VERSION ""

NS_ :

BS_:

BU_: TCM HCM IPMA_ADAS PSCM ABS_ESC TCCM TCM_DSL PCM_HEV PCM ECM_HEVDSL ECM_HEV ECM_Diesel ECM SIMA_DLCS BCMD_IPDB VDM CMR_DSMC SOBDMC_HPCM_FD1 CHCM GWM _delete AWD_DLCM GENERIC TSTR
VAL_TABLE_ _S_Off_On 1 "On" 0 "Off" ;
VAL_TABLE_ _S_InactiveActive 1 "Active" 0 "Inactive" ;
VAL_TABLE_ DcacRdy_D_Stat 7 "NotUsed_2" 6 "NotUsed_1" 5 "Faulted" 4 "ProtectionTempearture" 3 "ProtectionOverload" 2 "ProtectionGfci" 1 "Active" 0 "Idle" ;
VAL_TABLE_ HvacCmprLim_D_Stat 7 "NotUsed_2" 6 "NotUsed_1" 5 "CompressorHeadPressure" 4 "AvailableTorque" 3 "PedalPosition" 2 "RPM" 1 "ECT" 0 "NoLimit" ;
VAL_TABLE_ EvseDcChrgIso_D_Stat 7 "Faulty" 6 "NoDataExists" 5 "NotUsed_3" 4 "NotUsed_2" 3 "NotUsed_1" 2 "Valid" 1 "Warning" 0 "Invalid" ;
VAL_TABLE_ PtRmtRprt_D_Stat 15 "NotUsed_4" 14 "NotUsed_3" 13 "NotUsed_2" 12 "NotUsed_1" 11 "SettingUpdated" 10 "FastChargeComplete" 9 "ChargeNotOccurring" 8 "OneTimeSocReached" 7 "BatteryTemperatureRemind" 6 "ReducedPerformance" 5 "LimitedPerformance" 4 "ChargeFault" 3 "ChargeComplete" 2 "VehiclePreconditioned" 1 "TripDistanceAchieved" 0 "NoReportRequest" ;
VAL_TABLE_ VehOnSrc_D_Stat 15 "NotUsed_11" 14 "NotUsed_10" 13 "NotUsed_9" 12 "NotUsed_8" 11 "NotUsed_7" 10 "NotUsed_6" 9 "NotUsed_5" 8 "NotUsed_4" 7 "SecureIdle" 6 "FleetVehicleInhibit" 5 "StolenVehicleInhibit" 4 "OverTheAir" 3 "RemoteParkAssist" 2 "RemoteStart" 1 "Manual" 0 "Off" ;
VAL_TABLE_ OfbChrgSetSync_D_Rq 3 "Fail" 2 "Success" 1 "InProgress" 0 "NoSyncInProgress" ;
VAL_TABLE_ NoMessage_Msg1_63 31 "Message31" 30 "Message30" 29 "Message29" 28 "Message28" 27 "Message27" 26 "Message26" 25 "Message25" 24 "Message24" 23 "Message23" 22 "Message22" 21 "Message21" 20 "Message20" 19 "Message19" 18 "Message18" 17 "Message17" 16 "Message16" 15 "Message15" 14 "Message14" 13 "Message13" 12 "Message12" 11 "Message11" 10 "Message10" 9 "Message9" 8 "Message8" 7 "Message7" 6 "Message6" 5 "Message5" 4 "Message4" 3 "Message3" 2 "Message2" 1 "Message1" 0 "NoMessage" 63 "Message63" 47 "Message47" ;
VAL_TABLE_ TrlrRvrseEnbl_D2_Stat 7 "NotUsed" 6 "TbaActiveExpertActive" 5 "TbaActiveExpertAvail" 4 "TbaOffTrgActive" 3 "TbaOffTrgSetup" 2 "TbaSetup" 1 "TbaActive" 0 "Inactive" ;
VAL_TABLE_ Off_On_FlashChime 7 "NotUsed_5" 6 "NotUsed_4" 5 "NotUsed_3" 4 "NotUsed_2" 3 "NotUsed_1" 2 "FlashChime" 1 "On" 0 "Off" ;
VAL_TABLE_ DieslPrtcWarn_D_Rq 15 "NotUsed_4" 14 "NotUsed_3" 13 "NotUsed_2" 12 "NotUsed_1" 11 "OCR_ExhFilterClean_Stopped" 10 "OCR_ExhFilterCleaned" 9 "RgnOff_AtLimit" 8 "RgnOff_OverLoaded" 7 "RgnOff_Loaded" 6 "Exhaust_Filter_Full" 5 "DPF_OverLimit" 4 "DPF_AtLimit" 3 "ExhFilter_Drive_Completed" 2 "Cleaning_Exhaust_Filter" 1 "DPF_OverLoaded" 0 "DPF_Normal_Operation" ;
VAL_TABLE_ StrtrMtrCtlMsgTxt_D2_Rq 3 "NoRequestPcmStartingMsgCtl" 2 "ShiftToNeutralToStart" 1 "ShiftToParkToStart" 0 "NoRequestBcmStartingMsgCtl" ;
VAL_TABLE_ PaakMyKey_D_Rq 3 "NotUsed" 2 "ConfirmNewPaakMyKey" 1 "RequestNewPaakMyKey" 0 "None" ;
VAL_TABLE_ PaakMyKeySearch_D_Stat 7 "PhoneErased" 6 "LockButtonTimeOut" 5 "PressLockButton" 4 "ConfirmHmi" 3 "MyKeyPaakFound" 2 "StandardPaakFound" 1 "NoValidPaakFound" 0 "Null" ;
VAL_TABLE_ GearPrkLck_D_Stat 7 "NotUsed_1" 6 "FetLifeLimitReached" 5 "FetOpenCircuit" 4 "FetOutputShortToPower" 3 "FetOutputShortToGround" 2 "FetNotControlled" 1 "OnPowerToLoad" 0 "OffNoPowerToLoad" ;
VAL_TABLE_ DcChrgRdy_D_Stat 15 "Faulty" 14 "NotUsed_4" 13 "NotUsed_3" 12 "NotUsed_2" 11 "CableCheck" 10 "EvseFault" 9 "EvseNotCompatible" 8 "EvsePaused" 7 "GbtPrecharge" 6 "ChargeComplete" 5 "Charging" 4 "Precharge" 3 "WeldCheck" 2 "ChargeReady" 1 "Initialization" 0 "NotReady" ;
VAL_TABLE_ TrlrIdType_D_Stat 3 "Gooseneck" 2 "FifthWheel" 1 "Conventional" 0 "Null" ;
VAL_TABLE_ TrlrAidSetup_D2_Rq 15 "NotUsed_9" 14 "NotUsed_8" 13 "NotUsed_7" 12 "NotUsed_6" 11 "NotUsed_5" 10 "NotUsed_4" 9 "NotUsed_3" 8 "NotUsed_2" 7 "NotUsed_1" 6 "CompleteSetup" 5 "ReturnToSetup" 4 "StickerNotCircled" 3 "ConfirmSetup" 2 "EndSetup" 1 "BeginSetup" 0 "Inactive" ;
VAL_TABLE_ TrlrAidEnbl_D2_Rq 7 "NotUsed_4" 6 "NotUsed_3" 5 "NotUsed_2" 4 "NotUsed_1" 3 "Deactivate" 2 "ActivateTrg" 1 "ActivateTba" 0 "Inactive" ;
VAL_TABLE_ SwitchNotActive_Active 1 "Switch_Active" 0 "Switch_Not_Active" ;
VAL_TABLE_ DgtlCommGtwyMde_D_Stat 11 "NotUsed_3" 10 "DgtlCommFailed" 9 "DgtlCommEstablished" 8 "Inactive" 7 "RestartRequest" 6 "AcPnc_Eim" 5 "AcPnc" 4 "AcEim" 3 "DcPnc_Eim" 2 "DcPnc" 1 "DcEim" 0 "NotDetected" 15 "NotUsed_7" 14 "NotUsed_6" 13 "NotUsed_5" 12 "NotUsed_4" ;
VAL_TABLE_ InvalidValidWarningFaulty 3 "Faulty" 2 "Warning" 1 "Valid" 0 "Invalid" ;
VAL_TABLE_ BattChrgMde_D_Actl 3 "NotUsed" 2 "ConstantCurrent" 1 "ConstantVoltage" 0 "NotCharging" ;
VAL_TABLE_ LcwaMsgTxt_D_Stat 3 "SodXFaulty" 2 "SodXBlocked" 1 "TrailerConnected" 0 "NoMessage" ;
VAL_TABLE_ Level_0_3 3 "Level_3" 2 "Level_2" 1 "Level_1" 0 "Level_0" ;
VAL_TABLE_ SteWhlSwtchMde_D_Stat 3 "NotUsed_2" 2 "NotUsed_1" 1 "Dialog" 0 "Domain" ;
VAL_TABLE_ TrlrRvrse_D_Stat 3 "Faulty" 2 "TrailerReverseGuidanceLite" 1 "On" 0 "Off" ;
VAL_TABLE_ TrlrAid_D2_Stat 15 "Faulty" 14 "NotUsed_4" 13 "NotUsed_3" 12 "NotUsed_2" 11 "NotUsed_1" 10 "DirtyCamera" 9 "IncorrectLighting" 8 "TrackingLost" 7 "TrackingUnknownConfidence" 6 "TrackingHighConfidence" 5 "TrackingMediumConfidence" 4 "TrackingLowConfidence" 3 "TurnRequested" 2 "DriveStraighRequested" 1 "Initializing" 0 "NotTracking" ;
VAL_TABLE_ AwdDrvMde_D2 15 "Faulty" 14 "NotUsed_7" 13 "NotUsed_6" 12 "NotUsed_5" 11 "NotUsed_4" 10 "NotUsed_3" 9 "NotUsed_2" 8 "NotUsed_1" 7 "NotAvailable" 6 "TowHaul" 5 "RockCrawl" 4 "Baja" 3 "MudAndSand" 2 "Weather" 1 "Sport" 0 "Normal" ;
VAL_TABLE_ TrlrAidSetup_D2_Stat 7 "NotUsed_2" 6 "NotUsed_1" 5 "SetupAcquisitionSuccess" 4 "TbaTadMonitor" 3 "SetupStartAcquisition" 2 "SetupPrepForAcquisition" 1 "TbaActive" 0 "Null" ;
VAL_TABLE_ CamraRearOn_D2_Stat2 7 "Faulty" 6 "NotUsed_3" 5 "NotUsed_2" 4 "NotUsed_1" 3 "Decommission" 2 "Activate" 1 "Deactivate" 0 "Null" ;
VAL_TABLE_ AirCondClu_D_Stat 7 "NotUsed" 6 "FetLifeLimitReached" 5 "FetOpenCircuit" 4 "FetOutputShortToPower" 3 "FetOutputShortToGround" 2 "FetNotControlled" 1 "OnPowerToLoad" 0 "OffNoPowerToLoad" ;
VAL_TABLE_ BattChrgTrgtSoC_D_Rq 7 "Percent_50" 6 "Percent_60" 5 "Percent_70" 4 "Percent_80" 3 "Percent_85" 2 "Percent_90" 1 "Percent_95" 0 "Percent_100" ;
VAL_TABLE_ OffNormalSoft 3 "NotUsed" 2 "Soft" 1 "Normal" 0 "Off" ;
VAL_TABLE_ OffOnDisabledInhibited 3 "Inhibited" 2 "Disabled" 1 "On" 0 "Off" ;
VAL_TABLE_ DgtlCommGtwyMde_D_Rq 15 "NotUsed_10" 14 "NotUsed_9" 13 "NotUsed_8" 12 "NotUsed_7" 11 "NotUsed_6" 10 "NotUsed_5" 9 "NotUsed_4" 8 "NotUsed_3" 7 "NotUsed_2" 6 "NotUsed_1" 5 "AcPnC" 4 "AcEIM" 3 "DcPnC" 2 "DcEIM" 1 "AttemptDgtlComm" 0 "NoDgtlComm" ;
VAL_TABLE_ BattDcCnnct_D_Cmd 7 "NotUsed_3" 6 "NotUsed_2" 5 "NotUsed_1" 4 "WeldCheck" 3 "OkToDischarge" 2 "Closed" 1 "Precharge" 0 "Open" ;
VAL_TABLE_ Null_NoFault_Fault 3 "NotUsed" 2 "Fault" 1 "NoFault" 0 "Null" ;
VAL_TABLE_ ModemReset_D_Stat 15 "NotUsed_10" 14 "NotUsed_9" 13 "NotUsed_8" 12 "NotUsed_7" 11 "NotUsed_6" 10 "NotUsed_5" 9 "NotUsed_4" 8 "NotUsed_3" 7 "NotUsed_2" 6 "NotUsed_1" 5 "WifiHotSpotResetComplete" 4 "CcsResetComplete" 3 "OnlineTrafficResetComplete" 2 "PaakResetComplete" 1 "ResetNotComplete" 0 "Null" ;
VAL_TABLE_ ModemReset_D_Rq 15 "NotUsed_11" 14 "NotUsed_10" 13 "NotUsed_9" 12 "NotUsed_8" 11 "NotUsed_7" 10 "NotUsed_6" 9 "NotUsed_5" 8 "NotUsed_4" 7 "NotUsed_3" 6 "BrandConnectReset2" 5 "BrandConnectReset1" 4 "CcsReset" 3 "OnlineTrafficReset" 2 "PaakReset" 1 "WifiHotspotReset" 0 "Null" ;
VAL_TABLE_ RstrnOnPsngr_D_RqMnu 15 "Faulty" 14 "NotUsed_11" 13 "NotUsed_10" 12 "ConfiguredOff" 11 "NotUsed_9" 10 "On" 9 "NotUsed_8" 8 "NotUsed_7" 7 "NotUsed_6" 6 "NotUsed_5" 5 "Off" 4 "NotUsed_4" 3 "NotUsed_3" 2 "NotUsed_2" 1 "NotUsed_1" 0 "NoAction" ;
VAL_TABLE_ NoReq_AutoUp_Stop 3 "NotUsed" 2 "Stop" 1 "AutoUp" 0 "NoRequest" ;
VAL_TABLE_ BalrSnsLeft_D_Falt 3 "Invalid" 2 "SystemFailure" 1 "Blocked" 0 "Clear" ;
VAL_TABLE_ Null_Low_Med_High 3 "High" 2 "Medium" 1 "Low" 0 "Null" ;
VAL_TABLE_ Null_NotPressed_Pressed 3 "NotUsed" 2 "Pressed" 1 "NotPressed" 0 "Null" ;
VAL_TABLE_ Low_Med_High 3 "NotUsed" 2 "High" 1 "Medium" 0 "Low" ;
VAL_TABLE_ Null_NotAvail_Avail 3 "NotUsed" 2 "Available" 1 "NotAvailable" 0 "Null" ;
VAL_TABLE_ ChrgToPcWkndSav_D_Stat 7 "Percent_50" 6 "Percent_60" 5 "Percent_70" 4 "Percent_80" 3 "Percent_85" 2 "Percent_90" 1 "Percent_95" 0 "Percent_100" ;
VAL_TABLE_ ChrgGoTMnte_D_Stat 15 "NotUsed_4" 14 "NotUsed_3" 13 "NotUsed_2" 12 "NotUsed_1" 11 "Minute_55" 10 "Minute_50" 9 "Minute_45" 8 "Minute_40" 7 "Minute_35" 6 "Minute_30" 5 "Minute_25" 4 "Minute_20" 3 "Minute_15" 2 "Minute_10" 1 "Minute_5" 0 "Minute_0" ;
VAL_TABLE_ NoData_Faulty_1E_1F 31 "Faulty" 30 "NoDataExists" ;
VAL_TABLE_ PwFlwBatt_D_Dsply 15 "NotUsed_8" 14 "NotUsed_7" 13 "NotUsed_6" 12 "NotUsed_5" 11 "NotUsed_4" 10 "NotUsed_3" 9 "NotUsed_2" 8 "NotUsed_1" 7 "FlwFromWallToBatt" 6 "FlwFromAllWhlsToBatt" 5 "FlwFromBattToAllWhls" 4 "FlwFromFrontWhlsToBatt" 3 "FlwFromBattToFrontWhls" 2 "FlwFromRearWhlsToBatt" 1 "FlwFromBattToRearWhls" 0 "NoFlow" ;
VAL_TABLE_ PwFlwFuelDrv_D_Dsply 7 "NotUsed_4" 6 "NotUsed_3" 5 "NotUsed_2" 4 "NotUsed_1" 3 "FlwFromFuelToAllWhls" 2 "FlwFromFuelToFrontWhls" 1 "FlwFromFuelToRearWhls" 0 "NoFlow" ;
VAL_TABLE_ TrlrAidMsgTxt_D2_Rq 63 "Message63" 62 "Message62" 61 "Message61" 60 "Message60" 55 "Message55" 50 "Message50" 45 "Message45" 40 "Message40" 35 "Message35" 31 "Message31" 30 "Message30" 29 "Message29" 28 "Message28" 27 "Message27" 26 "Message26" 25 "Message25" 24 "Message24" 23 "Message23" 22 "Message22" 21 "Message21" 20 "Message20" 19 "Message19" 18 "Message18" 17 "Message17" 16 "Message16" 15 "Message15" 14 "Message14" 13 "Message13" 12 "Message12" 11 "Message11" 10 "Message10" 9 "Message9" 8 "Message8" 7 "Message7" 6 "Message6" 5 "Message5" 4 "Message4" 3 "Message3" 2 "Message2" 1 "Message1" 0 "NoMessage" ;
VAL_TABLE_ TrlrAidEnbl_D2_Stat 7 "NotUsed_1" 6 "TbaActiveExpertActive" 5 "TbaActiveExpertAvail" 4 "TbaOffTrgActive" 3 "TbaOffTrgSetup" 2 "TbaSetup" 1 "TbaActive" 0 "Inactive" ;
VAL_TABLE_ NoRequest_Mode1_2_3 3 "Mode_3" 2 "Mode_2" 1 "Mode_1" 0 "NoRequest" ;
VAL_TABLE_ RvltnMatchAllw_D_Stat 3 "RevolutionMatchDisabled" 2 "RevolutionMatchEnabled" 1 "ChangeWithDriveMode" 0 "NoSelection" ;
VAL_TABLE_ BattTracCnnct_D_Cmd 7 "NotUsed_3" 6 "NotUsed_2" 5 "NotUsed_1" 4 "WeldCheck" 3 "OkToDischarge" 2 "Closed" 1 "Precharge" 0 "Open" ;
VAL_TABLE_ NotDiagnose_FailPass 3 "NotUsed" 2 "Pass" 1 "Fail" 0 "Not_Diagnose_Yet" ;
VAL_TABLE_ Null_Off_UnavailFaulty 3 "Faulty" 2 "Unavailable" 1 "Off" 0 "Null" ;
VAL_TABLE_ OffOnDisabledNotUsed 3 "NotUsed" 2 "Disabled" 1 "On" 0 "Off" ;
VAL_TABLE_ OffGraphicTextBoth 3 "Both" 2 "Text" 1 "Graphic" 0 "Off" ;
VAL_TABLE_ NoneInactiveActive_NotUsed 3 "NotUsed" 2 "Active" 1 "Inactive" 0 "None" ;
VAL_TABLE_ Off_On_NotUsed 3 "NotUsed_2" 2 "NotUsed_1" 1 "On" 0 "Off" ;
VAL_TABLE_ OffNoPowerToLoad 7 "NotUsed_1" 6 "FetLifeLimitReached" 5 "FetOpenCircuit" 4 "FetOutputShortToPower" 3 "FetOutputShortToGround" 2 "FetNotControlled" 1 "OnPowerToLoad" 0 "OffNoPowerToLoad" ;
VAL_TABLE_ BrkAppl_D_RqPt 3 "BrakesSlowRelease" 2 "BrakesFastRelease" 1 "BrakesEngage" 0 "NotActive" ;
VAL_TABLE_ Mtr2State_D_ActlMntr 7 "Faulty" 6 "NoDataExists" 5 "NotUsed_1" 4 "ReadinessState" 3 "DeactivationState" 2 "PowerGeneration" 1 "PowerConsumption" 0 "Null" ;
VAL_TABLE_ HybVehMde_D_ActlMntr 7 "Faulty" 6 "NoDataExists" 5 "NotUsed_2" 4 "NotUsed_1" 3 "Fuel" 2 "HybridElectric" 1 "AllElectric" 0 "Null" ;
VAL_TABLE_ ChrgStat_D_ActlMntr 7 "Faulty" 6 "NoDataExists" 5 "NotUsed" 4 "ChargingCompleted" 3 "NotCharging" 2 "ChargingInDrivingState" 1 "ChargingInParkingState" 0 "Null" ;
VAL_TABLE_ Inactive_Enable_Disable_NotUsed 0 "Inactive" 2 "Disable" 1 "Enable" ;
VAL_TABLE_ Null_NotPressed_Faulty 3 "Faulty" 2 "Pressed" 1 "NotPressed" 0 "Null" ;
VAL_TABLE_ Null_Off_LowMedHigh 7 "NotUsed_3" 6 "NotUsed_2" 5 "NotUsed_1" 4 "High" 3 "Medium" 2 "Low" 1 "Off" 0 "Null" ;
VAL_TABLE_ TrailCtl_D_Stat 7 "Faulty" 6 "DescentOnly" 5 "EnabledDeny" 4 "StandbyOverThreshold" 3 "StandbyOverride" 2 "Active" 1 "EnabledDescent" 0 "Off" ;
VAL_TABLE_ Faulty_3F 63 "Faulty" ;
VAL_TABLE_ ChrgOvrdExitScrn_D_Rq 3 "NotUsed_1" 2 "Request_override" 1 "Do_not_request_override" 0 "Inactive" ;
VAL_TABLE_ Quality_Data_Faulty 3 "OK" 2 "Not_Within_Specifications" 1 "Eval_In_Progress" 0 "Faulty" ;
VAL_TABLE_ TrlrHitchYaw_D_Stat 15 "Faulty" 14 "NotUsed_4" 13 "NotUsed_3" 12 "NotUsed_2" 11 "NotUsed_1" 10 "FaultyYrsuConnection" 9 "FaultyYrsu" 8 "HiConfdLrndAngle" 7 "LowConfdLrndAngle" 6 "HiConfdAngleMem" 5 "LowConfdAngleMem" 4 "InitNoTadAngle" 3 "InitInputs" 2 "TadTrlrDataOutOfRange" 1 "TadNotWithinSpecification" 0 "NoConnectionWithYrsu" ;
VAL_TABLE_ NoData_Faulty_FFFFFFFFFFFE_FF -1 "Faulty_FFFFFFFFFFFF" -2 "NoDataExists_FFFFFFFFFFFE" ;
VAL_TABLE_ AirAmbTePlgIn_D_Dsply 3 "NotUsed" 2 "Hot_Outside_Plg_In_Msg" 1 "Cold_Outside_Plg_In_Msg" 0 "No_Plg_In_Msg" ;
VAL_TABLE_ NoFault_Fault 1 "Fault" 0 "No_Fault" ;
VAL_TABLE_ OtaTrg_D_Stat 3 "NotUsed_1" 2 "Accepted" 1 "NotAccepted" 0 "Null" ;
VAL_TABLE_ EdmMsgTxt_D_Rq 15 "NotUsed_4" 14 "NotUsed_3" 13 "NotUsed_2" 12 "NotUsed_1" 11 "OverallGoodScore" 10 "WorkOnCompliance" 9 "GoodCompliance" 8 "WorkOnGearShifting" 7 "GoodGearShifting" 6 "WorkOnEfficientSpeed" 5 "GoodEfficientSpeed" 4 "WorkOnDeceleration" 3 "GoodDeceleration" 2 "WorkOnAcceleration" 1 "GoodAcceleration" 0 "NoMessage" ;
VAL_TABLE_ EdmLamp_D_Dsply 15 "NotUsed_7" 14 "NotUsed_6" 13 "NotUsed_5" 12 "NotUsed_4" 11 "NotUsed_3" 10 "NotUsed_2" 9 "NotUsed_1" 8 "CoastingEngineBrake" 7 "CoastingShiftToNeutral" 6 "FreewayJunction" 5 "Curve2" 4 "Curve1" 3 "SpeedLimit" 2 "Crossing" 1 "FreewayExit" 0 "NoRecommendation" ;
VAL_TABLE_ AwdCnnct_D_Stat 3 "Connecting" 2 "Disconnecting" 1 "Connected" 0 "Disconnected" ;
VAL_TABLE_ EngAirFiltMsgTxt_D_Rq 7 "NotUsed_2" 6 "NotUsed_1" 5 "EngineAirFilterMonitorFalt" 4 "ResetComplete" 3 "Clogged" 2 "ReplaceNow" 1 "ReplaceSoon" 0 "NoMessage" ;
VAL_TABLE_ ElPwPoint_D_Rq 3 "On" 2 "Off2" 1 "Off1" 0 "Null" ;
VAL_TABLE_ EngExhMdeQuiet_D2_Rq 7 "NotUsed_3" 6 "NotUsed_2" 5 "NotUsed_1" 4 "Track" 3 "Sport" 2 "Normal" 1 "Stealth" 0 "Null" ;
VAL_TABLE_ RearDiffThrml_D_Stat 3 "NotUsed_1" 2 "AboveThermalLimit" 1 "ThermalLimit" 0 "Normal" ;
VAL_TABLE_ NoInhibit_Inhibit 1 "Inhibit" 0 "NoInhibit" ;
VAL_TABLE_ PersRecallSrc_D_Actl 7 "NotUsed_3" 6 "NotUsed_2" 5 "NotUsed_1" 4 "MemorySwitch" 3 "RemoteStart" 2 "KeyFob" 1 "CenterStack" 0 "Null" ;
VAL_TABLE_ BattTracChiller_D_Stat 3 "NotUsed" 2 "ChillerNotAvailable" 1 "ChillerBrieflyAvailable" 0 "ChillerAvailable" ;
VAL_TABLE_ VehShutDownMsgTxt_D_Rq 3 "NotUsed" 2 "ProhibitedRestart" 1 "ShutdownWarning" 0 "NoMessage" ;
VAL_TABLE_ Audio_Visualizer 2 "On" 1 "Off" 0 "Inactive" ;
VAL_TABLE_ Audio_Demo_CMND 2 "On" 1 "Off" 0 "Inactive" ;
VAL_TABLE_ LongTermParking_Rq 2 "On" 1 "Off" 0 "Inactive" ;
VAL_TABLE_ StopoverType_D_Stat 7 "Faulty" 6 "NotUsed_1" 5 "Other" 4 "Work" 3 "Home" 2 "ChargeStation" 1 "FinalDestination" 0 "Null" ;
VAL_TABLE_ NoData_Faulty_3FFFE_3FFFF 262143 "Faulty" 262142 "NoDataExists" ;
VAL_TABLE_ AwdStat2_D_RqDsply 31 "NotUsed_29" 30 "NotUsed_28" 29 "NotUsed_27" 28 "NotUsed_26" 27 "NotUsed_25" 26 "NotUsed_24" 25 "NotUsed_23" 24 "NotUsed_22" 23 "NotUsed_21" 22 "NotUsed_20" 21 "NotUsed_19" 20 "NotUsed_18" 19 "NotUsed_17" 18 "NotUsed_16" 17 "NotUsed_15" 16 "NotUsed_14" 15 "NotUsed_13" 14 "NotUsed_12" 13 "NotUsed_11" 12 "NotUsed_10" 11 "NotUsed_9" 10 "NotUsed_8" 9 "NotUsed_7" 8 "NotUsed_6" 7 "NotUsed_5" 6 "NotUsed_4" 5 "NotUsed_3" 4 "NotUsed_2" 3 "HillHoldFail" 2 "TCaseOilChanged" 1 "ChangeTCaseOil" 0 "Normal" ;
VAL_TABLE_ BattAuxCnnct_D_Cmd 7 "NotUsed_3" 6 "NotUsed_2" 5 "NotUsed_1" 4 "WeldCheck" 3 "OkToDischarge" 2 "Closed" 1 "Precharge" 0 "Open" ;
VAL_TABLE_ NoRequest_Reset_Disable 3 "NotUsed" 2 "Disable" 1 "Reset" 0 "NoRequest" ;
VAL_TABLE_ DteVehOffstMsgTxt_D_Rq 15 "NotUsed_7" 14 "NotUsed_6" 13 "NotUsed_5" 12 "NotUsed_4" 11 "NotUsed_3" 10 "NotUsed_2" 9 "NotUsed_1" 8 "PowerToTheBox" 7 "Payload" 6 "TrailerTowing_Off" 5 "TrailerTowing_On" 4 "TrafficAlongRoute" 3 "ExternalTemperature" 2 "HillyTerrain" 1 "DestinationRoute" 0 "NoMessage" ;
VAL_TABLE_ TrlrAlarmSpprt_D_Stat 3 "SupportedByBrakesAndLights" 2 "SupportedByLights" 1 "SupportedByBrakes" 0 "NotSupported" ;
VAL_TABLE_ Null_InProcess_Complete 3 "NotUsed" 2 "Complete" 1 "InProcess" 0 "Null" ;
VAL_TABLE_ TrailOnePdlMde_D_Ind 7 "NotUsed_4" 6 "NotUsed_3" 5 "NotUsed_2" 4 "NotUsed_1" 3 "Standby" 2 "Active" 1 "Fault" 0 "Off" ;
VAL_TABLE_ OBCCSerial_D_Rq 3 "PresentAndProvisioned" 2 "PresentAndProvAlertAck" 1 "PresentAndUnprovisioned" 0 "NotPresent" ;
VAL_TABLE_ DsmcMsgTxt_D_Dsply 3 "Blockage" 2 "DriverNotSeen" 1 "Fault" 0 "NoMessage" ;
VAL_TABLE_ DgtlCommPnc_D_Stat 7 "Faulty" 6 "NotUsed_3" 5 "NotUsed_2" 4 "NotUsed_1" 3 "Enable" 2 "Disable" 1 "NoContractsInstalled" 0 "Null" ;
VAL_TABLE_ TlghtTest_D_Stat 3 "InProgress" 2 "Ended" 1 "Completed" 0 "Null" ;
VAL_TABLE_ TlghtTestPrecnd_D_Stat 7 "Error" 6 "NotStationary" 5 "InteractionPresent" 4 "PreconditionsPassed" 3 "BattSocLessThan75Percent" 2 "TailLightsOn" 1 "IgnitionNotOn" 0 "Null" ;
VAL_TABLE_ TlghtTestLght_D_Stat 7 "Error" 6 "AllOff" 5 "TestingReverseLights" 4 "TestingBrakeLights" 3 "TestingLeftTurnSignal" 2 "TestingRightTurnSignal" 1 "ParkingLightsIlluminated" 0 "Null" ;
VAL_TABLE_ TlightTest_D_Rq 3 "TestEndAcknowledge" 2 "StartTest" 1 "StopTest" 0 "Null" ;
VAL_TABLE_ NoFaultFaultTemporary 3 "NotUsed" 2 "TemporaryFault" 1 "Fault" 0 "NoFault" ;
VAL_TABLE_ ScDayOfWeekId_D_Stat 7 "Sunday" 6 "Saturday" 5 "Friday" 4 "Thursday" 3 "Wednesday" 2 "Tuesday" 1 "Monday" 0 "NotUsed" ;
VAL_TABLE_ Null_Disabled_Enabled 3 "NotUsed" 2 "Enabled" 1 "Disabled" 0 "Null" ;
VAL_TABLE_ LghtAmbDrvMde_B_Stat 1 "Automatic" 0 "Manual" ;
VAL_TABLE_ LghtAmbDrvMde_D_Rq 3 "NotUsed" 2 "Automatic" 1 "Manual" 0 "Null" ;
VAL_TABLE_ NullMphKph 3 "NotUsed" 2 "Kph" 1 "Mph" 0 "Null" ;
VAL_TABLE_ NotUsedMonday_Sunday 7 "Sunday" 6 "Saturday" 5 "Friday" 4 "Thursday" 3 "Wednesday" 2 "Tuesday" 1 "Monday" 0 "NotUsed" ;
VAL_TABLE_ GoTEditMnte_T_RqMnu 15 "Faulty" 14 "NoDataExists" 13 "NotUsed_2" 12 "NotUsed_1" 11 "Minute_55" 10 "Minute_50" 9 "Minute_45" 8 "Minute_40" 7 "Minute_35" 6 "Minute_30" 5 "Minute_25" 4 "Minute_20" 3 "Minute_15" 2 "Minute_10" 1 "Minute_5" 0 "Minute_0" ;
VAL_TABLE_ PwPckTqRdyChime_B_Rq 3 "NotUsed" 2 "Shutdown" 1 "Startup" 0 "Null" ;
VAL_TABLE_ BattTracLoThres_D_Stat 7 "NotUsed" 6 "Thres80km_50mi" 5 "Thres50km_31mi" 4 "Thres30km_18mi" 3 "Thres50mi_80km" 2 "Thres30mi_48km" 1 "Thres20mi_32km" 0 "Null" ;
VAL_TABLE_ BattTracLoMsgTxt_D_Rq 7 "NotUsed_2" 6 "NotUsed_1" 5 "ZeroDteBatteryDepleted" 4 "ClimateLowDteSecondAlert" 3 "ClimateLowDteFirstAlert" 2 "LowDteSecondAlert" 1 "LowDteFirstAlert" 0 "Null" ;
VAL_TABLE_ OffOnSuspendedFaulty 3 "Faulty" 2 "Suspended" 1 "On" 0 "Off" ;
VAL_TABLE_ BattTracLoSoc_D_Dsply 3 "NotUsed" 2 "ZeroDteDepletedBattery" 1 "LoDte" 0 "Null" ;
VAL_TABLE_ DgtlCommGtwy_D_Falt 127 "NotUsed_63" 65 "NotUsed_1" 64 "EvseGbtCommTimeout" 63 "EvseGbtCrgVoltMismatch" 62 "EvseGbtChrgCurrntMismatch" 61 "EvseGbtOtherFalt" 60 "EvseGbtEmergShutdown" 59 "EvseGbtEnergyTransFalt" 58 "EvseGbtIntOverTemp" 57 "EvseGbtConnectorFalt" 56 "EvseGbtOverTemp" 55 "EvseResCpsRootCaCertRev" 54 "EvseResSubCA2CertRev" 53 "EvseResSubCA1CertRev" 52 "EvseResCpsProvCertRev" 51 "EvseResRootCaCertRev" 50 "EvseResMoSubCa2CertRev" 49 "EvseResMoSubCa1CertRev" 48 "EvseResMoProvCertRev" 47 "EvseResOemSubCa2CertRev" 46 "EvseResOemSubCa1CertRev" 45 "EvseResOemProvCertRev" 44 "EvseResMoUnknown" 43 "EvseResContractNotAccept" 42 "EvseResNoSuppAppProt" 41 "EvseResCertNotAllowed" 40 "EvseResContractErr" 39 "EvseResNoChrgSvcSelect" 38 "EvseResMeterSignNotVld" 37 "EvseResPwrDelNotApplied" 36 "EvseResTrfSelectInvld" 35 "EvseResChrgProfileInvld" 34 "EvseResWrongChrgParam" 33 "EvseResWrongEnrgyTransMde" 32 "EvseResChlgInvld" 31 "EvseResContractCancel" 30 "EvseResCertChainErr" 29 "EvseResNoCertAvail" 28 "EvseResCertRvk" 27 "EvseResCertExp" 26 "EvseResPymtSelectInvld" 25 "EvseResSvcldInvld" 24 "EvseResUnknownSession" 23 "EvseResSignErr" 22 "EvseResSeqErr" 21 "EvseResFailed" 20 "EvsePreChrgTimeout" 19 "EvseCableCheckTimeout" 18 "EvseCommSetupTimeout" 17 "EvseMsgTimeout" 16 "EvseTlsUnknownCA" 15 "EvseTlsCertExpired" 14 "EvseTlsBadCert" 13 "EvseTlsHandshakeFail" 12 "EvseTlsDecryptFail" 11 "EvseTlsBadRecordMac" 10 "EvseTlsUnexpectedMsg" 9 "EvseTlsFail" 8 "EvseTcpCnnctFail" 7 "EvseUpdErr" 6 "EvseSlaacErr" 5 "EvseStopNotification" 4 "EvseMalfunction" 3 "EvseEmergShutdown" 2 "EvseStatUtilityIntrpt" 1 "EvseStatShutdown" 0 "NoFault" ;
VAL_TABLE_ KeyPadCodeDgt1_D_Stat 15 "NotUsed_4" 14 "NotUsed_3" 13 "NotUsed_2" 12 "NotUsed_1" 11 "Button7_8and9_0" 10 "Button0" 9 "Button9_0or9" 8 "Button8" 7 "Button7_8or7" 6 "Button6" 5 "Button5_6or5" 4 "Button4" 3 "Button3_4or3" 2 "Button2" 1 "Button1_2or1" 0 "EndofString" ;
VAL_TABLE_ OrtaMde_D_Ind 7 "Faulty" 6 "NotUsed_2" 5 "NotUsed_1" 4 "ActiveRight" 3 "ActiveLeft" 2 "StandbyRight" 1 "StandbyLeft" 0 "Off" ;
VAL_TABLE_ SelDrvMdeChassis2_D_Rq 31 "Faulty" 30 "NotUsed17" 29 "NotUsed16" 28 "NotUsed15" 27 "NotUsed14" 26 "NotUsed13" 25 "NotUsed12" 24 "NotUsed11" 23 "NotUsed10" 22 "NotUsed9" 21 "NotUsed8" 20 "NotUsed7" 19 "NotUsed6" 18 "NotUsed5" 17 "NotUsed4" 16 "OnePedalDrive" 15 "DragMode" 14 "RoughRoadMode" 13 "TrackMode" 12 "HighSpeedDesertMode" 11 "TowHaulMode" 10 "RockCrawlMode" 9 "SandMode" 8 "MudAndRutsMode" 7 "LowMuMode" 6 "ComfortAdaptiveMode" 5 "ComfortMode" 4 "SportAdaptiveMode" 3 "SportMode" 2 "EconomyMode" 1 "NormalAdaptiveMode" 0 "NormalMode" ;
VAL_TABLE_ TrnFaltOpenClu_B_Stat 1 "MayOpenClutch" 0 "Normal" ;
VAL_TABLE_ Closed_Open 1 "Open" 0 "Closed" ;
VAL_TABLE_ FactoryReset_St 3 "NotUsed_2" 2 "NotUsed_1" 1 "FactoryDefaultsRestored" 0 "Null" ;
VAL_TABLE_ CCOI_Policy 15 "NotUsed_4" 14 "NotUsed_3" 13 "NotUsed_2" 12 "NotUsed_1" 11 "DataStorageError" 10 "StateMachineInconsistent" 9 "UnrecoverableSyncError" 8 "On BoardSyncFailed" 7 "OnBoardImplemented" 6 "OnBoardSynchronized" 5 "OnBoardSynchronizing" 4 "OnBoardSyncNeeded" 3 "OffBoardUpdatePending" 2 "OnBoardUpdatePending" 1 "Waiting" 0 "Null" ;
VAL_TABLE_ TelematicsSrvc_D_St 7 "NotUsed" 6 "NotifyNotActivatedYet" 5 "NotActivatedYet" 4 "NotifyExpired" 3 "Expired" 2 "ExpiringSoon" 1 "Active" 0 "Null" ;
VAL_TABLE_ TCU_ESN_D_Rq 3 "NotUsed" 2 "TCU_ESN_Request" 1 "NoRequest" 0 "Inactive" ;
VAL_TABLE_ FactoryReset_Rq 1 "ResetFactoryDefaults" 0 "Inactive" ;
VAL_TABLE_ TCU_Init_Actvtn_St 3 "NotUsed" 2 "InitialActivateDeny" 1 "InitialActivateAccept" 0 "Invalid" ;
VAL_TABLE_ TCU_Final_Actvtn_St 3 "NotUsed" 2 "FinalActivateDeny" 1 "FinalActivateAccept" 0 "Invalid" ;
VAL_TABLE_ Null_Disable_Enable 3 "NotUsed" 2 "Enable" 1 "Disable" 0 "Null" ;
VAL_TABLE_ WaitToStartLamp_D_Falt 3 "NotUsed" 2 "Wait_to_start_lamp_failed" 1 "Diagnosis_not_ready" 0 "Wait_to_start_lamp_OK" ;
VAL_TABLE_ AirSuspLoading_D_Stat 7 "Faulty" 6 "MeasurementInProgress" 5 "Overload_2" 4 "Overload_1" 3 "FullyLoaded" 2 "MediumLoaded" 1 "LightLoaded" 0 "LoadNotDetermined" ;
VAL_TABLE_ BattTracCoolLvl_D_Rq 7 "Faulty" 6 "NotUsed" 5 "ChillerCoolingBattFirst" 4 "ChillerCoolingCabinFirst" 3 "ForcedCoolingRadiator" 2 "OpportunisticCoolingRad" 1 "CoolantFlowBypassLine" 0 "Off" ;
VAL_TABLE_ BattClntVlvOvrrd_D_Rq 3 "NotUsed" 2 "OverrideTbcvToChiller" 1 "OverrideTbcvToRadiator" 0 "NoOverrideToTbcvCLogic" ;
VAL_TABLE_ NonMagnetic_Magnetic 1 "Magnetic" 0 "NonMagnetic" ;
VAL_TABLE_ RideHghtMde_D_Stat 15 "Faulty" 14 "NotUsed_5" 13 "NotUsed_4" 12 "NotUsed_3" 11 "NotUsed_2" 10 "NotUsed_1" 9 "AdjUpAero" 8 "AdjUpOffRoad" 7 "AdjUpNormal" 6 "AdjDownKneel" 5 "AdjDownAero" 4 "AdjDownNormal" 3 "OffRoad" 2 "Kneel" 1 "Aero" 0 "Normal" ;
VAL_TABLE_ AutoTowAllw_D_StatMnu 3 "TowHaulCommandedOn" 2 "AutoTowHaulEnabled" 1 "AutoTowHaulDisabled" 0 "NoSelection" ;
VAL_TABLE_ SrpEventRight_D_Stat 3 "Faulty" 2 "Bump" 1 "Pothole" 0 "NoEvent" ;
VAL_TABLE_ RearDiff_D_Stat 15 "NotUsed_7" 14 "NotUsed_6" 13 "NotUsed_5" 12 "NotUsed_4" 11 "NotUsed_3" 10 "NotUsed_2" 9 "NotUsed_1" 8 "TorqueReqNotHonored" 7 "MissingSignal" 6 "ModuleFault" 5 "HydroTempSensorFault" 4 "ClutchPressSensorFault" 3 "AccumPressSensorFault" 2 "ControlValveFault" 1 "MotorFault" 0 "Normal" ;
VAL_TABLE_ NotAllowed_Allowed 1 "Allowed" 0 "NotAllowed" ;
VAL_TABLE_ EngTrlrCnnct_D_Stat 3 "NotUsed_1" 2 "UnverifiedTrailer" 1 "HeavyTrailer" 0 "NoTrailer" ;
VAL_TABLE_ Faulty_FFFF 65535 "Faulty" ;
VAL_TABLE_ NoData_Faulty_3FFE_3FFF 16383 "Faulty" 16382 "NoDataExists" ;
VAL_TABLE_ Faulty_3FFF 16383 "Faulty" ;
VAL_TABLE_ NotAsserted_Asserted 1 "Asserted" 0 "NotAsserted" ;
VAL_TABLE_ AirSprngRate_D_Stat 3 "Faulty" 2 "Firm" 1 "Medium" 0 "Soft" ;
VAL_TABLE_ AirSprngRate_D_Rq 3 "NoRequest" 2 "Firm" 1 "Medium" 0 "Soft" ;
VAL_TABLE_ GearLvr_D_ActlDrv 15 "Fault" 14 "Unknown_Position" 13 "NotUsed_2" 12 "NotUsed_1" 11 "Range6" 10 "Range5" 9 "Range4" 8 "Range3_M3_L3" 7 "Range2_M2_L2" 6 "Range1_M1_L1" 5 "Low" 4 "Sport_DriveSport_Mposition" 3 "Drive" 2 "Neutral" 1 "Reverse" 0 "Park" ;
VAL_TABLE_ ChrgrInPwMde_D_Actl 15 "NotUsed_9" 14 "NotUsed_8" 13 "NotUsed_7" 12 "NotUsed_6" 11 "NotUsed_5" 10 "NotUsed_4" 9 "DigitalCommEnd" 8 "EvseFault" 7 "EvseNotCompatible" 6 "IcCharging" 5 "DcCharging" 4 "AcDigital" 3 "AcBasic" 2 "DigitalCommDetected" 1 "EvsePaused" 0 "EvseNotDetected" ;
VAL_TABLE_ ChrgCordLck_D_Stat 7 "Faulty" 6 "LockFail" 5 "UnlockFail" 4 "LockInProgress" 3 "UnlockInProgress" 2 "Lock" 1 "Unlock" 0 "Retain" ;
VAL_TABLE_ LkaActvStats_D2_Req 7 "NotUsed" 6 "LkaIncrIntervRight" 5 "LkaSupprRight" 4 "LkaStandIntervRight" 3 "LkaSupprLeft" 2 "LkaStandIntervLeft" 1 "LkaIncrIntervLeft" 0 "LkaNoInterv" ;
VAL_TABLE_ OffOnNoDataFaulty 3 "Faulty" 2 "No_Data_Exists" 1 "On" 0 "Off" ;
VAL_TABLE_ NoMessage_Msg1_3 3 "Message3" 2 "Message2" 1 "Message1" 0 "NoMessage" ;
VAL_TABLE_ TrnRng_D_RqGsm 15 "Fault" 14 "UnknownPosition" 13 "Undefined_2" 12 "Undefined_1" 11 "_6" 10 "_5" 9 "_4" 8 "_3" 7 "_2" 6 "_1" 5 "Low" 4 "Sport_DriveSport" 3 "Drive" 2 "Neutral" 1 "Reverse" 0 "Park" ;
VAL_TABLE_ PrkBrkActv_D_RqGsmGear 3 "NotUsed" 2 "RequestParkBrakeEngage" 1 "NoRequest" 0 "Null" ;
VAL_TABLE_ TrnPrkSys_D_Actl 15 "Faulty" 14 "NotUsed_5" 13 "NotUsed_4" 12 "NotUsed_3" 11 "NotUsed_2" 10 "NotUsed_1" 9 "FrequencyError" 8 "OutOfRangeHigh" 7 "OutOfRangeLow" 6 "Override" 5 "OutOfPark" 4 "TransitionCloseToOutOfPark" 3 "AtNoSpring" 2 "TransitionCloseToPark" 1 "Park" 0 "NotKnown" ;
VAL_TABLE_ OKLowUnknownInvalid 3 "Invalid" 2 "Unknown" 1 "Low" 0 "OK" ;
VAL_TABLE_ Dsp_RotAddrBtnEv_St 15 "NotUsed_1" 14 "Pos_7Steps" 13 "Pos_6Steps" 12 "Pos_5Steps" 11 "Pos_4Steps" 10 "Pos_3Steps" 9 "Pos_2Steps" 8 "Pos_1Step" 7 "NotPressed" 6 "Neg_1Steps" 5 "Neg_2Steps" 4 "Neg_3Steps" 3 "Neg_4Steps" 2 "Neg_5Steps" 1 "Neg_6Steps" 0 "Neg_7Steps" ;
VAL_TABLE_ PrkAidDrvDir_D_Stat 7 "NotUsed_2" 6 "NotUsed_1" 5 "BackwardNegative" 4 "ForwardNegative" 3 "BackwardPositive" 2 "ForwardPositive" 1 "NoMotion" 0 "DirectionNotKnown" ;
VAL_TABLE_ EngExhMdeQuiet_D2_Stat 7 "Faulty" 6 "NotUsed_2" 5 "NotUsed_1" 4 "Track" 3 "Sport" 2 "Normal" 1 "Stealth" 0 "Null" ;
VAL_TABLE_ GasPrtc_D_RqDsply 7 "NotUsed_5" 6 "NotUsed_4" 5 "NotUsed_3" 4 "NotUsed_2" 3 "NotUsed_1" 2 "GpfOverLimit" 1 "GpfAtLimit" 0 "NormalOperation" ;
VAL_TABLE_ TjaWarn_D_Rq 7 "HardTakeOverEyesOff" 6 "SoftTakeOverEyesOff" 5 "HaLaneDeptWarningLeft" 4 "HaLaneDeptWarningRight" 3 "HardTakeOverLevel2" 2 "HardTakeOverLevel1" 1 "TrafficJamAssistCancel" 0 "NoWarning" ;
VAL_TABLE_ Faulty_7FF 2047 "Faulty" ;
VAL_TABLE_ Tja_D_Stat 7 "ExtendedActive" 6 "ActiveWarningRight" 5 "ActiveWarningLeft" 4 "ActiveInterventionRight" 3 "ActiveInterventionLeft" 2 "Active" 1 "Standby" 0 "Off" ;
VAL_TABLE_ TjaMsgTxt_D_Dsply 7 "Disclaimer" 6 "SmartOffering" 5 "HaSelected" 4 "HaUnavailable" 3 "TurnOnAdaptCruiseControl" 2 "TrafficJamAssistSelected" 1 "TrafficJamAssistUnavailabl" 0 "NoMessage" ;
VAL_TABLE_ PwSrcULowMde_D_Actl 3 "BuckSpecial" 2 "ReverseBoost" 1 "ForwardBuck" 0 "Standby" ;
VAL_TABLE_ EmgcyCallMute_D_Stat 7 "NotUsed4" 6 "NotUsed3" 5 "NotUsed2" 4 "NotUsed1" 3 "ManualEmergencyCallMute" 2 "AutomaticEmergencyCallMute" 1 "EmergencyCallUnmute" 0 "Null" ;
VAL_TABLE_ ApaTrgtDist_D_Stat 15 "Step15" 14 "Step14" 13 "Step13" 12 "Step12" 11 "Step11" 10 "Step10" 9 "Step9" 8 "Step8" 7 "Step7" 6 "Step6" 5 "Step5" 4 "Step4" 3 "Step3" 2 "Step2" 1 "Step1" 0 "Off" ;
VAL_TABLE_ Memory_2_SwPsngr_Stat 1 "Pressed" 0 "Null" ;
VAL_TABLE_ Pers3Key_D_Stat 3 "NotUsed_1" 2 "KeyUnAssociated" 1 "KeyAssociated" 0 "Null" ;
VAL_TABLE_ PwSrcULoMde_D_Rq 3 "BuckSpecial" 2 "ReverseBoost" 1 "ForwardBuck" 0 "Standby" ;
VAL_TABLE_ AccMsgTxt_D2_Rq 15 "Brakes_Warm" 14 "NCC_Enabled_Warning" 13 "IACC_TJA_Selected" 12 "ACC_TJA_Selected" 11 "IACC_Selected" 10 "Press_Brake_To_Hold" 9 "Only_Following_In_Low_Spd" 8 "TJA_Unavailable" 7 "Shift_Down" 6 "IACC_Unavailable" 5 "ACC_Selected" 4 "ACC_Overridden" 3 "Brake_Capacity_Warning" 2 "ACC_Cancelled" 1 "ACC_Unavailable" 0 "No_Text" ;
VAL_TABLE_ WakeAlarm0_B_Typ 1 "CanAndEcuDriveCircuit" 0 "CanOnly" ;
VAL_TABLE_ WakeAlarm0_D_Stat 3 "PublisherReset" 2 "Wake" 1 "AlarmRunning" 0 "AlarmOff" ;
VAL_TABLE_ EmPrflNo_D_Rq 7 "NotUsed_3" 6 "NotUsed_2" 5 "NotUsed_1" 4 "Pers4" 3 "Pers3" 2 "Pers2" 1 "Pers1" 0 "Null" ;
VAL_TABLE_ EmPrflKeyAssoc_D_Rq 7 "NotUsed_3" 6 "DisassociatePhone" 5 "EnterPhoneAssociation" 4 "OverwriteKey" 3 "DisassociateKey" 2 "ExitKeyAssociation" 1 "EnterKeyAssociation" 0 "Null" ;
VAL_TABLE_ Em_D_Stat 3 "NotSupported" 2 "ProfilesOff" 1 "ProfilesOn" 0 "Null" ;
VAL_TABLE_ EmPrflButtnAssoc_D_Rq 3 "NotUsed" 2 "ExitButtonAssociation" 1 "EnterButtonAssociation" 0 "Null" ;
VAL_TABLE_ EmPrflNo_D_Stat 7 "NotUsed_3" 6 "NotUsed_2" 5 "NotUsed_1" 4 "Pers4" 3 "Pers3" 2 "Pers2" 1 "Pers1" 0 "Null" ;
VAL_TABLE_ EmPrflKeyAssoc_D_Stat 7 "WrongDevice" 6 "KeyAssociateFailed" 5 "KeyAssociateSuccess" 4 "KeyAlreadyInUse" 3 "KeyDisassociated" 2 "KeyAssociationExited" 1 "KeyAssociationEntered" 0 "Null" ;
VAL_TABLE_ EsaEnbl_D2_Rq 3 "NotConfigured" 2 "Enabled" 1 "Pending" 0 "Disabled" ;
VAL_TABLE_ PersNo_D_Actl 7 "Unused_3" 6 "Unused_2" 5 "NotDetermined" 4 "Vehicle" 3 "PERS_4" 2 "PERS_3" 1 "PERS_2" 0 "PERS_1" ;
VAL_TABLE_ WiprFront_D_Stat2 15 "NO_DATA_EXISTS" 14 "STALLED" 13 "NotUsed" 12 "AUTO_ADJUST" 11 "COURTESYWIPE" 10 "AUTO_HIGH" 9 "AUTO_LOW" 8 "WASH" 7 "MIST_FLICK" 6 "MAN_HIGH" 5 "MAN_LOW" 4 "MAN_INT_ON" 3 "MAN_INT_OFF" 2 "OFF_MOVING" 1 "AUTO_OFF" 0 "OFF" ;
VAL_TABLE_ TurnLghtSwtch_D_Stat2 3 "NotUsed" 2 "Right" 1 "Left" 0 "Off" ;
VAL_TABLE_ CcButtnOnOffCnclPress3 1 "Pressed" 0 "Not pressed" ;
VAL_TABLE_ SelDrvMdePos01_B_Avail 1 "Available" 0 "NotAvailable" ;
VAL_TABLE_ SelDrvMdePos01_D_Stat 31 "Faulty" 30 "SelDrvMde31" 29 "SelDrvMde30" 28 "SelDrvMde29" 27 "SelDrvMde28" 26 "SelDrvMde27" 25 "SelDrvMde26" 24 "SelDrvMde25" 23 "SelDrvMde24" 22 "SelDrvMde23" 21 "SelDrvMde22" 20 "SelDrvMde21" 19 "SelDrvMde20" 18 "SelDrvMde19" 17 "SelDrvMde18" 16 "SelDrvMde17" 15 "SelDrvMde16" 14 "SelDrvMde15" 13 "SelDrvMde14" 12 "SelDrvMde13" 11 "SelDrvMde12" 10 "SelDrvMde11" 9 "SelDrvMde10" 8 "SelDrvMde09" 7 "SelDrvMde08" 6 "SelDrvMde07" 5 "SelDrvMde06" 4 "SelDrvMde05" 3 "SelDrvMde04" 2 "SelDrvMde03" 1 "SelDrvMde02" 0 "SelDrvMde01" ;
VAL_TABLE_ Closed_Open_Active_Denied 3 "Denied" 2 "Active" 1 "Open" 0 "Closed" ;
VAL_TABLE_ IaccLamp_D_Rq 3 "NotUsed_2" 2 "NotUsed_1" 1 "DisplayIaccIcon" 0 "DoNotDisplayIaccIcon" ;
VAL_TABLE_ Low_High_Confidence 1 "High_Confidence" 0 "Low_Confidence" ;
VAL_TABLE_ Fault_Occupied_Empty_Un 3 "Unknown" 2 "Empty" 1 "Occupied" 0 "Fault" ;
VAL_TABLE_ Off_On_Flash_Triggered 3 "Triggered" 2 "Flash" 1 "On" 0 "Off" ;
VAL_TABLE_ KeyOffMde_D_Actl 15 "NotUsed_11" 14 "NotUsed_10" 13 "NotUsed_9" 12 "NotUsed_8" 11 "NotUsed_7" 10 "NotUsed_6" 9 "NotUsed_5" 8 "NotUsed_4" 7 "NotUsed_3" 6 "NotUsed_2" 5 "NotUsed_1" 4 "CriticalBattery" 3 "Hibernate" 2 "Transport" 1 "Factory" 0 "Normal" ;
VAL_TABLE_ IaccVLim_D_Rq 252 "NotUsed_2" 250 "LimitSpeed_250" 240 "LimitSpeed_240" 230 "LimitSpeed_230" 220 "LimitSpeed_220" 210 "LimitSpeed_210" 200 "LimitSpeed_200" 190 "LimitSpeed_190" 150 "LimitSpeed_150" 140 "LimitSpeed_140" 130 "LimitSpeed_130" 120 "LimitSpeed_120" 110 "LimitSpeed_110" 100 "LimitSpeed_100" 90 "LimitSpeed_90" 80 "LimitSpeed_80" 70 "LimitSpeed_70" 60 "LimitSpeed_60" 50 "LimitSpeed_50" 40 "LimitSpeed_40" 30 "LimitSpeed_30" 20 "LimtSpeed_20" 251 "NotUsed_1" 255 "Faulty" 254 "NoDataExists" 253 "NotUsed_3" 180 "LimitSpeed_180" 179 "LimitSpeed_179" 178 "LimitSpeed_178" 177 "LimitSpeed_177" 176 "LimitSpeed_176" 175 "LimitSpeed_175" 174 "LimitSpeed_174" 173 "LimitSpeed_173" 172 "LimitSpeed_172" 171 "LimitSpeed_171" 170 "LimitSpeed_170" 169 "LimitSpeed_169" 168 "LimitSpeed_168" 167 "LimitSpeed_167" 166 "LimitSpeed_166" 165 "LimitSpeed_165" 164 "LimitSpeed_164" 163 "LimitSpeed_163" 162 "LimitSpeed_162" 161 "LimitSpeed_161" 160 "LimitSpeed_160" 15 "LimitSpeed_15" 14 "LimitSpeed_14" 13 "LimitSpeed_13" 12 "LimitSpeed_12" 11 "LimitSpeed_11" 10 "LimitSpeed_10" 9 "LimitSpeed_9" 8 "LimitSpeed_8" 7 "LimitSpeed_7" 6 "LimitSpeed_6" 5 "LimitSpeed_5" 4 "LimitSpeed_4" 3 "LimitSpeed_3" 2 "LimitSpeed_2" 1 "LimitSpeed_1" 0 "LimitSpeed_0" ;
VAL_TABLE_ IaccVLimUnit_D_Rq 3 "NoDataExists" 2 "Mph" 1 "Kph" 0 "Null" ;
VAL_TABLE_ SelDrvMdeAwd_D_Rq 31 "Faulty" 30 "NotUsed_17" 29 "NotUsed_16" 28 "NotUsed_15" 27 "NotUsed_14" 26 "NotUsed_13" 25 "NotUsed_12" 24 "NotUsed_11" 23 "NotUsed_10" 22 "NotUsed_9" 21 "NotUsed_8" 20 "NotUsed_7" 19 "NotUsed_6" 18 "NotUsed_5" 17 "EvLaterChargeMode" 16 "EvNowMode" 15 "TrackMode" 14 "RoughRoadMode" 13 "NotAvailable" 12 "HighSpeedDesertMode_Baja" 11 "SportAdaptiveMode" 10 "RockCrawlMode" 9 "MudRutsMode" 8 "SandMode" 7 "EconomyMode" 6 "GrassGravelSnow" 5 "TowHaulMode" 4 "SportMode" 3 "Normal_4L" 2 "Normal_4A" 1 "Normal_2H" 0 "NormalMode" ;
VAL_TABLE_ SelDrvMdeAwd_D_Stat 0 "NotAvailable" 1 "Available" 2 "TemporarilyNotAvailable" 3 "Faulty" ;
VAL_TABLE_ SelDrvMdeAwd2_D_Stat 31 "Faulty" 30 "NotUsed_17" 29 "NotUsed_16" 28 "NotUsed_15" 27 "NotUsed_14" 26 "NotUsed_13" 25 "NotUsed_12" 24 "NotUsed_11" 23 "NotUsed_10" 22 "NotUsed_9" 21 "NotUsed_8" 20 "NotUsed_7" 19 "NotUsed_6" 18 "NotUsed_5" 17 "EvLaterChargeMode" 16 "EvNowMode" 15 "TrackMode" 14 "RoughRoadMode" 13 "NotAvailable" 12 "HighSpeedDesertMode_Baja" 11 "SportAdaptiveMode" 10 "RockCrawlMode" 9 "MudRutsMode" 8 "SandMode" 7 "EconomyMode" 6 "GrassGravelSnow" 5 "TowHaulMode" 4 "SportMode" 3 "Normal_4L" 2 "Normal_4A" 1 "Normal_2H" 0 "NormalMode" ;
VAL_TABLE_ RearDiffLckMsg2_D_Rq 15 "NotUsed_3" 14 "NotUsed_2" 13 "NotUsed_1" 12 "ElsdReduced" 11 "LockingFeatureNotAvailable" 10 "EsldOff" 9 "ElsdRestored" 8 "ElsdOverheated" 7 "Locker_Disabled" 6 "Locker_Enabled" 5 "LockerSpeed5" 4 "LockerSpeed4" 3 "LockerSpeed3" 2 "LockerSpeed2" 1 "LockerSpeed1" 0 "NormalNoMessage " ;
VAL_TABLE_ Counts_ZeroToSeven 4 "FourCounts" 3 "ThreeCounts" 2 "TwoCounts" 1 "OneCount" 0 "ZeroCounts" 7 "SevenOrMoreCounts" 6 "SixCounts" 5 "FiveCounts" ;
VAL_TABLE_ HeadLghtHiPrmsn_D_Stat 3 "CancelAndSuppress" 2 "Cancel" 1 "Hold" 0 "AllowChange" ;
VAL_TABLE_ SelDrvMdeSwtch 3 "Faulty" 2 "SwitchState2" 1 "SwitchState1" 0 "NotPressed" ;
VAL_TABLE_ NotAvail_Temp_Faulty 3 "Faulty" 2 "TemporarilyNotAvailable" 1 "Available" 0 "NotAvailable" ;
VAL_TABLE_ ChrgCompltMsgTxt_D_Rq 3 "NotUsed_1" 2 "ChargeToFull" 1 "ChargeToFastChargeLimit" 0 "DefaultLabel" ;
VAL_TABLE_ AwdDrvMde 7 "Faulty" 6 "NotAvailable" 5 "RockCrawl" 4 "Baja" 3 "MudAndSand" 2 "Weather" 1 "Sport" 0 "Normal" ;
VAL_TABLE_ SelDrvMdePt_D_Rq 31 "Faulty" 30 "NotUsed15" 29 "NotUsed14" 28 "NotUsed13" 27 "NotUsed12" 26 "NotUsed11" 25 "NotUsed10" 24 "NotUsed9" 23 "NotUsed8" 22 "NotUsed7" 21 "NotUsed6" 20 "NotUsed5" 19 "OnePedalDrive" 18 "EvLaterChargerMode" 17 "EvNowMode" 16 "DragMode" 15 "HighSpeedDesertMode_Baja" 14 "SportAdaptiveMode" 13 "NotAvailable_13" 12 "NotAvailable_12" 11 "NotAvailable_11" 10 "NotAvailable_10" 9 "RockCrawlMode" 8 "MudRutsMode" 7 "SandMode" 6 "EconomyMode" 5 "GrassGravelSnow" 4 "NotAvailable_04" 3 "TowHaulMode" 2 "NotAvailable_02" 1 "SportMode" 0 "NormalMode" ;
VAL_TABLE_ SelDrvMde_D_Stat 3 "NotUsed" 2 "DriveModeChangeRequest" 1 "DriveModeChangeSelection" 0 "NoDriveModeChangeRequest" ;
VAL_TABLE_ NoMessage_Msg1_15 15 "Message15" 14 "Message14" 13 "Message13" 12 "Message12" 11 "Message11" 10 "Message10" 9 "Message9" 8 "Message8" 7 "Message7" 6 "Message6" 5 "Message5" 4 "Message4" 3 "Message3" 2 "Message2" 1 "Message1" 0 "NoMessage" ;
VAL_TABLE_ SelDrvMdeChassis_D_Rq 31 "Faulty" 30 "NotUsed17" 29 "NotUsed16" 28 "NotUsed15" 27 "NotUsed14" 26 "NotUsed13" 25 "NotUsed12" 24 "NotUsed11" 23 "NotUsed10" 22 "NotUsed9" 21 "NotUsed8" 20 "NotUsed7" 19 "NotUsed6" 18 "NotUsed5" 17 "NotUsed4" 16 "NotUsed3" 15 "NotUsed2" 14 "NotUsed1" 13 "TrackMode" 12 "HighSpeedDesertMode" 11 "TowHaulMode" 10 "RockCrawlMode" 9 "SandMode" 8 "MudAndRutsMode" 7 "LowMuMode" 6 "ComfortAdaptiveMode" 5 "ComfortMode" 4 "SportAdaptiveMode" 3 "SportMode" 2 "EconomyMode" 1 "NormalAdaptiveMode" 0 "NormalMode" ;
VAL_TABLE_ NotAvailable_Available 1 "Available" 0 "NotAvailable" ;
VAL_TABLE_ PwStep_D_Stat 3 "PositionNotKnown" 2 "StepsNotStowed" 1 "StepsStowed" 0 "Off" ;
VAL_TABLE_ PwStep_D_DrvInhbt 3 "NotUsed" 2 "DriveInhibitMalfunction" 1 "DriveInhibited" 0 "DriveNotInhibited" ;
VAL_TABLE_ VehTrvlDir_D_Stat 7 "Faulty" 6 "NoDataExists" 5 "NotUsed2" 4 "NotUsed1" 3 "Reverse" 2 "LikelyReverse" 1 "Forward" 0 "LikelyForward" ;
VAL_TABLE_ TrnRng_D_RqFap 7 "NotUsed3" 6 "NotUsed2" 5 "NotUsed1" 4 "Backwards" 3 "Forwards" 2 "NoMotion" 1 "Immobilize" 0 "NoRequest" ;
VAL_TABLE_ SelDrvMdeSusp_D_Stat 3 "Faulty" 2 "TemporarilyNotAvailable" 1 "Available" 0 "NotAvailable" ;
VAL_TABLE_ OffOnNoReqFaulty 3 "Faulty" 2 "NoRequest" 1 "On" 0 "Off" ;
VAL_TABLE_ LatCtl_D_Rq 7 "NotUsed4" 6 "NotUsed3" 5 "NotUsed2" 4 "NotUsed1" 3 "InterventionRight" 2 "InterventionLeft" 1 "ContinuousPathFollowing" 0 "NoLateralControl" ;
VAL_TABLE_ LatCtlSte_D_Stat 7 "NotUsed3" 6 "NotUsed2" 5 "NotUsed1" 4 "Denied" 3 "RampOut" 2 "ContLatControlInProgress" 1 "Available" 0 "Unavailable" ;
VAL_TABLE_ SlowMedFastImmed 3 "Immediately" 2 "Fast" 1 "Medium" 0 "Slow" ;
VAL_TABLE_ ComfortablePreciseNotUsed 3 "NotUsed2" 2 "NotUsed1" 1 "Precise" 0 "Comfortable" ;
VAL_TABLE_ LatCtlLim_D_Stat 3 "LimitWithDriverActive" 2 "LimitReached" 1 "LimitClose" 0 "LimitNotReached" ;
VAL_TABLE_ FuelLvlWarn_D_ActlEng 7 "DteLevel5Lowest" 6 "DteLevel4" 5 "DteLevel3" 4 "DteLevel2NonMyKey" 3 "DteLevel1MyKey" 2 "VeryLow" 1 "Low" 0 "OK" ;
VAL_TABLE_ AwdMde_D_RqDrv 7 "Faulty" 6 "NotUsed2" 5 "NoRequest" 4 "Neutral" 3 "FourByFourLow" 2 "FourByFourHigh" 1 "FourByFourAuto" 0 "FourByTwo" ;
VAL_TABLE_ ApaBrk_D_Stat 3 "Denied" 2 "Active" 1 "Open" 0 "Closed" ;
VAL_TABLE_ AdptDrvMdePt_D_Rq 7 "Faulty" 6 "NotUsed3" 5 "NotUsed2" 4 "NotUsed1" 3 "Powertrain2Sport" 2 "Powertrain2Normal" 1 "Powertrain2Comfort" 0 "AdaptiveNotActive" ;
VAL_TABLE_ AdptDrvMdeChassis_D_Rq 7 "Faulty" 6 "NotUsed3" 5 "NotUsed2" 4 "NotUsed1" 3 "Chassis2Sport" 2 "Chassis2Normal" 1 "Chassis2Comfort" 0 "AdaptiveNotActive" ;
VAL_TABLE_ PwStepMsgTxt_D_Rq 1 "DriveInhibited" 0 "NoMessage" 3 "NotUsed" 2 "Malfunction" ;
VAL_TABLE_ OffLowMedHigh 3 "High" 2 "Medium" 1 "Low" 0 "Off" ;
VAL_TABLE_ NotDeterminedLowMedHigh 3 "High" 2 "Medium" 1 "Low" 0 "NotDetermined" ;
VAL_TABLE_ CmbbObjClass_D_Stat 15 "NotUsed_9" 14 "NotUsed_8" 13 "NotUsed_7" 12 "NotUsed_6" 11 "NotUsed_5" 10 "NotUsed_4" 9 "NotUsed_3" 8 "NotUsed_2" 7 "NotUsed_1" 6 "Unclassified_Vehicle" 5 "Bicycle" 4 "Pedestrian" 3 "Truck" 2 "Motorcycle" 1 "Vehicle" 0 "Undetermined" ;
VAL_TABLE_ HeadLghtHiCtrl_D_RqAhb 7 "NotUsed2" 6 "NotUsed1" 5 "Auto_HiBeam" 4 "Auto_LoBeam" 3 "Flash" 2 "Man_HiBeam" 1 "Man_LoBeam" 0 "Null" ;
VAL_TABLE_ AhbHiBeam_D_Rq 3 "NotUsed" 2 "HighBeamRecommended" 1 "LowBeamRecommended" 0 "DeactivatedUnavailable" ;
VAL_TABLE_ AhbStatGfhbFdbk_D_Actl 3 "GfhbHighBeamFullyOn" 2 "GfhbHighBeamPartlyOn" 1 "GfhbHighBeamOff" 0 "GfhbUnavailable" ;
VAL_TABLE_ AhbcRampingV_D_Rq 3 "Slow" 2 "Medium" 1 "Fast" 0 "Immediately" ;
VAL_TABLE_ ApaGearShif_D_RqDrv 7 "NotUSed2" 6 "NotUsed1" 5 "ShiftToP" 4 "ShiftToN" 3 "ShiftToD" 2 "ShiftToR" 1 "NoRequest" 0 "Null" ;
VAL_TABLE_ ApaLongCtl_D_RqDrv 7 "NotUsed3" 6 "NotUsed2" 5 "ReleaseBrake" 4 "DriveBackward" 3 "DriveForward" 2 "Stop" 1 "NoRequest" 0 "Null" ;
VAL_TABLE_ ApaActvSide2_D_Stat 3 "NoSide" 2 "Right" 1 "Left" 0 "Null" ;
VAL_TABLE_ ApaScan_D_Stat 3 "ParkSlotReady" 2 "ParkSlotFound" 1 "NoParkSlot" 0 "Null" ;
VAL_TABLE_ ApaSelSapp_D_Stat 3 "NotConfigured" 2 "NotSelectable" 1 "Selectable" 0 "Null" ;
VAL_TABLE_ ApaSys_D_Stat 7 "Faulty" 6 "Finished" 5 "NotAccessible" 4 "ApaCancelled" 3 "Overspeed" 2 "On" 1 "Off" 0 "Null" ;
VAL_TABLE_ ApaSteScanMde_D_Stat 3 "Steering" 2 "Scanning" 1 "NotScanning" 0 "Null" ;
VAL_TABLE_ ApaAcsy_D_RqDrv 7 "CloseDoor" 6 "SelectSideRight" 5 "SelectSideLeft" 4 "CheckForObject" 3 "PressApaButton" 2 "SelectSide" 1 "NoRequest" 0 "Null" ;
VAL_TABLE_ ApaSteWhl_D_RqDrv 3 "TakeControl" 2 "RemoveHands" 1 "NoRequest" 0 "Null" ;
VAL_TABLE_ WiprFrontSwtch_D_Stat 15 "NotUsed6" 14 "NotUsed5" 13 "NotUsed4" 12 "NotUsed3" 11 "NotUsed2" 10 "NotUsed1" 9 "PositionNotDetermined" 8 "High" 7 "Low" 6 "Position6" 5 "Position5" 4 "Position4" 3 "Position3" 2 "Position2" 1 "Position1" 0 "Off" ;
VAL_TABLE_ Off_On_Unknown_Invalid 3 "Invalid" 2 "Unknown" 1 "On" 0 "Off" ;
VAL_TABLE_ Unknown_7FFE_Invalid_7FFF 32767 "Invalid" 32766 "Unknown" ;
VAL_TABLE_ OffOnNotUsedFaulty 3 "Faulty" 2 "NotUsed" 1 "On" 0 "Off" ;
VAL_TABLE_ BrkBstrVac_D_Stat 3 "NotUsed" 2 "BoosterVacEstimator" 1 "BoosterVacSensor" 0 "NoBoosterVacuumMonitor" ;
VAL_TABLE_ AwdMde_D_RqArb 7 "Faulty" 6 "NotUsed2" 5 "NoRequest" 4 "Neutral" 3 "FourByFourLow" 2 "FourByFourHigh" 1 "FourByFourAuto" 0 "FourByTwo" ;
VAL_TABLE_ CtaAlrt2_D_Stat 7 "NotUsed3" 6 "NotUsed2" 5 "NotUsed1" 4 "AlertZone4" 3 "AlertZone3" 2 "AlertZone2" 1 "AlertZone1" 0 "Off" ;
VAL_TABLE_ BttRightLeft_D_Stat 7 "NotUsed" 6 "Disabled" 5 "Off" 4 "OffTemp" 3 "NotConnected" 2 "Pending" 1 "Connected" 0 "NotDetermined" ;
VAL_TABLE_ Null_NoRequest_Request 3 "NotUsed" 2 "Request" 1 "NoRequest" 0 "Null" ;
VAL_TABLE_ PoliceIdlMde_D_Stat 15 "NotUsed_7" 14 "NotUsed_6" 13 "NotUsed_5" 12 "NotUsed_4" 11 "NotUsed_3" 10 "NotUsed_2" 9 "PepsActive" 8 "Decommissioned" 7 "ActiveFault" 6 "ArmFault" 5 "PrearmedFault" 4 "OffFault" 3 "Active" 2 "Arm" 1 "Prearmed" 0 "Off" ;
VAL_TABLE_ TripComputerMetricImperial 0 "TripComputer_metric" 1 "TripComputer_imperial" ;
VAL_TABLE_ GrdAsstAllw_D_DsplyPt 3 "NotUsed" 2 "On" 1 "Off" 0 "NoModeSelected" ;
VAL_TABLE_ PrkBrkMsgTxt_D_Rq 15 "Message15" 14 "Message14" 13 "Message13" 12 "Message12" 11 "Message11" 10 "Message10" 9 "Message9" 8 "Message8" 7 "Message7" 6 "Message6" 5 "Message5" 4 "Message4" 3 "Message3" 2 "Message2" 1 "Message1" 0 "No_Message" ;
VAL_TABLE_ AutoHoldMsgTxt_D_Rq 15 "Message15" 14 "Message14" 13 "Message13" 12 "Message12" 11 "Message11" 10 "Message10" 9 "Message9" 8 "Message8" 7 "Message7" 6 "Message6" 5 "Message5" 4 "Message4" 3 "Message3" 2 "Message2" 1 "Message1" 0 "NoMessage" ;
VAL_TABLE_ AutoHoldMde_D_Ind 3 "Indication_3" 2 "Indication_2" 1 "Indication_1" 0 "Off" ;
VAL_TABLE_ AutoRgenTxt_B_RqDsply 1 "AutExhFilterCleanOFF" 0 "AutExhFilterCleanON" ;
VAL_TABLE_ TrnMsgTxt2_D_Rq 7 "NotUsed3" 6 "NotUsed2" 5 "NotUsed1" 4 "TransTooHot_LoudChime" 3 "PressBrake_LoudChime" 2 "PressBrake_SoftChime" 1 "PressBrake_NoChime" 0 "NoText_NoChime" ;
VAL_TABLE_ TrnGearMsgTxt_D_Rq 15 "Message_15" 14 "Message_14" 13 "Message_13" 12 "Message_12" 11 "Message_11" 10 "Message_10" 9 "Message_9" 8 "Message_8" 7 "Message_7" 6 "Message_6" 5 "Message_5" 4 "Message_4" 3 "Message_3" 2 "Message_2" 1 "Message_1" 0 "NoMessage" ;
VAL_TABLE_ ChargeProfIDPref_Rq 3 "NotUsed" 2 "Value" 1 "ChargeNow" 0 "Inactive" ;
VAL_TABLE_ EngExhMdeQuiet_D_Stat 3 "Faulty" 2 "QuietExhaust" 1 "LoudExhaust" 0 "Null" ;
VAL_TABLE_ ElTrip_L_Dsply 65535 "Fault" 65534 "No_Data_Exists" ;
VAL_TABLE_ ElLongTerm_L_Dsply 16777215 "Fault" 16777214 "No_Data_Exists" ;
VAL_TABLE_ GearSelLck_D_Rq 3 "PreventionBlocker" 2 "Unlock" 1 "Lock" 0 "Null" ;
VAL_TABLE_ BrkPadMsgTxt_D_Rq 3 "Faulty" 2 "PadsOk" 1 "ReplacePads" 0 "Null" ;
VAL_TABLE_ SuspDrvMde_D_Rq 7 "Faulty" 6 "NotUsed2" 5 "NotUsed1" 4 "Drag" 3 "Track" 2 "Snow_Wet" 1 "Sport" 0 "Normal" ;
VAL_TABLE_ NotPressed_PressedNotUsed 3 "NotUsed2" 2 "NotUsed1" 1 "Pressed" 0 "Not_Pressed" ;
VAL_TABLE_ WhlRearDual_D_Stat 3 "NotUsed" 2 "Dual" 1 "Single" 0 "NoDataExists" ;
VAL_TABLE_ TracKeyMde_D_Stat 3 "NotUsed" 2 "NotActive" 1 "Active" 0 "ModeNotDetermined" ;
VAL_TABLE_ HudMde_D_Stat 7 "NotUsed3" 6 "NotUsed2" 5 "NotUsed1" 4 "Manual" 3 "Drag" 2 "RoadCourse" 1 "Tach" 0 "Off" ;
VAL_TABLE_ TrnManShifGear_D_IndDrv 7 "Indicate_Reverse_Gear" 6 "Indicate_Gear6" 5 "Indicate_Gear5" 4 "Indicate_Gear4" 3 "Indicate_Gear3" 2 "Indicate_Gear2" 1 "Indicate_Gear1" 0 "No_Indication" ;
VAL_TABLE_ LsmcBrkDecel_D_Stat 7 "NotUsed_3" 6 "NotUsed_2" 5 "NotUsed_1" 4 "Denied" 3 "FaultDegraded" 2 "FaultExt" 1 "On" 0 "Off" ;
VAL_TABLE_ StePinOffst_D_Stat 3 "FineOffset" 2 "CoarseOffset" 1 "StoredOffset" 0 "OffsetNotCalculated" ;
VAL_TABLE_ NoMessage_Override_Faulty 3 "NotUsed" 2 "Faulty" 1 "Override" 0 "NoMessage" ;
VAL_TABLE_ TrnIpcDsplyRng2_D_Actl 15 "No_Range_Selected" 14 "Range_14" 13 "Range_13" 12 "Range_12" 11 "Range_11" 10 "Range_10" 9 "Range_9" 8 "Range_8" 7 "Range_7" 6 "Range_6" 5 "Range_5" 4 "Range_4" 3 "Range_3" 2 "Range_2" 1 "Range_1" 0 "NotUsed" ;
VAL_TABLE_ OffOn_RampUpDown 3 "Ramp_Down" 2 "Ramp_Up" 1 "On" 0 "Off" ;
VAL_TABLE_ DieslMsgTxt_D_Rq 3 "NotUsed2" 2 "NotUsed1" 1 "ReducedEnginePower" 0 "NoMessage" ;
VAL_TABLE_ NoMessage_Msg1_7 7 "Message7" 6 "Message6" 5 "Message5" 4 "Message4" 3 "Message3" 2 "Message2" 1 "Message1" 0 "NoMessage" ;
VAL_TABLE_ LnchCtl 3 "NotUsed2" 2 "NotUsed1" 1 "LC_On" 0 "LC_Off" ;
VAL_TABLE_ BrkLineLck_D_Rq 3 "Off" 2 "Engage" 1 "Initiate" 0 "NoRequest" ;
VAL_TABLE_ BrkLineLck_D_Stat 7 "NotUsed_3" 6 "NotUsed_2" 5 "NotUsed_1" 4 "NotAvailable" 3 "Off" 2 "Engaged" 1 "Initiated" 0 "Available" ;
VAL_TABLE_ LnchCtlSys_D_Stat 7 "NotUsed3" 6 "NotUsed2" 5 "NotUsed1" 4 "On_LC_Unavailable_TC_On" 3 "On_LC_Unavailable" 2 "On_LC_Available" 1 "On_LC_Active" 0 "LC_OFF" ;
VAL_TABLE_ ActvFrontSteLck_D_Stat 3 "Test_passed" 2 "Test_failed" 1 "Test_cannot_run" 0 "Test_incomplete" ;
VAL_TABLE_ Rght_Lefthand_Traffic 1 "Left_Hand_Traffic" 0 "Right_Hand_Traffic" ;
VAL_TABLE_ NotPressed_Pressed_Faulty 3 "Faulty" 2 "NotUsed" 1 "Pressed" 0 "Not_Pressed" ;
VAL_TABLE_ TrlrTrgtAcquire_D_Rq 7 "NotUsed_2" 6 "NotUsed_1" 5 "ActivateRVCforTBA" 4 "CancelAcquisition" 3 "RetryAcquisition" 2 "AcquisitionSuccessful" 1 "StartAcquisition" 0 "Inactive" ;
VAL_TABLE_ TrlrTrgtAcquire_D_Stat 7 "Faulty" 6 "NotUsed_2" 5 "NotUsed_1" 4 "RVCforTBA_Activated" 3 "Processing" 2 "TargetNotAcquired" 1 "TargetAcquired" 0 "Null" ;
VAL_TABLE_ TrlBrkInitOut 3 "Heavy" 2 "Medium" 1 "Light" 0 "Null" ;
VAL_TABLE_ IsaOffst_D_Stat 15 "Faulty" 14 "Null" 13 "Thirteen" 12 "Twelve" 11 "Eleven" 10 "Ten" 9 "Nine" 8 "Eight" 7 "Seven" 6 "Six" 5 "Five" 4 "Four" 3 "Three" 2 "Two" 1 "One" 0 "Zero" ;
VAL_TABLE_ IsaVLimUnit_D_Rq 3 "NoDataExists" 2 "Mph" 1 "Kph" 0 "Null" ;
VAL_TABLE_ ApaChime_D_Rq 7 "NotUsed2" 6 "NotUsed1" 5 "Warning_Chime" 4 "Finish_Chime" 3 "Stop_Now_Chime" 2 "Spot_Ready_Chime" 1 "Spot_Found_Chime" 0 "No_Chime" ;
VAL_TABLE_ SlMde_D_RqDsply 3 "NotUsed" 2 "ManualSpeed_LimiterSymbol" 1 "AutoSpeed_LimiterSymbol" 0 "NoSpeed_LimiterSymbol" ;
VAL_TABLE_ SlMde_D_Rq 3 "IsaNotConfigured" 2 "Manual_Mode" 1 "Auto_Mode" 0 "Null" ;
VAL_TABLE_ OffOn_NotUsed_NoData 3 "No_Data_Present" 2 "NotUsed" 1 "On" 0 "Off" ;
VAL_TABLE_ Faulty_FF 255 "Faulty" ;
VAL_TABLE_ BrkDrvMde_D_Rq 7 "Faulty" 6 "RockCrawl" 5 "Baja" 4 "DragOrMudAndSand" 3 "Track" 2 "Snow_Wet" 1 "Sport" 0 "Normal" ;
VAL_TABLE_ TrnIpcDsplyRng_D_Stat 3 "NotUsed" 2 "Flash" 1 "On" 0 "Blank_No_Display" ;
VAL_TABLE_ NoYesNoDataFaulty 3 "Faulty" 2 "NoDataExists" 1 "Yes" 0 "No" ;
VAL_TABLE_ SidePrkSnsR4_D_Stat 15 "NotUsed" 14 "NotFullyScannedYet" 13 "NoObjectInSector" 12 "Zone12" 11 "Zone11" 10 "Zone10" 9 "Zone9" 8 "Zone8" 7 "Zone7" 6 "Zone6" 5 "Zone5" 4 "Zone4" 3 "Zone3" 2 "Zone2" 1 "Zone1" 0 "Off" ;
VAL_TABLE_ TsrVlPrmntMsgTxt_D_Rq 3 "NotUsed" 2 "ShowPermanentlyWithSupp" 1 "ShowPermanentlyWithoutSupp" 0 "DoNotShowSignPermanent" ;
VAL_TABLE_ TsrVl1RstrcMsgTxt2_D_Rq 7 "NotUsed" 6 "Time" 5 "Trailer" 4 "Snow" 3 "RainWet" 2 "NoRecognizableRestrictn" 1 "NoSpeedLimitRestrictn" 0 "Null" ;
VAL_TABLE_ PtDrvMde_D_Rq 15 "Faulty" 14 "NotUsed11" 13 "NotUsed10" 12 "NotUsed9" 11 "NotUsed8" 10 "NotUsed7" 9 "NotUsed6" 8 "NotUsed5" 7 "Drag" 6 "Rock" 5 "Baja" 4 "Sand" 3 "TowHaulGradeAssist" 2 "SnowWet" 1 "Sport" 0 "Normal" ;
VAL_TABLE_ SteEffort_D_Stat 7 "NotUsed_3" 6 "NotUsed_2" 5 "NotUsed_1" 4 "SpecialMode_2" 3 "SpecialMode_1" 2 "Comfort" 1 "Sport" 0 "Normal" ;
VAL_TABLE_ TsrOvtkMsgTxt2_D_Rq 15 "NotUsed5" 14 "NotUsed4" 13 "NotUsed3" 12 "NotUsed2" 11 "NotUsed1" 10 "LimForTrucksCancelled" 9 "LimForTrucksWoQlfdRstrc" 8 "LimForTrucksWithoutRstrc" 7 "LimAllCancelled" 6 "LimAllWithRstrcTime" 5 "LimAllWithRstrcTrailer" 4 "LimAllWithRstrcSnow" 3 "LimAllWithRstrcRain" 2 "LimAllWithoutQlfdRstrc" 1 "LimAllWithoutRestriction" 0 "OvertakingAllowed" ;
VAL_TABLE_ TrlrAnOffstDir 3 "NotUSed" 2 "Right" 1 "Left_or_Center" 0 "Null" ;
VAL_TABLE_ Null_Off_On 3 "NotUsed" 2 "On" 1 "Off" 0 "Null" ;
VAL_TABLE_ TrlrBrkMde_D_Rq 1 "ElectricOverHydraulic" 0 "Electric" ;
VAL_TABLE_ TrlrAidSetup_D_Stat 7 "Faulty" 6 "NotUsed_3" 5 "NotUsed_2" 4 "NotUsed_1" 3 "EnterParameters" 2 "EndSetup" 1 "BeginSetup" 0 "Null" ;
VAL_TABLE_ TrlrAidMsgTxt_D_Rq 31 "Message31" 30 "Message30" 29 "Message29" 28 "Message28" 27 "Message27" 26 "Message26" 25 "Message25" 24 "Message24" 23 "Message23" 22 "Message22" 21 "Message21" 20 "Message20" 19 "Message19" 18 "Message18" 17 "Message17" 16 "Message16" 15 "Message15" 14 "Message14" 13 "Message13" 12 "Message12" 11 "Message11" 10 "Message10" 9 "Message9" 8 "Message8" 7 "Message7" 6 "Message6" 5 "Message5" 4 "Message4" 3 "Message3" 2 "Message2" 1 "Message1" 0 "NoMessage" ;
VAL_TABLE_ Invalid_7F 127 "Invalid" ;
VAL_TABLE_ Faulty_1FFF 8191 "Faulty" ;
VAL_TABLE_ VehStab_D_Stat 15 "Faulty" 14 "No_Data_Exists" 13 "NotUsed6" 12 "NotUsed5" 11 "NotUsed4" 10 "NotUsed3" 9 "NotUsed2" 8 "NotUsed1" 7 "High_SSRA_no_OS" 6 "Straight" 5 "Post_Oversteer" 4 "Post_Transition" 3 "Countersteer" 2 "Understeer" 1 "Oversteer" 0 "Linear" ;
VAL_TABLE_ NoData_Faulty_1FF_1FE 511 "Faulty" 510 "NoDataExists" ;
VAL_TABLE_ FohEng_D_Rq 3 "AutoEnable_ParkEnable" 2 "AutoDisable_ParkEnable" 1 "AutoEnable_ParkDisable" 0 "Disable_Stop" ;
VAL_TABLE_ Null_Hi_NotUsed_Low 3 "Low" 2 "Not_Used" 1 "High" 0 "Null" ;
VAL_TABLE_ Current_Color 15 "NotUsed7" 14 "NotUsed6" 13 "NotUsed5" 12 "NotUsed4" 11 "NotUsed3" 10 "NotUsed2" 9 "NotUsed1" 8 "Null" 7 "Color7" 6 "Color6" 5 "Color5" 4 "Color4" 3 "Color3" 2 "Color2" 1 "Color1" 0 "Off" ;
VAL_TABLE_ Blended_Color 15 "NotUsed10" 14 "NotUsed9" 13 "NotUsed8" 12 "NotUsed7" 11 "NotUsed6" 10 "NotUsed5" 9 "NotUsed4" 8 "NotUsed3" 7 "NotUsed2" 6 "NotUsed1" 5 "_5" 4 "_4" 3 "_3" 2 "_2" 1 "_1" 0 "Null" ;
VAL_TABLE_ OffOn_Null_NotUsed 3 "NotUsed" 2 "Null" 1 "On" 0 "Off" ;
VAL_TABLE_ DieslPrtc2_D_RqDsply 15 "NotUsed4" 14 "NotUsed3" 13 "NotUsed2" 12 "NotUsed1" 11 "OCR_ExhFilterClean_Stopped" 10 "OCR_ExhFilterCleaned" 9 "RgnOff_AtLimit" 8 "RgnOff_Overloaded" 7 "RgnOff_Loaded" 6 "Exhaust_Filter_Full" 5 "DPF_Overlimit" 4 "DPF_AtLimit" 3 "ExhFilter_Drive_Completed" 2 "Cleaning_Exhaust_Filter" 1 "DPF_Overloaded" 0 "DPF_Normal_Operation" ;
VAL_TABLE_ Null_Pers1_4_Vehicle 7 "Unused_2" 6 "Unused_1" 5 "Vehicle" 4 "PERS_4" 3 "PERS_3" 2 "PERS_2" 1 "PERS_1" 0 "Null" ;
VAL_TABLE_ PrkLckCtlEnbl_D_RqIpc 3 "Rq_Towing" 2 "Rq_Enable" 1 "Rq_Disable" 0 "Null" ;
VAL_TABLE_ PrkLckCtlUnlck_D_Stat 3 "Trans_And_Steer_Unlckd" 2 "Steering_Unlckd" 1 "Transmission_Unlckd" 0 "Null" ;
VAL_TABLE_ VehKeyActv_D_Stat 15 "NotUsed7" 14 "NotUsed6" 13 "NotUsed5" 12 "NotUsed4" 11 "NotUsed3" 10 "NotUsed2" 9 "NotUsed1" 8 "Key8Active" 7 "Key7Active" 6 "Key6Active" 5 "Key5Active" 4 "Key4Active" 3 "Key3Active" 2 "Key2Active" 1 "Key1Active" 0 "NoKeyActive" ;
VAL_TABLE_ VehLckInd_D_Rq 3 "NotUsed" 2 "On_Day" 1 "On_Night" 0 "Off" ;
VAL_TABLE_ PrkBrkDynmc_D_Allw 3 "NotUsed" 2 "EPB_ECD_NotPossible" 1 "EPB_ECD_Possible" 0 "Used_at_Start_Up" ;
VAL_TABLE_ TowBarMsgTxt_D_Rq 7 "NotUsed3" 6 "NotUsed2" 5 "NotUsed1" 4 "TowBar_Ext_No_Trlr" 3 "Error_Dealer_Fix" 2 "Start_Engine_Swivel" 1 "Check_Tow_Bar" 0 "Null" ;
VAL_TABLE_ PrkBrk_D_Stat 7 "Gen_Faults_or_Maint_Mode" 6 "ECD_by_Brake_ECU_Active" 5 "EPB_Limphome_Active" 4 "Rear_Caliper_Open" 3 "RWU_by_EPB_Active" 2 "Rear_Caliper_Transition" 1 "Rear_Caliper_Closed" 0 "Not_Supported" ;
VAL_TABLE_ NoData_Faulty_3E_3F 63 "Faulty" 62 "NoDataExists" ;
VAL_TABLE_ Unknown_Invalid_3E_3F 63 "Invalid" 62 "Unknown" ;
VAL_TABLE_ Faulty_1FF 511 "Faulty" ;
VAL_TABLE_ NoData_Faulty_1FFF_1FFE 8191 "Faulty" 8190 "NoDataExists" ;
VAL_TABLE_ Null_Off_On_Faulty 3 "Faulty" 2 "On" 1 "Off" 0 "Null" ;
VAL_TABLE_ EngOilSrvcMsgTxt_D_Rq 7 "NotUsed3" 6 "NotUsed2" 5 "NotUsed1" 4 "ResetComplete" 3 "ResetInProgress" 2 "ChangeOilNow" 1 "ChangeOilSoon" 0 "NoText" ;
VAL_TABLE_ AirSusp_D_RqDrv 3 "NotUsed" 2 "On" 1 "Off" 0 "NoModeSelected" ;
VAL_TABLE_ AwdSys_D_Stat 3 "Faulty" 2 "NotUsed" 1 "_4x4_L_H_Active" 0 "_4x4_L_H_Inactive" ;
VAL_TABLE_ EmotiveType_D_Dsply 3 "EmotiveDisplay_3" 2 "EmotiveDisplay_2" 1 "EmotiveDisplay_1" 0 "Null" ;
VAL_TABLE_ AutoRgen_D_Rq 3 "NotUsed" 2 "AutExhFilterCleanOFF" 1 "AutExhFilterCleanON" 0 "No_Mode_Selected" ;
VAL_TABLE_ TrnSrvcRqd_B_Rq 1 "On" 0 "Off" ;
VAL_TABLE_ PlgOvrrdStrt_D_Cmd 3 "NotUsed" 2 "Override_Plug_Status" 1 "Dont_Override_Plug_Status" 0 "Null_State" ;
VAL_TABLE_ immoSecureIdleMode 3 "NotUsed2" 2 "NotUsed1" 1 "Active" 0 "Inactive" ;
VAL_TABLE_ SteWhlOffstRq_D_Stat 3 "Faulty" 2 "NoDataExists" 1 "Allow_External_Angle_Req" 0 "Deny_External_Angle_Req" ;
VAL_TABLE_ SteMdule_D_Stat 7 "NotUsed" 6 "EPAS_Failure3" 5 "EPAS_Failure2" 4 "System_Failure" 3 "EPAS_Shutdown" 2 "Normal_Op_Full_Assist" 1 "Normal_Op_Limited_Assist" 0 "EPAS_Initialization" ;
VAL_TABLE_ Faulty_FFF 4095 "Faulty" ;
VAL_TABLE_ Faulty_3FF 1023 "Faulty" ;
VAL_TABLE_ Invalid_F 15 "Invalid" ;
VAL_TABLE_ Invalid_1F 31 "Invalid" ;
VAL_TABLE_ NoData_Faulty_FFFFFE_FFFFFF 16777215 "Faulty" 16777214 "NoDataExists" ;
VAL_TABLE_ NoData_Faulty_FE_FF 255 "Faulty" 254 "NoDataExists" ;
VAL_TABLE_ PtRmtRprt_D_Rq 15 "NotUsed_4" 14 "NotUsed_3" 13 "NotUsed_2" 12 "PlugInToMaintain12vBattery" 11 "SettingUpdated" 10 "FastChargeComplete" 9 "ChargeNotOccurring" 8 "OneTimeSocReached" 7 "BatteryTemperatureReminder" 6 "ReducedPerformance" 5 "LimitedPerformance" 4 "ChargeFault" 3 "ChargeComplete" 2 "VehiclePreconditioned" 1 "TripDistanceAchieved" 0 "NoReportRequest" ;
VAL_TABLE_ Invalid_NotReq_Req 0 "Invalid" 1 "Not_Requested" 2 "Requested" 3 "NotUsed" ;
VAL_TABLE_ Invalid_NoConflict_Conflict 7 "NotUsed5" 6 "NotUsed4" 5 "NotUsed3" 4 "NotUsed2" 3 "NotUsed1" 2 "Clonflict_Exists" 1 "No_Conflict" 0 "Invalid" ;
VAL_TABLE_ Inactive_NotReq_Req 0 "Inactive" 1 "Not_Requested" 2 "Requested" 3 "NotUsed" ;
VAL_TABLE_ PreCondStat_D_Dsply 7 "Reserved3" 6 "Reserved2" 5 "Reserved1" 4 "Faulted" 3 "Complete" 2 "In_Progress" 1 "Scheduled" 0 "Not_Scheduled" ;
VAL_TABLE_ BattElecPerf_D_Actl 7 "NotUsed" 6 "Hot_Batt_Severe_Lim_Perf" 5 "Hot_Batt_Reduced_Perf" 4 "Hot_Batt_Close_to_lim_Per" 3 "Cold_Batt_Severe_Lim_Perf" 2 "Cold_Batt_Reduced_Perf" 1 "Cold_Batt_Close_to_lim_Pe" 0 "Ok_no_message_displayed" ;
VAL_TABLE_ ChkPlgtoStrt_D_Dsply 3 "NotUsed" 2 "Is_VehicleUnplugged_Prompt" 1 "Check_Plug_to_Start" 0 "No_Message_Display" ;
VAL_TABLE_ PwrFlowTxt_D_Dsply 15 "NotUsed7" 14 "NotUsed6" 13 "NotUsed5" 12 "NotUsed4" 11 "Disply_Rgen_Chrg_Txt" 10 "Disp_Fast_Charge_Txt" 9 "Disp_Fast_Charge_Cmplt_Txt" 8 "Disp_Charge_Cmplt_Txt" 7 "Disp_Remote_Start_Txt" 6 "Disp_Eng_Drv_Txt" 5 "Disp_Elec_Drv_Txt" 4 "Disp_Idle_with_Chrg_Txt" 3 "Disp_Idle_Txt" 2 "Disp_Charg_HV_Batt_Txt" 1 "Disp_Hyb_Drive_Txt" 0 "No_Text" ;
VAL_TABLE_ EngOnMsg_D_Dsply 14 "_0xE_to_1F_NotUsed" 12 "Battery_Temperature" 11 "Hill_Decent_Control" 10 "Fuel_Maintenance" 9 "Oil_Maintenance" 8 "Normal_Operation" 7 "Low_Gear" 6 "Batt_Charging" 5 "Engine_Cold" 4 "Neutral_Gear" 3 "Heater_Setting" 2 "High_Speed" 1 "Acceleration" 0 "No_Display" 13 "Drive_Mode_Selection" ;
VAL_TABLE_ PtDataKeyId_D_Stat 15 "NotUsed5" 14 "NotUsed4" 13 "NotUsed3" 12 "NotUsed2" 11 "NotUsed1" 10 "Tot_Veh_NUT" 9 "Cust_4_NUT" 8 "Cust_3_NUT" 7 "Cust_2_NUT" 6 "Cust_1_NUT" 5 "Tot_Veh_Stat" 4 "Cust_4_Stat" 3 "Cust_3_Stat" 2 "Cust_2_Stat" 1 "Cust_1_Stat" 0 "Null" ;
VAL_TABLE_ ChrgStat_D_Dsply 7 "NotUsed" 6 "Complete" 5 "Scheduled" 4 "In_Progress" 3 "Fault_Outside_Car" 2 "Fault_Inside_Car" 1 "Fault_Unknown_Location" 0 "Not_Ready" ;
VAL_TABLE_ TrnLvrV_D_Rq 3 "Full_Speed" 2 "Aggressive" 1 "Normal" 0 "Quiet" ;
VAL_TABLE_ EngStrtStop_B_SrcOil 1 "Eng_start_stop_for_oilmnt" 0 "Not_Requested" ;
VAL_TABLE_ FuelMaintMde_D_Rq 3 "Feature_Not_Present" 2 "Fuel_Maint_Req_Now" 1 "Fuel_Maint_Req_Soon" 0 "NoRequest" ;
VAL_TABLE_ FuelMaintMde_D_Dsply 3 "Feature_Not_Present" 2 "In_Fuel_Maint_Mode" 1 "Close_to_Fuel_Maint" 0 "OK" ;
VAL_TABLE_ DynoMde_B_Cmd 1 "DynomometerMode" 0 "NormalOperation" ;
VAL_TABLE_ HvacPrecondRecirc_D_Rq 3 "Last_User_Setting" 2 "Auto" 1 "Recirc" 0 "Outside" ;
VAL_TABLE_ HvacPrecondAC_D_Rq 3 "Last_User_Setting" 2 "Auto" 1 "On" 0 "Off" ;
VAL_TABLE_ HybMdeStat_D_Dsply 7 "NotUsed2" 6 "EV_Charge" 5 "EV_Override" 4 "Forced_EV_Mode" 3 "Forced_Charge_Sustain_Mode" 2 "Auto_Charge_Sustain_Mode" 1 "Auto_Charge_Deplete_Mode" 0 "Null_State" ;
VAL_TABLE_ PwFlowPlgBatt_D_Dsply 3 "NotUsed" 2 "Flow_from_Plug_to_Batt" 1 "Flow_from_Batt_to_Plug" 0 "No_Flow" ;
VAL_TABLE_ PwFlowEngMtr_D_Dsply 3 "NotUsed" 2 "Flow_from_Eng_to_Mtr" 1 "Flow_from_Mtr_to_Eng" 0 "No_Flow" ;
VAL_TABLE_ PwFlowEngFuel_D_Dsply 3 "NotUsed" 2 "Flow_from_Eng_to_Fuel" 1 "Flow_from_Fuel_to_Eng" 0 "No_Flow" ;
VAL_TABLE_ PwFlowMtrDrv_D_Dsply 3 "NotUsed" 2 "Flow_from_Mtr_to_Axle" 1 "Flow_from_Axle_to_Mtr" 0 "No_FLow" ;
VAL_TABLE_ PwFlowEngDrv_D_Dsply 3 "NotUsed" 2 "Flow_from_Eng_to_Axle" 1 "Flow_from_Axle_to_Eng" 0 "No_Flow" ;
VAL_TABLE_ PwFlowBattMtr_D_Dsply 3 "NotUsed" 2 "Flow_from_Batt_to_Mtr" 1 "Flow_from_Mtr_to_Batt" 0 "No_Flow" ;
VAL_TABLE_ Null_Override_Invalid 3 "NotUsed" 2 "Invalid" 1 "Override" 0 "Null" ;
VAL_TABLE_ HybMdeLimMsgTxt_D_Rq 3 "Limited_Req_Full_Defrost" 2 "Limited_Climate_Defrost" 1 "Limited_System_Performance" 0 "Null" ;
VAL_TABLE_ CenterStackRing_D_Actl 3 "LimitedOn" 2 "On" 1 "Off" 0 "Null" ;
VAL_TABLE_ ConsTipUnitPt_D_Dsply 3 "NotUsed" 2 "FuelEconomy" 1 "Distance" 0 "Percentage" ;
VAL_TABLE_ ConsTipMsg1_D_Dsply 15 "NotUsed10" 14 "NotUsed9" 13 "NotUsed8" 12 "NotUsed7" 11 "NotUsed6" 10 "NotUsed5" 9 "NotUsed4" 8 "NotUsed3" 7 "NotUsed2" 6 "NotUsed1" 5 "ReduceIdleTime" 4 "ClimateUsage" 3 "VehicleSpeed" 2 "Deceleration" 1 "Acceleration" 0 "NoDisplay" ;
VAL_TABLE_ NoData_Faulty_FFFE_FFFF 65535 "Faulty" 65534 "NoDataExists" ;
VAL_TABLE_ NoData_Faulty_FFE_FFF 4095 "Faulty" 4094 "NoDataExists" ;
VAL_TABLE_ NoData_Faulty_7FFE_7FFF 32767 "Faulty" 32766 "NoDataExists" ;
VAL_TABLE_ NoData_Faulty_3FE_3FF 1023 "Faulty" 1022 "NoDataExists" ;
VAL_TABLE_ ReFuelSysStat_D_Dsply 7 "NotUsed3" 6 "NotUsed2" 5 "NotUsed1" 4 "Refuel_Err" 3 "Close_Fuel_Door" 2 "Refuel_Ready" 1 "Wait_To_Fuel" 0 "Null" ;
VAL_TABLE_ OffOn_NotUsed 3 "NotUsed2" 2 "NotUsed1" 1 "On" 0 "Off" ;
VAL_TABLE_ DrQltyDrv_D_StatGsm 7 "Faulty" 6 "NoDataExists" 5 "NotUsed2" 4 "NotUsed1" 3 "ClosedDegraded" 2 "OpenDegraded" 1 "ClosedOkay" 0 "OpenOkay" ;
VAL_TABLE_ ChrgrInPwType_D_Actl 6 "NotUsed3" 5 "NotUsed2" 4 "NotUsed1" 3 "DC_Fast_Charging" 2 "AC_Level2_240v" 1 "AC_Level1_120v" 0 "EVSE_Not_Detected" ;
VAL_TABLE_ BattTracHazrd_D_Stat 3 "NotUsed" 2 "HazardConfirmed" 1 "ExternalMonitoringRequired" 0 "NoHazardDetected" ;
VAL_TABLE_ SelDrvMde_1_31 31 "Faulty" 30 "SelDrvMde31" 29 "SelDrvMde30" 28 "SelDrvMde29" 27 "SelDrvMde28" 26 "SelDrvMde27" 25 "SelDrvMde26" 24 "SelDrvMde25" 23 "SelDrvMde24" 22 "SelDrvMde23" 21 "SelDrvMde22" 20 "SelDrvMde21" 19 "SelDrvMde20" 18 "SelDrvMde19" 17 "SelDrvMde18" 16 "SelDrvMde17" 15 "SelDrvMde16" 14 "SelDrvMde15" 13 "SelDrvMde14" 12 "SelDrvMde13" 11 "SelDrvMde12" 10 "SelDrvMde11" 9 "SelDrvMde10" 8 "SelDrvMde09" 7 "SelDrvMde08" 6 "SelDrvMde07" 5 "SelDrvMde06" 4 "SelDrvMde05" 3 "SelDrvMde04" 2 "SelDrvMde03" 1 "SelDrvMde02" 0 "SelDrvMde01" ;
VAL_TABLE_ PwRnngBoardT_D_Rq 3 "NotUsed" 2 "Timer2" 1 "Timer1" 0 "Inactive" ;
VAL_TABLE_ WndwRearHeat_D_Stat 7 "NotUsed" 6 "FetLiftLimitReached" 5 "FetOpenCircuit" 4 "FetOutputShortToPower" 3 "FetOutputShortToGround" 2 "FetNotControlled" 1 "OnPowerToLoad" 0 "OffNoPowerToLoad" ;
VAL_TABLE_ Faulty_7F 63 "Faulty" ;
VAL_TABLE_ DcacHw_D_Confg 15 "NotUsed_11" 14 "NotUsed_10" 13 "NotUsed_9" 12 "NotUsed_8" 11 "NotUsed_7" 10 "NotUsed_6" 9 "NotUsed_5" 8 "NotUsed_4" 7 "NotUsed_3" 6 "NotUsed_2" 5 "NotUsed_1" 4 "Power_2300W" 3 "Power_7200W" 2 "Power_2400W" 1 "Power_2000W" 0 "NoDcacHardware" ;
VAL_TABLE_ DcacFaltMsgTxt_D_Rq 15 "NotUsed" 14 "OvercurrentLP" 13 "EngineRun" 12 "Service" 11 "NotAvailable" 10 "PlugWarn" 9 "PlugWarnDrive" 8 "BreakerC" 7 "BreakerB" 6 "BreakerA" 5 "FuelLow" 4 "AcOnOutput" 3 "Temperature" 2 "Gfci" 1 "Overcurrent" 0 "Ok" ;
VAL_TABLE_ DcacLoFuelMsgTxt_D_Rq 31 "Minute_31" 30 "Minute_30" 29 "Minute_29" 28 "Minute_28" 27 "Minute_27" 26 "Minute_26" 25 "Minute_25" 24 "Minute_24" 23 "Minute_23" 22 "Minute_22" 21 "Minute_21" 20 "Minute_20" 19 "Minute_19" 18 "Minute_18" 17 "Minute_17" 16 "Minute_16" 15 "Minute_15" 14 "Minute_14" 13 "Minute_13" 12 "Minute_12" 11 "Minute_11" 10 "Minute_10" 9 "Minute_9" 8 "Minute_8" 7 "Minute_7" 6 "Minute_6" 5 "Minute_5" 4 "Minute_4" 3 "Minute_3" 2 "Minute_2" 1 "Minute_1" 0 "Ok" ;
VAL_TABLE_ DcacEngOnMsgTxt_D_Rq 3 "NotUsed" 2 "DisplayQuestion" 1 "DisplayWarning" 0 "Ok" ;
VAL_TABLE_ OffPendingActiveNotUsed 3 "NotUsed" 2 "Active" 1 "Pending" 0 "Off" ;
VAL_TABLE_ OffLowHighNotUsed 3 "NotUsed" 2 "High" 1 "Low" 0 "Off" ;
VAL_TABLE_ Null_Off_On_NoControl 3 "NoControl" 2 "On" 1 "Off" 0 "Null" ;
VAL_TABLE_ NotDeterminedNotPresentFaulty 3 "Faulty" 2 "Present" 1 "NotPresent" 0 "NotDetermined" ;
VAL_TABLE_ VehStrtInhbt_D_Dsply 15 "NotUsed_12" 14 "NotUsed_11" 13 "NotUsed_10" 12 "NotUsed_9" 11 "NotUsed_8" 10 "NotUsed_7" 9 "NotUsed_6" 8 "NotUsed_5" 7 "NotUsed_4" 6 "NotUsed_3" 5 "NotUsed_2" 4 "OtaSuccess" 3 "PostOtaActivatePermFail" 2 "PostOtaActivateWarning" 1 "DuringOtaActivate" 0 "NoMessage" ;
VAL_TABLE_ VehOnRqstr_D_Stat 11 "NotUsed_8" 10 "NotUsed_7" 9 "NotUsed_6" 8 "NotUsed_5" 7 "NotUsed_4" 6 "NotUsed_3" 5 "NotUsed_2" 4 "NotUsed_1" 3 "FleetVehInhbt" 2 "StolenVehInhbt" 1 "OverTheAir" 0 "NoRequestor" 15 "NotUsed_12" 14 "NotUsed_11" 13 "NotUsed_10" 12 "NotUsed_9" ;
VAL_TABLE_ OtaActv_D_Stat 15 "NotUsed_10" 14 "NotUsed_9" 13 "NotUsed_8" 12 "NotUsed_7" 11 "NotUsed_6" 10 "NotUsed_5" 9 "NotUsed_4" 8 "NotUsed_3" 7 "NotUsed_2" 6 "NotUsed_1" 5 "NonInterruptible_Pending" 4 "NonInterruptible_Config" 3 "NonInterruptible_ER" 2 "NonInterruptible_AB" 1 "Interruptible_AB" 0 "NoInVehicleOta" ;
VAL_TABLE_ ULoBattTransfer_D_Stat 7 "NotUsed_2" 6 "NotUsed_1" 5 "TransferError" 4 "TransferComplete" 3 "TransferThroughGridEnergy" 2 "InsufficientEnergyToXfer" 1 "TransferInProgress" 0 "NoTransfer" ;
VAL_TABLE_ PwRnngBoardPoll_D_Stat 3 "NotUsed" 2 "PkPresent" 1 "PkNotPresent" 0 "NotPolling" ;
VAL_TABLE_ InactiveOffOutAuto 0 "Inactive" 1 "Off" 2 "Out" 3 "Auto" ;
VAL_TABLE_ PwRnngBoardSwtch_D_Rq 3 "NotUsed" 2 "DeployUnlocked" 1 "AlwaysActive" 0 "Inactive" ;
VAL_TABLE_ LongCtrlEnbl_D_Rq 7 "NotUsed_4" 6 "NotUsed_3" 5 "NotUsed_2" 4 "NotUsed_1" 3 "RemoteParking" 2 "Autohitch" 1 "AutomaticParking" 0 "None" ;
VAL_TABLE_ BrkHold_D_Stat 7 "NotUsed_3" 6 "NotUsed_2" 5 "NotUsed_1" 4 "HeldSecondary" 3 "HeldSecure" 2 "Held" 1 "Inactive" 0 "Off" ;
VAL_TABLE_ AccStopStat_D_Dsply 3 "PressResume" 2 "Stopped" 1 "ResumeReady" 0 "NoDisplay" ;
VAL_TABLE_ TrlrHitch_D_RqMnu 15 "NotUsed_10" 14 "NotUsed_9" 13 "NotUsed_8" 12 "NotUsed_7" 11 "NotUsed_6" 10 "NotUsed_5" 9 "NotUsed_4" 8 "NotUsed_3" 7 "NotUsed_2" 6 "NotUsed_1" 5 "GoToTraileringDomain" 4 "Confirm" 3 "TurnOnTba" 2 "TurnOnAutohitch" 1 "CancelAutohitch" 0 "NoRequest" ;
VAL_TABLE_ DcacRdy_D2_Stat 3 "Faulted" 2 "RecoverableFault" 1 "Active" 0 "Idle" ;
VAL_TABLE_ NotFaulted_Faulted 1 "Faulted" 0 "NotFaulted" ;
VAL_TABLE_ Null_NotAccepted_Accepted 3 "NotUsed" 2 "Accepted" 1 "NotAccepted" 0 "Null" ;
VAL_TABLE_ LatCtl_D2_Rq 7 "NotUsed_5" 6 "NotUsed_4" 5 "NotUsed_3" 4 "NotUsed_2" 3 "SafeRampOut" 2 "PathFollowingExtendedMode" 1 "PathFollowingLimitedMode" 0 "NoLateralControl" ;
VAL_TABLE_ BattULoChrgHyb_D_Stat 7 "NotUsed_4" 6 "NotUsed_3" 5 "NotUsed_2" 4 "NotUsed_1" 3 "VehicleServiceRequired" 2 "EvRangeLossDueToLoadActive" 1 "BatteryServiceRequired" 0 "Null" ;
VAL_TABLE_ DrvEngageLevel_D_Stat 7 "Faulty" 6 "NotUsed_2" 5 "NotUsed_1" 4 "Disengaged" 3 "Distracted" 2 "Attentive" 1 "Invalid" 0 "NotDetermined" ;
VAL_TABLE_ DrvImpairLvl_D_Stat 15 "Faulty" 14 "NotUsed_5" 13 "NotUsed_4" 12 "NotUsed_3" 11 "NotUsed_2" 10 "NotUsed_1" 9 "Incapacitated" 8 "Asleep" 7 "Microsleep" 6 "MostDrowsy" 5 "Drowsy_4" 4 "Drowsy_3" 3 "Drowsy_2" 2 "LeastDrowsy" 1 "Alert" 0 "NotDetermined" ;
VAL_TABLE_ DrvAttentZone_D_Stat 15 "Faulty" 14 "NotUsed_5" 13 "NotUsed_4" 12 "NotUsed_3" 11 "NotConfigured" 10 "DriverLap" 9 "PassengerSideWindow" 8 "DriverSideWindow" 7 "DriverSideMirror" 6 "RearviewMirror" 5 "PassengerSideMirror" 4 "Infotainment" 3 "Cluster" 2 "FrontWindshield" 1 "Other" 0 "NotDetermined" ;
VAL_TABLE_ DrvAlertSt_D_Stat 3 "Faulty" 2 "EyesOffRoad" 1 "EyesOnRoad" 0 "NotDetermined" ;
VAL_TABLE_ DrvEngLvlConfid_D_Stat 7 "Faulty" 6 "NotUsed" 5 "High" 4 "MediumHigh" 3 "Medium" 2 "LowMedium" 1 "Low" 0 "NotDetermined" ;
VAL_TABLE_ DrvCamIR_D_Stat 3 "Faulty" 2 "Blocked" 1 "Ok" 0 "TemporaryUnavailable" ;
VAL_TABLE_ FrontDiffFalt_D_Stat 3 "Diff_Failed_Closed" 2 "Diff_Failed_Open" 1 "Fault_Non_Specific" 0 "No_Fault" ;
VAL_TABLE_ FrontDiffLckMsg_D_Rq 7 "LockerDisabled" 6 "LockerEnabled" 5 "LockerAccelPedal" 4 "Speed4" 3 "Speed3" 2 "Speed2" 1 "Speed1" 0 "NormalNoMessage" ;
VAL_TABLE_ PoliceDmngLvl_D_Stat 7 "NotUsed" 6 "Off_Night" 5 "Off_Day" 4 "Low1Night" 3 "Low1Day" 2 "Inactive" 1 "Decommissioned" 0 "Null" ;
VAL_TABLE_ AdbBeam_D_Rq 7 "NotUsed_3" 6 "NotUsed_2" 5 "NotUsed_1" 4 "FullHighBeam" 3 "Spot_BothSide" 2 "Spot_OnlyRightSide" 1 "Spot_OnlyLeftSide" 0 "NoHighBeam" ;
VAL_TABLE_ NoRequest_Up 1 "Up" 0 "NoRequest" ;
VAL_TABLE_ VehWlcmFrwl_D_Stat 3 "RunStart" 2 "Farewell" 1 "Welcome" 0 "Null" ;
VAL_TABLE_ VehWlcmFrwlMde_D_Stat 7 "IlluminatedExit" 6 "CourtesyLightingDelayExt" 5 "CourtesyLightingExtended" 4 "CourtesyLightingDelayAll" 3 "CourtesyLightingAll" 2 "IlluminatedEntry" 1 "Approach" 0 "Null" ;
VAL_TABLE_ OnePdlDrvBrk_D_Rq 3 "NotUsed" 2 "Active_FrictionBrakeStop" 1 "Active" 0 "Inactive" ;
VAL_TABLE_ OnePdlDrv_D_Stat 3 "Enabled_BrkLampAndFbrk" 2 "Enabled_BrkLamp" 1 "Enabled_NoAction" 0 "Disabled" ;
VAL_TABLE_ LatCtlCpblty_D_Stat 3 "Faulty" 2 "ExtendedModeAvailable" 1 "LimitedModeAvailable" 0 "NoModeAvailable" ;
VAL_TABLE_ HybMdeMsgTxt_D2_Rq 15 "NotUsed_4" 14 "NotUsed_3" 13 "NotUsed_2" 12 "NotUsed_1" 11 "EvOverride_Avail" 10 "EvLaterActv_EvAuto_NowAvai" 9 "EvNowActv_EvAuto_LaterAvai" 8 "EvAutoActv_EvNow_LaterAvai" 7 "EvAutoActv_NoOtherMdeAvail" 6 "EvChrgActv_EvAutoMdeAvail" 5 "EvAutoActv_EvChrgMdeAvail" 4 "EvChrgActv_AllPhevMdeAvail" 3 "EvLaterActv_AllPhevMdeAvai" 2 "EvNowActv_AllPhevMdeAvail" 1 "EvAutoActv_AllPhevMdeAvail" 0 "Null" ;
VAL_TABLE_ TsrRegionTxt_D_Stat 31 "Faulty" 30 "NotUsed_8" 29 "NotUsed_7" 28 "NotUsed_6" 27 "NotUsed_5" 26 "NotUsed_4" 25 "NotUsed_3" 24 "NotUsed_2" 23 "NotUsed_1" 22 "Region_22" 21 "Region_21" 20 "Region_20" 19 "Region_19" 18 "Region_18" 17 "Region_17" 16 "Region_16" 15 "Region_15" 14 "Region_14" 13 "Region_13" 12 "Region_12" 11 "Region_11" 10 "Region_10" 9 "Region_09" 8 "Region_08" 7 "Region_07" 6 "Region_06" 5 "Region_05" 4 "Region_04" 3 "Region_03" 2 "Region_02" 1 "Region_01" 0 "NotDetermined" ;
VAL_TABLE_ TrlrAidEnbl_D_RqAdas 7 "NotUsed_4" 6 "NotUsed_3" 5 "NotUsed_2" 4 "NotUsed_1" 3 "Deactivate" 2 "NotAvailable" 1 "ActiveTba" 0 "Inactive" ;
VAL_TABLE_ TrlrHitchIcon_D_Rq 15 "Icon15" 14 "Icon14" 13 "Icon13" 12 "Icon12" 11 "Icon11" 10 "Icon10" 9 "Icon9" 8 "Icon8" 7 "Icon7" 6 "Icon6" 5 "Icon5" 4 "Icon4" 3 "Icon3" 2 "Icon2" 1 "Icon1" 0 "NoIcon" ;
VAL_TABLE_ Inactive_On_NotUsed 7 "NotUsed_6" 6 "NotUsed_5" 5 "NotUsed_4" 4 "NotUsed_3" 0 "Inactive" 1 "On" 2 "NotUsed_1" 3 "NotUsed_2" ;
VAL_TABLE_ StabBarCnnct_D_Stat 15 "Faulty" 14 "NotUsed_7" 13 "NotUsed_6" 12 "NotUsed_5" 11 "NotUsed_4" 10 "NotUsed_3" 9 "NotUsed_2" 8 "NotUsed_1" 7 "SbdFailure2" 6 "SbdFailure1" 5 "Shutdown" 4 "NormalClosing" 3 "NormalOpen" 2 "NormalOpening" 1 "NormalClosed" 0 "Initialize" ;
VAL_TABLE_ TrlrHitchChime_D_Rq 7 "NotUsed_1" 6 "NotUsed_1" 5 "WarningChime" 4 "NonCriticalAlertChime" 3 "StopNowChime" 2 "ManeuveringReadyChime" 1 "TrailerFoundChime" 0 "NoChime" ;
VAL_TABLE_ _S_No_Yes 1 "Yes" 0 "No" ;
VAL_TABLE_ UpDownNotUsedFaulty 3 "Faulty" 2 "NotUsed" 1 "Down" 0 "Up" ;
VAL_TABLE_ PtWakeReas_D_Stat 15 "NotUsed_9" 14 "NotUsed_8" 13 "NotUsed_7" 12 "NotUsed_6" 11 "NotUsed_5" 10 "NotUsed_4" 9 "NotUsed_3" 8 "NotUsed_2" 7 "NotUsed_1" 6 "ElapsedTime" 5 "ThirdPartyWakeup" 4 "DoorAjar" 3 "EarlyWake" 2 "NonMotiveStart" 1 "MotiveStart" 0 "Null" ;
VAL_TABLE_ ExtLghtLeft_D_RqMnu 7 "NotUsed" 6 "PressToOn3" 5 "PressToOff3" 4 "PressToOn2" 3 "PressToOff2" 2 "PressToOn1" 1 "PressToOff1" 0 "Reset" ;
VAL_TABLE_ ExtLght_D_Falt 3 "Error" 2 "NoStationary" 1 "StartEngine" 0 "Null" ;
VAL_TABLE_ MildHybStat_D_Dsply 7 "NotUsed" 6 "Recovery" 5 "Charge" 4 "Assist" 3 "Boost" 2 "SystemInhibited" 1 "SystemError" 0 "Off" ;
VAL_TABLE_ ChrgCrdLck_D_Falt 3 "NotUsed" 2 "HardwareFault" 1 "CsiFault" 0 "NoFault" ;
VAL_TABLE_ BattTracClntVlv_D_Stat 7 "NotUsed" 6 "FetLifeLimitReached" 5 "FetOpenCircuit" 4 "FetOutputShortToPower" 3 "FetOutputShortToGround" 2 "FetNotControlled" 1 "OnPowerToLoad" 0 "OffNoPowerToLoad" ;
VAL_TABLE_ ChrgStat_D2_Dsply 15 "NotUsed_2" 14 "NotUsed_1" 13 "ChargeTargetReached" 12 "DriveConditioning" 11 "CabinPreconditioning" 10 "ChargingSystemMaintain" 9 "ChargingInductive" 8 "ChargingDCFastChange" 7 "ChargingAC" 6 "ChargeScheduled" 5 "EvsePaused" 4 "EvseNotDetected" 3 "EvseNotCompatible" 2 "FaultOutsideCar" 1 "FaultInsideCar" 0 "NotReady" ;
VAL_TABLE_ EngMdeMsgTxt_D_Rq 7 "NotUsed_3" 6 "NotUsed_2" 5 "NotUsed_1" 4 "Charge" 3 "GlowingCharge" 2 "Hybrid" 1 "Ev" 0 "NoMessage" ;
VAL_TABLE_ NoReqHiDecelLowDecel 3 "NotUsed" 2 "LowDecel" 1 "HighDecel" 0 "NoRequest" ;
VAL_TABLE_ BattRgenLoStat_D_Qlty 3 "OK" 2 "Not_Within_Spec" 1 "Eval_In_Progress" 0 "Faulty" ;
VAL_TABLE_ OpenClosedRetainDisable 3 "Disable" 2 "Retain" 1 "Closed" 0 "Open" ;
VAL_TABLE_ OpenClosedStuckOpenClosed 3 "StuckClosed" 2 "StuckOpen" 1 "Closed" 0 "Open" ;
VAL_TABLE_ OpenClosedRetainDoNotCare 3 "DoNotCare" 2 "Retain" 1 "Closed" 0 "Open" ;
VAL_TABLE_ _S_SurndSndUpmix 4 "Audience" 3 "On_Stage" 2 "Surround" 1 "Stereo" 0 "Inactive" ;
VAL_TABLE_ _S_Level1_to_127_8Bit 255 "NotUsed_127" 254 "NotUsed_126" 253 "NotUsed_125" 252 "NotUsed_124" 251 "NotUsed_123" 250 "NotUsed_122" 249 "NotUsed_121" 248 "NotUsed_120" 247 "NotUsed_119" 246 "NotUsed_118" 245 "NotUsed_117" 244 "NotUsed_116" 243 "NotUsed_115" 242 "NotUsed_114" 241 "NotUsed_113" 240 "NotUsed_112" 239 "NotUsed_111" 238 "NotUsed_110" 237 "NotUsed_109" 236 "NotUsed_108" 235 "NotUsed_107" 234 "NotUsed_106" 233 "NotUsed_105" 232 "NotUsed_104" 231 "NotUsed_103" 230 "NotUsed_102" 229 "NotUsed_101" 228 "NotUsed_100" 227 "NotUsed_99" 226 "NotUsed_98" 225 "NotUsed_97" 224 "NotUsed_96" 223 "NotUsed_95" 222 "NotUsed_94" 221 "NotUsed_93" 220 "NotUsed_92" 219 "NotUsed_91" 218 "NotUsed_90" 217 "NotUsed_89" 216 "NotUsed_88" 215 "NotUsed_87" 214 "NotUsed_86" 213 "NotUsed_85" 212 "NotUsed_84" 211 "NotUsed_83" 210 "NotUsed_82" 209 "NotUsed_81" 208 "NotUsed_80" 207 "NotUsed_79" 206 "NotUsed_78" 205 "NotUsed_77" 204 "NotUsed_76" 203 "NotUsed_75" 202 "NotUsed_74" 201 "NotUsed_73" 200 "NotUsed_72" 199 "NotUsed_71" 198 "NotUsed_70" 197 "NotUsed_69" 196 "NotUsed_68" 195 "NotUsed_67" 194 "NotUsed_66" 193 "NotUsed_65" 192 "NotUsed_64" 191 "NotUsed_63" 190 "NotUsed_62" 189 "NotUsed_61" 188 "NotUsed_60" 187 "NotUsed_59" 186 "NotUsed_58" 185 "NotUsed_57" 184 "NotUsed_56" 183 "NotUsed_55" 182 "NotUsed_54" 181 "NotUsed_53" 180 "NotUsed_52" 179 "NotUsed_51" 178 "NotUsed_50" 177 "NotUsed_49" 176 "NotUsed_48" 175 "NotUsed_47" 174 "NotUsed_46" 173 "NotUsed_45" 172 "NotUsed_44" 171 "NotUsed_43" 170 "NotUsed_42" 169 "NotUsed_41" 168 "NotUsed_40" 167 "NotUsed_39" 166 "NotUsed_38" 165 "NotUsed_37" 164 "NotUsed_36" 163 "NotUsed_35" 162 "NotUsed_34" 161 "NotUsed_33" 160 "NotUsed_32" 159 "NotUsed_31" 158 "NotUsed_30" 157 "NotUsed_29" 156 "NotUsed_28" 155 "NotUsed_27" 154 "NotUsed_26" 153 "NotUsed_25" 152 "NotUsed_24" 151 "NotUsed_23" 150 "NotUsed_22" 149 "NotUsed_21" 148 "NotUsed_20" 147 "NotUsed_19" 146 "NotUsed_18" 145 "NotUsed_17" 144 "NotUsed_16" 143 "NotUsed_15" 142 "NotUsed_14" 141 "NotUsed_13" 140 "NotUsed_12" 139 "NotUsed_11" 138 "NotUsed_10" 137 "NotUsed_9" 136 "NotUsed_8" 135 "NotUsed_7" 134 "NotUsed_6" 133 "NotUsed_5" 132 "NotUsed_4" 131 "NotUsed_3" 130 "NotUsed_2" 129 "NotUsed_1" 128 "Level127" 127 "Level126" 126 "Level125" 125 "Level124" 124 "Level123" 123 "Level122" 122 "Level121" 121 "Level120" 120 "Level119" 119 "Level118" 118 "Level117" 117 "Level116" 116 "Level115" 115 "Level114" 114 "Level113" 113 "Level112" 112 "Level111" 111 "Level110" 110 "Level109" 109 "Level108" 108 "Level107" 107 "Level106" 106 "Level105" 105 "Level104" 104 "Level103" 103 "Level102" 102 "Level101" 101 "Level100" 100 "Level99" 99 "Level98" 98 "Level97" 97 "Level96" 96 "Level95" 95 "Level94" 94 "Level93" 93 "Level92" 92 "Level91" 91 "Level90" 90 "Level89" 89 "Level88" 88 "Level87" 87 "Level86" 86 "Level85" 85 "Level84" 84 "Level83" 83 "Level82" 82 "Level81" 81 "Level80" 80 "Level79" 79 "Level78" 78 "Level77" 77 "Level76" 76 "Level75" 75 "Level74" 74 "Level73" 73 "Level72" 72 "Level71" 71 "Level70" 70 "Level69" 69 "Level68" 68 "Level67" 67 "Level66" 66 "Level65" 65 "Level64" 64 "Level63" 63 "Level62" 62 "Level61" 61 "Level60" 60 "Level59" 59 "Level58" 58 "Level57" 57 "Level56" 56 "Level55" 55 "Level54" 54 "Level53" 53 "Level52" 52 "Level51" 51 "Level50" 50 "Level49" 49 "Level48" 48 "Level47" 47 "Level46" 46 "Level45" 45 "Level44" 44 "Level43" 43 "Level42" 42 "Level41" 41 "Level40" 40 "Level39" 39 "Level38" 38 "Level37" 37 "Level36" 36 "Level35" 35 "Level34" 34 "Level33" 33 "Level32" 32 "Level31" 31 "Level30" 30 "Level29" 29 "Level28" 28 "Level27" 27 "Level26" 26 "Level25" 25 "Level24" 24 "Level23" 23 "Level22" 22 "Level21" 21 "Level20" 20 "Level19" 19 "Level18" 18 "Level17" 17 "Level16" 16 "Level15" 15 "Level14" 14 "Level13" 13 "Level12" 12 "Level11" 11 "Level10" 10 "Level9" 9 "Level8" 8 "Level7" 7 "Level6" 6 "Level5" 5 "Level4" 4 "Level3" 3 "Level2" 2 "Level1" 1 "Level0" 0 "Inactive" ;
VAL_TABLE_ NoData_Faulty_7FE_7FF 2047 "Faulty" 2046 "NoDataExists" ;
VAL_TABLE_ DrTgateChime2_D_Rq 7 "NotUsed3" 6 "NotUsed2" 5 "NotUsed1" 4 "Long_Repeated" 3 "Fast" 2 "Short" 1 "Long" 0 "Off" ;
VAL_TABLE_ EngIdlShutDwnTxt_D_Rq 3 "NotUsed" 2 "EngineShutdownOnPrevDrive" 1 "FeatureDisabledDueToFault" 0 "NoMessage" ;
VAL_TABLE_ DrvPerfMde 3 "Sport" 2 "Normal" 1 "NotUsed" 0 "NoModeSelected" ;
VAL_TABLE_ NoData_Fault_1FF_1FE 511 "Fault" 510 "NoDataExists" ;
VAL_TABLE_ NoData_Fault_FFE_FFF 4095 "Fault" 4094 "NoDataExists" ;
VAL_TABLE_ EngIdlShutDown_D_Stat 3 "Not_used" 2 "Engine_Shutdown" 1 "Initiated_Countdown" 0 "Normal_Operation" ;
VAL_TABLE_ StopStrtDrvMde_D_Indic 3 "NotUsed" 2 "StartStop_IndirectDeselect" 1 "StopStart_Deselected" 0 "StopStart_Selected" ;
VAL_TABLE_ StopStrtDrvMde_D_RqMnu 3 "NotUsed2" 2 "NotUsed1" 1 "StopStart_Deselected" 0 "StopStart_Selected" ;
VAL_TABLE_ StopStrtStdby_D_Indic 6 "NotUsed2" 5 "Telltale_Struck_Out" 4 "Telltale_Flashing_Amber" 3 "Telltale_On_Amber" 2 "Telltale_Flashing_Green" 1 "Telltale_On_Green" 0 "Telltale_Off" 7 "NotUsed3" ;
VAL_TABLE_ Quality_Faulty 3 "OK" 2 "Degraded" 1 "No_Data_Exists" 0 "Faulty" ;
VAL_TABLE_ TrnDtpCmd_D_Actl 7 "NotUsed4" 6 "NotUsed3" 5 "NotUsed2" 4 "Relatch" 3 "Deploy" 2 "Self_Test" 1 "No_Command" 0 "NotUsed1" ;
VAL_TABLE_ TrnGsmNtmState_D_Actl 3 "Faulty" 2 "Neutral_Tow_Mode" 1 "Car_Wash_Mode" 0 "None" ;
VAL_TABLE_ TrnTrcmPwmSig_D_Actl 15 "Faulty" 14 "NoDataExists" 13 "NotUsed5" 12 "NotUsed4" 11 "NotUsed3" 10 "NotUsed2" 9 "NotUsed1" 8 "Default_To_Park" 7 "Neutral_Tow" 6 "Car_Wash_Mode" 5 "Manual" 4 "Drive" 3 "Neutral" 2 "Reverse" 1 "Park" 0 "No_Gear" ;
VAL_TABLE_ RgenBrkDynoMde_B_Actl 1 "TwoWheelDyno" 0 "NormalOperation" ;
VAL_TABLE_ Fault_3FFF 16383 "Fault" ;
VAL_TABLE_ PrkBrkActv_D_RqTrnGear 3 "NotUsed2" 2 "RequestParkBrakeEngage" 1 "NoRequest" 0 "NotUsed1" ;
VAL_TABLE_ NoRequest_Request 1 "Request" 0 "NoRequest" ;
VAL_TABLE_ Fault_FFF_NoData 4094 "NoDataExists" 4095 "Fault" ;
VAL_TABLE_ Fault_3FF_NoData 1022 "NoDataExists" 1023 "Fault" ;
VAL_TABLE_ Foh_D_Stat 7 "Unused3" 6 "Unused2" 5 "Unused1" 4 "Stopping" 3 "Running" 2 "Starting" 1 "Prestart" 0 "Off" ;
VAL_TABLE_ OffOnNoDataUnused 3 "Unused" 2 "NoDataExists" 1 "On" 0 "Off" ;
VAL_TABLE_ FohFalt_D_Stat 15 "NotUsed4" 14 "NotUsed3" 13 "NotUsed2" 12 "NotUsed1" 11 "FuelTypeDoesNotMatchFOH" 10 "Lifecycle_ModeNotSet" 9 "AuxElectricCoolantPumpInop" 8 "TimeDelayAvoidExcessCycl" 7 "Fuel_Level_OutofRange" 6 "External_Fault" 5 "Internal_Fault" 4 "Voltage_limitation" 3 "Impact_Event" 2 "CoolantTemp_OutofRange" 1 "AmbientTemp_OutofRange" 0 "No_Disable" ;
VAL_TABLE_ FohRqRun_B_Rq 1 "SubmitRequest_toRun" 0 "DoesNotSubmitRequest_toRun" ;
VAL_TABLE_ OKLowVeryLow 3 "NotUsed" 2 "VeryLow" 1 "Low" 0 "OK" ;
VAL_TABLE_ Fault_1FF 511 "Fault" ;
VAL_TABLE_ SteWhlHeat 15 "NotUsed6" 14 "NotUsed5" 13 "NotUsed4" 12 "NotUsed3" 11 "NotUsed2" 10 "NotUsed1" 9 "Reserved_3" 8 "Reserved_2" 7 "Reserved_1" 6 "Level_3_Heating" 5 "Level_3_Heating_LS" 4 "Level_2_Heating" 3 "Level_2_Heating_LS" 2 "Level_1_Heating" 1 "Level_1_Heating_LS" 0 "Off" ;
VAL_TABLE_ OffOnUnusedFault 3 "Fault" 2 "Unused" 1 "On" 0 "Off" ;
VAL_TABLE_ NullKphMph 3 "NoDataExists" 2 "Mph" 1 "Kph" 0 "Null" ;
VAL_TABLE_ TsrVLim1MsgTxt_D_Rq 255 "NoLimit" 254 "NotUsed2" 253 "NotUsed1" 252 "NotToBeDisplayed" 251 "LimitCancelled" 31 "1F_FA_Message31_250" 30 "Message30" 29 "Message29" 28 "Message28" 27 "Message27" 26 "Message26" 25 "Message25" 24 "Message24" 23 "Message23" 22 "Message22" 21 "Message21" 20 "Message20" 19 "Message19" 18 "Message18" 17 "Message17" 16 "Message16" 15 "Message15" 14 "Message14" 13 "Message13" 12 "Message12" 11 "Message11" 10 "Message10" 9 "Message9" 8 "Message8" 7 "Message7" 6 "Message6" 5 "Message5" 4 "Message4" 3 "Message3" 2 "Message2" 1 "Message1" 0 "Null" ;
VAL_TABLE_ TsrVl1RstrcMsgTxt_D_Rq 3 "NotUsed" 2 "NoRecognizableRestriction" 1 "NoSpeedLimitRestriction" 0 "Null" ;
VAL_TABLE_ TsrMsgTxt_D_Rq 15 "NotUsed6" 14 "NotUsed5" 13 "NotUsed4" 12 "NotUsed3" 11 "NotUsed2" 10 "NotUsed1" 9 "RecgnzdSignNotUsblForDsply" 8 "LimitedSystemPerformance" 7 "OffRoad" 6 "RegionNotSupported" 5 "CountryNotSupported" 4 "WrngNavDatIncompDatCarrier" 3 "NoNavDataAvailable" 2 "NoNavAvailableSwitchedOff" 1 "NoInformationAllOK" 0 "Null" ;
VAL_TABLE_ TsrOvtkStatMsgTxt_D_Rq 3 "LimitOutdated" 2 "LimitReiable" 1 "LimitChanged" 0 "Null" ;
VAL_TABLE_ TsrOvtkMsgTxt_D_Rq 7 "LimForTrucksCancelled" 6 "LimForTrucksWoQlfdRstrc" 5 "LimForTrucksWithoutRstrc" 4 "LimAllCancelled" 3 "LimAllWithoutQlfdRstrc" 2 "LimAllWithoutRestriction" 1 "OvertakingAllowed" 0 "Null" ;
VAL_TABLE_ Null_False_True 3 "NotUsed" 2 "True" 1 "False" 0 "Null" ;
VAL_TABLE_ TsrStatMsgTxt_D_Rq 7 "NotUsed" 6 "NoDataExists" 5 "TSR_Error" 4 "Available_NavigationOnly" 3 "Available_CameraOnly" 2 "Available_FusionMode" 1 "TSR_Off" 0 "Null" ;
VAL_TABLE_ NoMessage_DisplayMessage 1 "DisplayMessage" 0 "NoMessage" ;
VAL_TABLE_ FdsmTrgRight 1 "Object_in_Right_Lobe" 0 "No_Object" ;
VAL_TABLE_ FdsmTrgCntr 1 "Object_in_Center_Lobe" 0 "No_Object" ;
VAL_TABLE_ FdsmTrgLeft 1 "Object_in_Left_Lobe" 0 "No_Object" ;
VAL_TABLE_ EngineBrakeOff_Active 1 "Engine_Braking_Activated" 0 "Engine_Braking_Off" ;
VAL_TABLE_ NoEngineBrake_Brake 1 "Engine_Braking" 0 "No_Engine_Braking" ;
VAL_TABLE_ PlgActv_D_ActlChrgr 3 "Faulty" 2 "NoDataExists" 1 "On_Plug__Connected_" 0 "Off_Plug__Disconnected_" ;
VAL_TABLE_ EngSrvcRqd_B_Rq 1 "Engine_Service_Required" 0 "No_engine_service_required" ;
VAL_TABLE_ LscmbbBaSens_D_Rq 3 "Level3_EBA" 2 "Level2_EBA" 1 "Level1_EBA" 0 "Norman_EBA" ;
VAL_TABLE_ Allowed_Denied 1 "Denied" 0 "Allowed" ;
VAL_TABLE_ LscmbbBrkPrchg_D_Rq 3 "NotUsed" 2 "Level2_PreCharge" 1 "Level1_PreCharge" 0 "No_Precharge" ;
VAL_TABLE_ LscmbbBrkDecel_B_Enabl 1 "ConductLSCMbBDecelReq" 0 "DoNotConductLSCMbBDecelReq" ;
VAL_TABLE_ PrkAidMsgTxt_D_Rq 15 "All_Sns_Blk" 14 "R_Sns_ON_F_Sns_Blk" 13 "R_Sns_Blk_F_Sns_ON" 12 "R_Sns_Inactive_Trlr_atch" 11 "Not_Avail_Trlr_attchd" 10 "Fail_Mode_no_Chime" 9 "Fail_Mode_with_Chime" 8 "R_Sns_Trlr_F_Sns_Blk" 7 "NotUsed3" 6 "Park_Sys_Alternate_Mode" 5 "R_Snsrs_On_F_Snsrs_On" 4 "NotUsed2" 3 "Reset_Message_Warn" 2 "R_Snsrs_Off_F_Snsrs_On" 1 "R_Snsrs_On_F_Snsrs_Off" 0 "All_Park_Sensors_Off" ;
VAL_TABLE_ PrkAidSns_D_Stat 15 "Zone_15" 14 "Zone_14" 13 "Zone_13" 12 "Zone_12" 11 "Zone_11" 10 "Zone_10" 9 "Zone_9" 8 "Zone_8" 7 "Zone_7" 6 "Zone_6" 5 "Zone_5" 4 "Zone_4" 3 "Zone_3" 2 "Zone_2" 1 "Zone_1" 0 "Off" ;
VAL_TABLE_ PrkAid_D_Falt 7 "NotUsed2" 6 "NotUsed1" 5 "Failure_Front_PSM_Sensors" 4 "No_Data_Exists" 3 "Failure_Rear_Sensors" 2 "Speaker_Fault" 1 "ECU_Fault" 0 "No_Fault" ;
VAL_TABLE_ OffOnNoDataFault 3 "Fault" 2 "No_Data_Exists" 1 "On" 0 "Off" ;
VAL_TABLE_ ApaActvSd_D_Actl 3 "Dirver_Side" 2 "Passenger_Side" 1 "No_Side" 0 "Null" ;
VAL_TABLE_ ApaMdeStat_D_RqDrv 7 "Faulty" 6 "Off" 5 "NotUsed2" 4 "NotUsed1" 3 "POA" 2 "PPA" 1 "SAPP" 0 "Inactive" ;
VAL_TABLE_ ApaMde_D_Avail 15 "NotUsed7" 14 "NotUsed6" 13 "NotUsed5" 12 "NotUsed4" 11 "NotUsed3" 10 "NotUsed2" 9 "NotUsed1" 8 "PPA_POA" 7 "SAPP_POA" 6 "POA" 5 "PPA" 4 "SAPP" 3 "SAPP_PPA_POA" 2 "SAPP_PPA" 1 "None" 0 "Null" ;
VAL_TABLE_ ApaMde_D_Stat 7 "NotUsed3" 6 "NotUsed2" 5 "NotUsed1" 4 "POA" 3 "PPA" 2 "SAPP" 1 "Off" 0 "Null" ;
VAL_TABLE_ FrostWarn_D_Stat 3 "NotUsed" 2 "On_Amber" 1 "On_Red" 0 "Off" ;
VAL_TABLE_ SteWhlLckMsgTxt_D_Rq 3 "NotUsed" 2 "Message_2" 1 "Message_1" 0 "No_Message" ;
VAL_TABLE_ GearRvrse_D_Actl 7 "Fault" 6 "NotUsed_3" 5 "NotUsed_2" 4 "NotUsed_1" 3 "Active_confirmed" 2 "Active_not_confirmed" 1 "Inactive_confirmed" 0 "Inactive_not_confirmed" ;
VAL_TABLE_ SideDetect_SnStat_Invalid 3 "Invalid" 2 "System_Failure" 1 "Blocked" 0 "Clear" ;
VAL_TABLE_ SideDetect_OpStat 7 "NotUsed_3" 6 "NotUsed_2" 5 "NotUsed_1" 4 "Invalid" 3 "Disabled" 2 "On" 1 "Trailer_Tow_Off" 0 "Off" ;
VAL_TABLE_ SideDetect_Present 4 "Sensor_Blocked" 3 "Sensor_Fault" 2 "Flash_On" 1 "Alert_On" 0 "AlertOff_FlashOff_SensrClr" ;
VAL_TABLE_ Off_On_Flash_BulbProveout 3 "Bulb_Proveout" 2 "Flash" 1 "On" 0 "Off" ;
VAL_TABLE_ SideDetect_BLIS_Off_On 2 "BLIS_On_Second_Warning_ON" 1 "BLIS_On_Second_Warning_OFF" 0 "Off" ;
VAL_TABLE_ DrTGate_D_Rq 3 "NotUsed" 2 "Closing" 1 "Opening" 0 "Not_Moving" ;
VAL_TABLE_ WndwSide_D_Stat 3 "BothWindow_Operating" 2 "RearWindow_Operating" 1 "FrontWindow_Operating" 0 "NoWindows_Operating" ;
VAL_TABLE_ DcacElPw_D_Rq 3 "NotUsed" 2 "AC_HighPower_Requested" 1 "AC_LowPower_Requested" 0 "AC_Power_NotRequested" ;
VAL_TABLE_ False_True 1 "True" 0 "False" ;
VAL_TABLE_ Null_Reset 1 "Reset" 0 "Null" ;
VAL_TABLE_ Unknown_FFFD_Invalid_NotSup 65535 "Not_Supported" 65534 "Invalid" 65533 "Unknown" ;
VAL_TABLE_ HvacBlwrFront_D_Stat 31 "Not_Used" 20 "Full_On" 19 "95_Percent" 18 "90_Percent" 17 "85_Percent" 16 "80_Percent" 15 "75_Percent" 14 "70_Percent" 13 "65_Percent" 12 "60_Percent" 11 "55_Percent" 10 "50_Percent" 9 "45_Percent" 8 "40_Percent" 7 "35_Percent" 6 "30_Percent" 5 "25_Percent" 4 "20_Percent" 3 "15_Percent" 2 "10_Percent" 1 "5_Percent" 0 "Off" ;
VAL_TABLE_ immoMsgTxt_D_Rq 15 "Immo_Msg_15" 14 "Immo_Msg_14" 13 "Immo_Msg_13" 12 "Immo_Msg_12" 11 "Immo_Msg_11" 10 "Immo_Msg_10" 9 "Immo_Msg_9" 8 "Immo_Msg_8" 7 "Immo_Msg_7" 6 "Immo_Msg_6" 5 "Immo_Msg_5" 4 "Immo_Msg_4" 3 "Immo_Msg_3" 2 "Immo_Msg_2" 1 "Immo_Msg_1" 0 "Immo_Msg_0_Null" ;
VAL_TABLE_ BattTracWarnLamp_B_Rq 1 "On" 0 "Off" ;
VAL_TABLE_ BattTracSrvcRqd_B_Rq 1 "On" 0 "Off" ;
VAL_TABLE_ HtrnWarnLamp_B_Dsply 1 "On" 0 "Off" ;
VAL_TABLE_ HtrnSrvcRqd_B_Dsply 1 "On" 0 "Off" ;
VAL_TABLE_ NoData_Faulty_7E_7F 127 "Faulty" 126 "NoDataExists" ;
VAL_TABLE_ PtWakeupActv1_B_Rq 1 "Wake_up_Powertrain_via_HW" 0 "Don_t_Wake_Up_Powertrain" ;
VAL_TABLE_ Disp_LangSel_St 31 "NotUsed_1" 30 "Slovak" 29 "Arabic" 28 "Taiwanese" 27 "Mandarin_Chinese" 26 "Korean" 25 "AU_English" 24 "Japanese" 23 "Braz_Portuguese" 22 "EU_Portuguese" 21 "Finish" 20 "Norwegian" 19 "Danish" 18 "Swedish" 17 "Hungarian" 16 "Greek" 15 "Czech" 14 "Polish" 13 "Flemish" 12 "Dutch" 11 "Russian" 10 "Turkish" 9 "Mex_Spanish" 8 "EU_Spanish" 7 "Cana_French" 6 "EU_French" 5 "Italian" 4 "German" 3 "NA_English" 2 "UK_English" 1 "Unknown" 0 "Invalid" ;
VAL_TABLE_ Diagnostic_Operation_Rq 7 "SignalStrength" 6 "SDARSESNNumber" 5 "SpeakerWalkAround" 4 "CalibrationPartNumber" 15 "Reserved" 3 "HardwarePartNumber" 2 "SoftwarePartNumber" 1 "GetAllBackgroundDiagRq" 0 "Inactive" ;
VAL_TABLE_ Bezel_Diag_Module_Rq 15 "Reserved" 3 "EFP" 2 "DSP_AMP" 1 "AHU" 0 "Inactive" ;
VAL_TABLE_ Surround_Sound_Upmix 2 "Surround" 1 "Stereo" 0 "Inactive" ;
VAL_TABLE_ HMI_HMIMode_St 7 "NotUsed2" 6 "NotUsed1" 5 "Load_Shed_Active" 0 "Invalid" 1 "OffMode" 2 "On" 3 "Phone" 4 "Climate" ;
VAL_TABLE_ FuelPumpPwr_D_Stat 7 "NotUsed3" 6 "NotUsed2" 5 "NotUsed1" 4 "Power_Off_Default" 3 "Power_Off_Command" 2 "Power_Off_Service" 1 "Power_Off_Impact" 0 "Power_On" ;
VAL_TABLE_ ChrgrRdyStat_D_Actl 7 "NotUsed4" 6 "NotUsed3" 5 "NotUsed2" 4 "NotUsed1" 3 "Charging" 2 "ChargerFault" 1 "ChargerReady" 0 "NotReady" ;
VAL_TABLE_ PrmtrAlrmEvnt_D_Stat 15 "Diag_Tamper" 14 "Trailer" 13 "Shock_Sensor" 12 "Post_Crash" 11 "Panic" 10 "Intrusion" 9 "Inclination" 8 "Ign_Tamper" 7 "LG_Door" 6 "Decklid" 5 "Hood" 4 "PR_Door" 3 "PF_Door" 2 "DR_Door" 1 "DF_Door" 0 "Null" ;
VAL_TABLE_ SecurityMsgTxt_D_Rq 3 "Message3" 2 "Message2" 1 "Message1" 0 "NoMessage" ;
VAL_TABLE_ BattChrgRdyStat_D_Actl 7 "NotUsed2" 6 "NotUsed1" 5 "Faulted" 4 "ChargeComplete" 3 "Charging" 2 "BatteryChargeReady" 1 "ChargeWait" 0 "NotReady" ;
VAL_TABLE_ BattChrgInhbt_D_Rq 3 "MaintainTargetSoc" 2 "NotUsed" 1 "InhibitChargingThermal" 0 "Enable_Charging" ;
VAL_TABLE_ Fault_7FF_NoData 2047 "Fault" 2046 "NoDataExists" ;
VAL_TABLE_ Deactivate_Activate 1 "Activate" 0 "Deactivate" ;
VAL_TABLE_ PtcHtr_D_Stat 3 "Faulty" 2 "NotUsed" 1 "On" 0 "Off" ;
VAL_TABLE_ PtcHtr_D_Cmd 3 "TurnOn" 2 "AutoMode" 1 "TurnOff" 0 "NoDecision_Initializing" ;
VAL_TABLE_ Fault_FFFFFF 16777215 "Fault" ;
VAL_TABLE_ NoData_Fault_FFFE_FFFF 65535 "Fault" 65534 "NoDataExists" ;
VAL_TABLE_ EngOffTe_B_Dsply 1 "Eng_warm_engh_for_pd" 0 "Eng_not_warm_engh_for_pd" ;
VAL_TABLE_ DrvEffLvlIncDec_D_Cmd 3 "NotUsed" 2 "Decrease_Level_by_1" 1 "Increase_Level_by_1" 0 "Null_State" ;
VAL_TABLE_ Fault_FFFF_NoData_FFFE 65535 "Fault" 65534 "NoDataExists" ;
VAL_TABLE_ Fault_1FFF 8191 "Fault" ;
VAL_TABLE_ TrlrBattChrg_D_Stat 3 "Reverse" 2 "Normal" 1 "Low" 0 "Null" ;
VAL_TABLE_ TrlrLampCtl_D_Stat 3 "NotUsed" 2 "TrlrLampCnnctDrvFailure" 1 "TrlrLampNotCnnctDrvFailure" 0 "Null" ;
VAL_TABLE_ ElPw_D_StatStrtStop 15 "NotUsed6" 14 "NotUsed5" 13 "NotUsed4" 12 "NotUsed3" 11 "NotUsed2" 10 "NotUsed1" 9 "Supported_Level_4" 8 "Supported_Level_3" 7 "Supported_Level_2" 6 "Supported_Level_1" 5 "Limited_Support" 4 "Fault_Limited" 3 "LV_Event_in_Progress" 2 "Not_Supported_Imminent" 1 "Supported_All" 0 "Not_Supported" ;
VAL_TABLE_ ImpactEvntFdbck_D_Stat 3 "NotUsed" 2 "EventComplete" 1 "EventInProgress" 0 "Normal" ;
VAL_TABLE_ StopStrtIODTxt_D_Rq 31 "Message31" 30 "Message30" 29 "Message29" 28 "Message28" 27 "Message27" 26 "Message26" 25 "Message25" 24 "Message24" 23 "Message23" 22 "Message22" 21 "Message21" 20 "Message20" 19 "Message19" 18 "Message18" 17 "Message17" 16 "Message16" 15 "Message15" 14 "Message14" 13 "Message13" 12 "Message12" 11 "Message11" 10 "Message10" 9 "Message9" 8 "Message8" 7 "Message7" 6 "Message6" 5 "Message5" 4 "Message4" 3 "Message3" 2 "Message2" 1 "Message1" 0 "NoMessage" ;
VAL_TABLE_ NoData_Fault_7FFE_7FFF 32767 "Fault" 32766 "NoDataExists" ;
VAL_TABLE_ NoData_Fault_3E_3F 63 "Fault" 62 "NoDataExists" ;
VAL_TABLE_ DrvSte_D_Stat 15 "NotUsed10" 14 "NotUsed9" 13 "NotUsed8" 12 "NotUsed7" 11 "NotUsed6" 10 "NotUsed5" 9 "NotUsed4" 8 "NotUsed3" 7 "NotUsed2" 6 "NotUsed1" 5 "Request_Active" 4 "Ignition_Off" 3 "DSR_in_Normal_Idle_Mode" 2 "EPAS_Comm_Disturbed" 1 "DSR_Request_Not_Applicable" 0 "DSR_Deactivated" ;
VAL_TABLE_ StrtrMtrCtlMsgTxt_D_Rq 7 "Start_In_Gear_Allowed" 6 "Pending_Start_Cancelled" 5 "Start_Pending_Please_Wait" 4 "Cranking_Limit_Exceeded" 3 "Press_Brk_and_Shift_to_P_N" 2 "Press_Clutch_and_Brake" 1 "Press_Clutch_To_Start" 0 "No_Display" ;
VAL_TABLE_ Null_Open 1 "Open" 0 "Null" ;
VAL_TABLE_ Invalid_OffOn 0 "Invalid" 1 "Off" 2 "On" ;
VAL_TABLE_ TempDegreesC_DegreesF 0 "Temperature_deg_c" 1 "Temperature_deg_f" ;
VAL_TABLE_ BeltminderAudioMute 2 "On" 1 "Off" 0 "Invalid" ;
VAL_TABLE_ Chime_Source 2 "Cluster" 1 "Infotainment_Sys" 0 "Invalid" ;
VAL_TABLE_ Invalid_DayNight 2 "Night" 1 "Day" 0 "Invalid" ;
VAL_TABLE_ Invalid_12h_24h 2 "24h_mode" 1 "12h_mode" 0 "Invalid" ;
VAL_TABLE_ Invalid_Theme1_2 2 "Theme_2" 1 "Theme_1" 0 "Invalid" ;
VAL_TABLE_ LanguageSelect_St 32 "Indian_English" 31 "Thai" 30 "Slovak" 29 "Arabic" 28 "Cantonese" 27 "Mandarin_Chinese" 26 "Korean" 25 "Japanese_Kanji" 24 "Japanese_Katakana" 23 "Braz_Portuguese" 22 "EU_Portuguese" 21 "Finish" 20 "Norwegian" 19 "Danish" 18 "Swedish" 17 "Hungarian" 16 "Greek" 15 "Czech" 14 "Polish" 13 "Flemish" 12 "Dutch" 11 "Russian" 10 "Turkish" 9 "Mex_Spanish" 8 "EU_Spanish" 7 "Cana_French" 6 "EU_French" 5 "Italian" 4 "German" 3 "NA_English" 2 "UK_English" 1 "Unknown" 0 "Invalid" ;
VAL_TABLE_ Blower_Indicate 15 "Display_Blank" 14 "14_Indicators_On" 13 "13_Indicators_On" 12 "12_Indicators_On" 11 "11_Indicators_On" 10 "10_Indicators_On" 9 "9_Indicators_On" 8 "8_Indicators_On" 7 "7_Indicators_On" 6 "6_Indicators_On" 5 "5_Indicators_On" 4 "4_Indicators_On" 3 "3_Indicators_On" 2 "2_Indicators_On" 1 "1_Indicator_On" 0 "Indicators_Off" ;
VAL_TABLE_ CC_Fr_Stat_User_Adj 7 "Unused4" 6 "RHS_AUTO_St_Selection" 5 "LHS_AUTO_St_Selection" 4 "DrvrFcsdMde_Selection" 3 "Fr_Blwr_Spd_Selection" 2 "FRHS_SetPt_Selection" 1 "FLHS_SetPt_Selection" 0 "None" ;
VAL_TABLE_ HeadLghtHiFdbck_D_Stat 3 "NotUsed" 2 "Cancel" 1 "Hold" 0 "Allow_Change" ;
VAL_TABLE_ Backlit_LED_Status 15 "Unused3" 14 "Unused2" 13 "Unused1" 12 "Night_12" 11 "Night_11" 10 "Night_10" 9 "Night_9" 8 "Night_8" 7 "Night_7" 6 "Night_6" 5 "Night_5" 4 "Night_4" 3 "Night_3" 2 "Night_2" 1 "Night_1" 0 "Off" ;
VAL_TABLE_ Veh_Lock_Status 3 "UNLOCK_DRV" 2 "UNLOCK_ALL" 1 "LOCK_ALL" 0 "LOCK_DBL" ;
VAL_TABLE_ PrkLckCtlMsgTxt_D_Rq 3 "BTSI_DI_3" 2 "BTSI_DI_2" 1 "BTSI_DI_1" 0 "Null_BTSI_DI" ;
VAL_TABLE_ NoShift_Shift 1 "Shift" 0 "NoShift" ;
VAL_TABLE_ CcdMsgTxt_D_RqDsply 15 "Unused8" 14 "Unused7" 13 "Unused6" 12 "Unused5" 11 "Unused4" 10 "Unused3" 9 "Unused2" 8 "StationaryMode" 7 "Mode_Change_Unavailable" 6 "CCD_Temporarily_Off" 5 "CCD_Service_Required" 4 "Faulty" 3 "Sport" 2 "Normal" 1 "Comfort" 0 "No_Mode_Selected" ;
VAL_TABLE_ CrashEvnt_D_Stat 3 "Invalid" 2 "Fuel_Cutoff_Event" 1 "Deploy_Event" 0 "No_Event" ;
VAL_TABLE_ ReducedGuard_D_Stat 3 "NotUsed" 2 "Alarm_On" 1 "Alarm_Off_Previously_On" 0 "Alarm_Off" ;
VAL_TABLE_ HvacPrecondBlwr_D_Rq 15 "NotUsed6" 14 "NotUsed5" 13 "NotUsed4" 12 "NotUsed3" 11 "NotUsed2" 10 "NotUsed1" 9 "Last_User_Setting" 8 "Auto" 7 "Speed7" 6 "Speed6" 5 "Speed5" 4 "Speed4" 3 "Speed3" 2 "Speed2" 1 "Speed1" 0 "Off" ;
VAL_TABLE_ HvacPrecondMode_D_Rq 15 "NotUsed4" 14 "NotUsed3" 13 "NotUsed2" 12 "NotUsed1" 11 "Last_User_Settings" 10 "Auto" 9 "Max_Defrost" 8 "Windshield_Panel_Floor" 7 "Windshield_Panel" 6 "Windshield" 5 "Windshield_Floor" 4 "Floor" 3 "Panel_Floor" 2 "Panel" 1 "MAX_AC" 0 "Off" ;
VAL_TABLE_ ButtonNotPressed 1 "Button_Pressed" 0 "Button_Not_Pressed" ;
VAL_TABLE_ Null_Pressed 1 "Pressed" 0 "Null" ;
VAL_TABLE_ FobComm_D_Stat 3 "NotUsed" 2 "RemEngStartOK" 1 "RemEngStartFail" 0 "Null" ;
VAL_TABLE_ PudLamp_D_Rq 3 "RAMP_DOWN" 2 "RAMP_UP" 1 "ON" 0 "OFF" ;
VAL_TABLE_ WndwGlbl_D_Cmd 7 "NotUsed3" 6 "NotUsed2" 5 "NotUsed1" 4 "GLEARN" 3 "GCLOSE" 2 "GOPEN" 1 "GSTOP" 0 "Null" ;
VAL_TABLE_ LockMsg 7 "MSG7" 6 "MSG6" 5 "MSG5" 4 "MSG4" 3 "MSG3" 2 "MSG2" 1 "MSG1" 0 "NO_WARNING" ;
VAL_TABLE_ ChildLockDisplay 3 "NOT_SUPPORTED" 2 "ERROR" 1 "CHILD_UNLOCK" 0 "CHILD_LOCK" ;
VAL_TABLE_ Null_Lock_Unlock 3 "NotUsed" 2 "Unlock" 1 "Lock" 0 "Null" ;
VAL_TABLE_ Wiper 15 "NO_DATA_EXISTS" 14 "STALLED" 13 "RESERVED" 12 "AUTO_ADJUST" 11 "COURTESYWIPE" 10 "AUTO_HIGH" 9 "AUTO_LOW" 8 "WASH" 7 "MIST_FLICK" 6 "MAN_HIGH" 5 "MAN_LOW" 4 "MAN_INT_ON" 3 "MAN_INT_OFF" 2 "OFF_MOVING" 1 "AUTO_OFF" 0 "OFF" ;
VAL_TABLE_ Turn_switch 3 "Unused_Treat_As_Off" 2 "Right" 1 "Left" 0 "Off" ;
VAL_TABLE_ PrkLght_D_Stat 3 "Park_Both" 2 "Park_Right" 1 "Park_Left" 0 "Off" ;
VAL_TABLE_ LghtAmb_D_Sns 7 "No_Data_Exists" 6 "Unused2" 5 "Unused1" 4 "Tunnel_Off" 3 "Tunnel_On" 2 "Twilight" 1 "Light" 0 "Dark" ;
VAL_TABLE_ HeadLghtSwtch_D_Stat 3 "Autolamp" 2 "Headlamp" 1 "Parklamp" 0 "Off" ;
VAL_TABLE_ EmgcyBrkLamp_D_Rq 3 "NotUsed" 2 "Active_at_standstill" 1 "Active_at_speed" 0 "Inactive" ;
VAL_TABLE_ GearLvrPos_D_Unfilt 7 "Invalid" 6 "NotUsed" 5 "In_between" 4 "Low" 3 "Drive" 2 "Neutral" 1 "Reverse" 0 "Park" ;
VAL_TABLE_ EDrvTqMntrRconfg_D_Cmd 7 "OK" 6 "Disable_Cruise" 5 "NotUsed4" 4 "Supercreep" 3 "NotUsed3" 2 "NotUsed2" 1 "Engine_shutdown" 0 "NotUsed" ;
VAL_TABLE_ OpenPressedFault 3 "Fault" 2 "Unused" 1 "Pressed" 0 "Open" ;
VAL_TABLE_ LaHandsOff_D_Dsply 3 "Suppressed" 2 "Level2" 1 "Level1" 0 "HandsOn" ;
VAL_TABLE_ Avail_Unavail 1 "Unavailable" 0 "Available" ;
VAL_TABLE_ LaActvStats_D_Dsply 31 "Unused7" 30 "LA_Off" 29 "Unused5" 28 "Unused4" 27 "Unused3" 26 "Unused2" 25 "Unused1" 24 "InerveneLeft_InterveneRght" 23 "WarnLeft_InterveneRight" 22 "SuppressLeft_InterveneRght" 21 "AvailLeft_InterveneRhtt" 20 "NoLeft_InterveneRight" 19 "InterveneLeft_WarnRight" 18 "WarnLeft_WarnRight" 17 "SuppressLeft_WarnRight" 16 "AvailableLeft_WarnRight" 15 "NoLeft_WarnRight" 14 "InterveneLeft_SuppressRght" 13 "WarnLeft_SuppressRight" 12 "SuppressLeft_SuppressRight" 11 "AvailLeft_SuppressRight" 10 "NoLeft_SuppressRight" 9 "InterveneLeft_AvailRight" 8 "WarnLeft_AvailRight" 7 "SuppressLeft_AvailRight" 6 "AvailableLeft_AvailRight" 5 "NoLeft_AvailableRight" 4 "InterveneLeft_NoRight" 3 "WarnLeft_NoRight" 2 "SuppressLeft_NoRight" 1 "AvailableLeft_NoRight" 0 "NoLeft_NoRight" ;
VAL_TABLE_ GrllShtrPos_D_Cmd 15 "Fully_Open" 14 "Position14" 13 "Position13" 12 "Position12" 11 "Position11" 10 "Position10" 9 "Position9" 8 "Position8" 7 "Position7" 6 "Position6" 5 "Position5" 4 "Position4" 3 "Position3" 2 "Position2" 1 "Position1" 0 "Fully_Closed" ;
VAL_TABLE_ LifeCycMde_D_Actl 3 "Transport" 2 "NotUsed" 1 "Factory" 0 "Normal" ;
VAL_TABLE_ TrnMsgTxt_D_Rq 15 "Message_15" 14 "Message_14" 13 "Message_13" 12 "Message_12" 11 "Message_11" 10 "Message_10" 9 "Message_9" 8 "Message_8" 7 "Message_7" 6 "Message_6" 5 "Message_5" 4 "Message_4" 3 "Message_3" 2 "Message_2" 1 "Message_1" 0 "NoMessage" ;
VAL_TABLE_ DieslPrtcRgen_D_Rq 7 "Unused_2" 6 "Unused_1" 5 "Full_Regen_2" 4 "Full_Regen_1" 3 "HeatUp_3" 2 "HeatUp_2" 1 "HeatUp_1" 0 "Normal_Mode_NoRegen" ;
VAL_TABLE_ ClimtHeat_D_Rq 7 "NotUsed4" 6 "NotUsed3" 5 "HtrCoreClntFlwOnly" 4 "PtcHtrTestMde" 3 "Defrost_Defog" 2 "FastTempPullDownHeatingReq" 1 "OpportunisticHeatingReq" 0 "NoHeatingRequest" ;
VAL_TABLE_ TrnCapHlth_Actl 3 "Capacitor_OK" 2 "Degraded_Capacitor" 1 "Capacitor_State_Unknown" 0 "Capacitor_Fault" ;
VAL_TABLE_ TrnSecPrkStat_D_Actl 7 "Faulty" 6 "Fault_Released" 5 "Fault_Latched" 4 "Recouple_in_Progress" 3 "Mechanism_Released" 2 "RTP_in_Progress" 1 "Pending" 0 "Latched" ;
VAL_TABLE_ TrnGear_D_Actl 7 "Fault" 6 "NotUsed" 5 "Manual" 4 "Drive" 3 "Neutral" 2 "Reverse" 1 "Park" 0 "Transition_State" ;
VAL_TABLE_ TrnNtrlTowCmd_D_Actl 3 "NotUsed" 2 "Neutral_Tow_Entry" 1 "Car_Wash_Mode" 0 "Normal_Mode" ;
VAL_TABLE_ TrnValidGear_D_Cnfm 3 "Accept" 2 "Reject" 1 "Internal_Request" 0 "No_Command" ;
VAL_TABLE_ TrnGear_D_RqPt 7 "Fault" 6 "NotUsed" 5 "Manual" 4 "Drive" 3 "Neutral" 2 "Reverse" 1 "Park" 0 "No_Gear" ;
VAL_TABLE_ TrnValidGearRq_D_Stat 3 "Valid_Request" 2 "Valid_Degraded_Request" 1 "Invalid_Request" 0 "No_Request" ;
VAL_TABLE_ NoData_Fault_3FE_3FF 1023 "Fault" 1022 "NoDataExists" ;
VAL_TABLE_ ClimtCool_D_Rq 7 "NotUsed4" 6 "NotUsed3" 5 "NotUsed2" 4 "ElACTestMde" 3 "Defrost_Defog" 2 "FastTempPullDownCoolReq" 1 "OpportunisticCoolingReq" 0 "NoCoolingRequest" ;
VAL_TABLE_ HtrnHvilOpen_B_Actl 1 "HVIL_is_Open" 0 "Normal_Operation" ;
VAL_TABLE_ EngTeHi_B_Actl 1 "EngineTempHigh" 0 "Normal" ;
VAL_TABLE_ Eng_D_StatPwPck 7 "NotUsed3" 6 "NotUsed2" 5 "Engine_Start_Cold_Cat" 4 "Engine_Disabled" 3 "Engine_Running" 2 "Engine_Run_CSER" 1 "Engine_Start" 0 "Off" ;
VAL_TABLE_ EngFuelCutFull_B_Inhbt 1 "Inhibit_DFSO" 0 "Normal" ;
VAL_TABLE_ EngFuelCutFull_B_Rq 1 "FuelCutRequest" 0 "NormalOperation" ;
VAL_TABLE_ Fault_7FF 2047 "Fault" ;
VAL_TABLE_ EngStopFst_B_Rq 1 "FastEngineShutdown" 0 "NormalOperation" ;
VAL_TABLE_ EngStrtCold_B_Rq 1 "ExtremeColdStart" 0 "NormalStart" ;
VAL_TABLE_ EngStrtSmooth_D_Rq 7 "NotUsed" 6 "Smooth_NoPedal" 5 "Smooth_LightPedal" 4 "Smooth_MediumPedal" 3 "Smooth_HeavyPedal" 2 "Smooth_WOP" 1 "Smooth_Cold" 0 "Smooth_ExtremeCold" ;
VAL_TABLE_ Fault_FFF 4095 "Fault" ;
VAL_TABLE_ VehStrtStop_D_Rq 3 "NotUsed" 2 "Vehicle_Start_Request" 1 "Vehicle_Stop_Request" 0 "NoRequest" ;
VAL_TABLE_ HvacRec_D_RqMxBatt 15 "NotUsed5" 14 "NotUsed4" 13 "NotUsed3" 12 "NotUsed2" 11 "NotUsed1" 10 "No_Override" 9 "90Percent_RecircMax" 8 "80Percent_RecircMax" 7 "70Percent_RecircMax" 6 "60Percent_RecircMax" 5 "50Percent_RecircMax" 4 "40Percent_RecircMax" 3 "30Percent_RecircMax" 2 "20Percent_RecircMax" 1 "10Percent_RecircMax" 0 "0Percent_RecircFullOpen" ;
VAL_TABLE_ FuelCtlOpenLp_B_Inhbt 1 " Inhibit_FullPedal_Actions" 0 "Normal_Operation" ;
VAL_TABLE_ EngStrtStop_B_SrcSrvc 1 "Eng_StartStop_for_Service" 0 "Not_Requested" ;
VAL_TABLE_ EngStrtStop_B_SrcCat 1 "Eng_StartStop_for_Catalyst" 0 "Not_Requested" ;
VAL_TABLE_ PrkBrkStatus 7 "GeneralFault_MaintenceMode" 6 "ECD_by_Brake_ECU_Active" 5 "EPB_Limphome_Active" 4 "Rear_Caliper_Open" 3 "RWU_By_EPB_Active" 2 "Rear_Caliper_Transition" 1 "Rear_Caliper_Closed" 0 "Not_Supported" ;
VAL_TABLE_ ElLoadCtl_D_Rq 7 "Unused3" 6 "Unused2" 5 "Unused1" 4 "HoldAllDrvrInvisibleLoads" 3 "StdDriverInvisibleLoadsOn" 2 "AllDriverInvisibleLoadsOn" 1 "All_Possible_Loads_Off" 0 "No_Request" ;
VAL_TABLE_ BattTracCool 3 "NotUsed" 2 "DCDC_Overtemperature" 1 "CoolingRequiredbyDCDC" 0 "NoCoolingRequiredbyDCDC" ;
VAL_TABLE_ NotReady_Active_Fault 3 "Fault" 2 "Active" 1 "Ready" 0 "Not_Ready" ;
VAL_TABLE_ Quality_Data 3 "OK" 2 "Not_Within_Specifications" 1 "Eval_In_Progress" 0 "Fault" ;
VAL_TABLE_ PwSrcULoFalt_D_Stat 3 "Fault_No_Output" 2 "Fault_Reduced_Output" 1 "Fault_NonSpecific" 0 "No_Fault" ;
VAL_TABLE_ Connect_Discon_Loose 1 "Loose_or_Disconnected" 0 "Connected" ;
VAL_TABLE_ DontCare_StartInhibit 1 "Start_Inhibit" 0 "Dont_Care" ;
VAL_TABLE_ BattULoChrg_D_Rq 3 "Low_Battery_Temperature" 2 "Charging_Requested" 1 "Chrg_Requested_HighCurrent" 0 "No_Request" ;
VAL_TABLE_ PwSysULoFalt_D_Stat 15 "Not_Used_6" 14 "LowBatterySOC" 13 "PSS_Shed2_Contin" 12 "Not_Used_4" 11 "Not_Used_3" 10 "Not_Used_2" 9 "BattMonitoringSensorFault" 8 "LowBattVoltDuringPwSrcOn" 7 "LowBatt2_PowerSaveMode" 6 "LowBatt1_Warning" 5 "Overvoltage" 4 "Fault_NoOutput" 3 "Fault_ReducedOutput" 2 "Fault_Nonspecific" 1 "Cluster_Proveout" 0 "No_Fault" ;
VAL_TABLE_ AccStopMde_D_Rq 3 "Stop_Mode_Active" 2 "EPBApplyOrBrakeReleaseWarn" 1 "Limit_Rolling_Speed" 0 "Stop_Mode_Not_Active" ;
VAL_TABLE_ EngFuelCutFull_B_Sched 1 "DFSO_Event_Scheduled" 0 "Normal" ;
VAL_TABLE_ Eng_D_Stat 3 "NotUsed" 2 "EngAutoStopped" 1 "EngOn" 0 "EngOff" ;
VAL_TABLE_ ElPw_D_Stat 7 "NotUsed_3" 6 "NotUsed_2" 5 "NotUsed_1" 4 "Fault_Limited" 3 "LV_Event_In_Progress" 2 "Not_Supported_Imminent" 1 "Supported" 0 "Not_Supported" ;
VAL_TABLE_ PwPckTq_D_Stat 3 "PwPckOn_TqAvailable" 2 "StartInPrgrss_TqNotAvail" 1 "PwPckOn_TqNotAvailable" 0 "PwPckOff_TqNotAvailable" ;
VAL_TABLE_ BattTracCool_D_Falt 3 "NotUsed" 2 "CoolSysPartialyOperational" 1 "Cooling_System_Faulted" 0 "Cooling_System_Operational" ;
VAL_TABLE_ Fault_FF 255 "Fault" ;
VAL_TABLE_ ElCmprOverTe_D_Stat 3 "OverTempStop" 2 "OverTempWarning" 1 "Normal" 0 "Undefined" ;
VAL_TABLE_ ElCmprUHi_D_Stat 3 "Overvoltage" 2 "Undervoltage" 1 "InRange" 0 "Undetermined" ;
VAL_TABLE_ ElCmpr_D_Stat 7 "Signal_Invalid" 6 "Comp_Off_ActlSpd_Abnormal" 5 "Comp_Off_TrgtSpd_OutRange" 4 "Comp_Shutdown" 3 "Comp_Stopped_Self_Protect" 2 "Comp_Degraded" 1 "Comp_On" 0 "Comp_Off" ;
VAL_TABLE_ Southern_Northern 3 "Fault" 2 "Northern" 1 "Southern" 0 "Invalid" ;
VAL_TABLE_ PsngrFrntDetct_D_Actl 3 "Unknown" 2 "Empty" 0 "Faulty" 1 "Occupied" ;
VAL_TABLE_ Normal_Mode1_2 3 "Undefined" 2 "Mode2" 1 "Mode1" 0 "Normal_Mode" ;
VAL_TABLE_ LaActvAvail 3 "LKA_LCA_LDW_Avail" 2 "LCA_LKA_Avail_LDW_Suppress" 1 "LCA_LKA_Suppress_LDW_Avail" 0 "LCA_LKA_LDW_Suppress" ;
VAL_TABLE_ LA_NotDenied 1 "LA_Denied" 0 "LA_Not_Denied" ;
VAL_TABLE_ HandsOn_Off 1 "Hands_Off" 0 "Hands_On" ;
VAL_TABLE_ Smooth_Quick 1 "Quick" 0 "Smooth" ;
VAL_TABLE_ None_Low_Med_High 3 "High" 2 "Medium" 1 "Low" 0 "None" ;
VAL_TABLE_ LdwActvStats 7 "LDW_Suppress_Right_Left" 6 "Not_Used2" 5 "LDW_Suppress_Right" 4 "LDW_Warning_Right" 3 "LDW_Suppress_Left" 2 "LDW_Warning_Left" 1 "LDW_DemoVibration" 0 "LDW_Idle" ;
VAL_TABLE_ Fault_3FF 1023 "Fault" ;
VAL_TABLE_ Fault_F 15 "Fault" ;
VAL_TABLE_ Fault_1F 31 "Fault" ;
VAL_TABLE_ TmsStatRqDsply 15 "Reserved4" 14 "Reserved3" 13 "Reserved2" 12 "Crawl_Mode_4LOW_Reqd" 11 "Economy_Mode_Select" 10 "ModeChangeNotAvailable" 9 "Terrain_Sys_Not_Avail" 8 "Terrain_System_Fault" 7 "Mode_Change_InProgress" 6 "Dynamics_Mode_Select" 5 "Rock_Crawl_Mode_Select" 4 "Sand_Mode_Select" 3 "Mud_Ruts_Mode_Select" 2 "Low_Mu_Mode_Select" 1 "Special_Modes_Off" 0 "No_Message" ;
VAL_TABLE_ LockInhibit 1 "Inhibit" 0 "No_Inhibit" ;
VAL_TABLE_ DieslFuelBio_B_ActlDrv 1 "Biodiesel_User" 0 "Non_Biodiesel_User" ;
VAL_TABLE_ Invalid_FFF 4095 "Invalid" ;
VAL_TABLE_ ParkAid_Chime 15 "Zone15_Chime" 14 "Zone14_Chime" 13 "Zone13_Chime" 12 "Zone12_Chime" 11 "Zone11_Chime" 10 "Zone10_Chime" 9 "Zone9_Chime" 8 "Zone8_Chime" 7 "Zone7_Chime" 6 "Zone6_Chime" 5 "Zone5_Chime" 4 "Zone4_Chime" 3 "Zone3_Chime" 2 "Zone2_Chime" 1 "Zone1_Chime" 0 "No_Chime" ;
VAL_TABLE_ Shed_Feature_Group_ID 16 "PtcHeater" 30 "NotUsed_7" 29 "NotUsed_6" 28 "NotUsed_5" 27 "NotUsed_4" 26 "NotUsed_3" 25 "NotUsed_2" 24 "NotUsed_1" 23 "Dcac" 22 "UpFitter_6" 21 "UpFitter_5" 20 "UpFitter_4" 19 "UpFitter_3" 18 "UpFitter_2" 17 "UpFitter_1" 14 "HtdMirr" 13 "HvacRearBlwr_Third" 12 "HvacRearBlwr_Second" 11 "HvacRearBlwr_First" 31 "All LSHED1 Features" 10 "Htd_Windscrn" 9 "SpltHtdBcklight_HtdMirr" 8 "HtdBcklight_HtdMirr" 7 "HtdCoolSeat_FrtDriver" 6 "HtdCoolSeat_FrtPass" 5 "HtdCoolSeat_RearPass" 4 "HtdCoolSeat_RearDriver" 3 "SmartTrlrTowBattCharge" 2 "Htd_StrWhl" 1 "Htd_Washer_Fluid" 0 "No_LSHED1_Features" 15 "Engine_Coolant_Fan" ;
VAL_TABLE_ CoolantFanStepAct 31 "Unused7" 30 "Unused6" 29 "Unused5" 28 "Unused4" 27 "Unused3" 26 "Unused2" 25 "Unused1" 23 "Step23" 22 "Step22" 21 "Step21" 20 "Step20" 19 "Step19" 18 "Step18" 17 "Step17" 16 "Step16" 15 "Step15" 14 "Step14" 13 "Step13" 12 "Step12" 11 "Step11" 10 "Step10" 9 "Step9" 8 "Step8" 7 "Step7" 6 "Step6" 5 "Step5" 4 "Step4" 3 "Step3" 2 "Step2" 1 "Step1" 24 "Max_Fan_Speed_Req" 0 "Fan_Cmd_Off" ;
VAL_TABLE_ Null_Cancel 1 "Cancel" 0 "Null" ;
VAL_TABLE_ Veh_Lock_Requestor 31 "Unused8" 30 "Unused7" 29 "Unused6" 28 "Rgtm_Shutlock_Switch" 27 "Boundary_Alert" 26 "Transit_Vehicle_Relock" 25 "Transit_Cargo_Relock" 24 "Transit_Ajar_Lock" 23 "Diagnostics" 22 "Console_Lock" 21 "Child_Lock" 20 "Double_Lock" 19 "Passive_Pasenger" 18 "Passive_Driver" 17 "Slam_Lock_Protect" 16 "SYNC" 15 "Passport" 14 "Passive_Smart_Unlock" 13 "Autorelock" 12 "RemoteStart" 0 "Null" 1 "Autolock" 11 "Smart_Unlock" 10 "Sliding_Door" 9 "Passive" 8 "Remote" 7 "Programming" 6 "Powerslide" 5 "Keypad" 4 "Key_Cylinder" 3 "Interior" 2 "Auto_Unlock" ;
VAL_TABLE_ EPAS_FAILURE 3 "SERVICE_POWER_STEERING_NOW" 2 "SERVICE_POWER_STEERING" 1 "POWER_STRG_ASSIST_FAULT" 0 "EPAS_OK_NO_MESSAGE" ;
VAL_TABLE_ Perimeter_Alarm_Mode 3 "Activated" 2 "Armed" 1 "Prearmed" 0 "Disarmed" ;
VAL_TABLE_ Invalid_FFFF 65535 "Invalid" ;
VAL_TABLE_ OilPressureWarning 1 "Low_Pressure_Lamp_On" 0 "Normal_Pressure_Lamp_Off" ;
VAL_TABLE_ MyKey_KeyTypeChangeReq 3 "Search_PE_BackupSlot" 2 "Clear_All_MyKeys" 1 "Request_New_MyKey" 0 "None" ;
VAL_TABLE_ MyKey_Key_Count 13 "Thirteen" 12 "Twelve" 11 "Eleven" 10 "Ten" 9 "Nine" 8 "Eight" 7 "Seven" 6 "Six" 5 "Five" 4 "Four" 3 "Three" 2 "Two" 1 "One" 0 "Zero" 15 "Invalid" 14 "Unlimited" ;
VAL_TABLE_ GearEngag_D_Actl 7 "Undefined" 6 "Fwd_Clutch_Fully_Engaged" 5 "Neutral_Idle" 4 "Disengaged_to_Neutral_Idle" 3 "Disengaged_to_Neutral_Park" 2 "Engagement_in_Progress" 1 "InitializeFwdClutchEngagmt" 0 "Park_Neutral" ;
VAL_TABLE_ Shed_Level_Req 7 "SHED3" 6 "Loads_On" 5 "SHED_ENG_OFF" 4 "SOON_ENG_OFF" 3 "SHED2_CONTIN" 2 "SHED2_TRANS" 1 "SHED1" 0 "NO_SHED" ;
VAL_TABLE_ BpedMove_D_Actl 3 "Unknown" 2 "DriverApplyingBrakePedal" 1 "NoAutonomousBrkPdlMovement" 0 "AutonomousBrkPedalMove" ;
VAL_TABLE_ Eastern_Western 0 "Invalid" 1 "Eastern" 2 "Western" 3 "Fault" ;
VAL_TABLE_ EATC_Temp_Digit3 2 "_5" 1 "_0" 0 "OFF" ;
VAL_TABLE_ EATC_Units 2 "Fahrenheit" 1 "Celsius" 0 "Off" ;
VAL_TABLE_ BattTracOffFst_D_Actl 3 "Unexpected_Contactor_Open" 2 "Restraints_Impact_Event" 1 "Interlock_Open" 0 "Normal" ;
VAL_TABLE_ Invalid_1FF 511 "Invalid" ;
VAL_TABLE_ ChargeMode 7 "Undefined_2" 6 "Undefined_1" 5 "Battery_Identify" 4 "Battery_Refresh" 3 "SlowRegenAllowNoDischarge" 2 "Fast_Regen_Allowed" 1 "Slow_Regen_Allowed" 0 "Conventional_Charging" ;
VAL_TABLE_ Unknown_FFFE_Invalid_FFFF 65535 "Invalid" 65534 "Unknown" ;
VAL_TABLE_ SAPPAngleControlStat5 1 "StrgColTorqueExceed_EAROn" 0 "ExternalSigContentOKforEAC" ;
VAL_TABLE_ Closed_Open_Active_Fault 3 "Fault" 2 "Active" 1 "Open" 0 "Closed" ;
VAL_TABLE_ SAPPAngleControlStat2 1 "Rel_ExtSteeringAngleReqx" 0 "NoRel_ExtSteeringAngleReqx" ;
VAL_TABLE_ SAPPAngleControlStat3 1 "EARactiveNoReverseEngage" 0 "ExternalSigContentOKforEAC" ;
VAL_TABLE_ RstrnImpactEvntStatus 7 "Invalid" 6 "Not_Used_4" 5 "Threshold_2_Exceeded" 4 "Not_Used_3" 3 "Threshold_1_Exceeded" 2 "Not_Used_2" 1 "Not_Used_1" 0 "Normal" ;
VAL_TABLE_ EDRTriggerEvntSync 1 "Threshold_Exceeded" 0 "Normal" ;
VAL_TABLE_ EngTeColdPrtct_D_Stats 3 "Engine_Warm_RdcPwr" 2 "OK_to_Drive" 1 "Engine_Warm_PlsWait" 0 "Normal_Operation" ;
VAL_TABLE_ HILL_DESC_MC 7 "Fault_Detected" 6 "Cooling_Down" 5 "Abort_Apply_Brakes" 4 "Active" 3 "Disabled" 2 "Enabled" 1 "Off_Road" 0 "Normal" ;
VAL_TABLE_ Closed_Ajar 1 "Ajar" 0 "Closed" ;
VAL_TABLE_ CADS_Autio_Mute 7 "Unknown" 6 "Attenuation_6" 5 "Attenuation_5" 4 "Attenuation_4" 3 "Attenuation_3" 2 "Attenuation_2" 1 "Attenuation_1" 0 "No_Attenuation_of_Audio" ;
VAL_TABLE_ Quality_Factor 3 "OK" 2 "Not_Within_Specifications" 1 "No_Data_Exists" 0 "Faulty" ;
VAL_TABLE_ Null_Day_Night 3 "NotUsed" 2 "Night" 1 "Day" 0 "Null" ;
VAL_TABLE_ Null_Flash_High 3 "NotUsed" 2 "High" 1 "Flash_to_Pass" 0 "Null" ;
VAL_TABLE_ GearPos_D_Actl 15 "Unknown" 14 "Reverse" 13 "Undefined_5" 12 "Undefined_4" 11 "Undefined_3" 10 "Tenth" 9 "Ninth" 8 "Eighth" 7 "Seventh" 6 "Sixth" 5 "Fifth" 4 "Fourth" 3 "Third" 2 "Second" 1 "First" 0 "Neutral" ;
VAL_TABLE_ OffOn_SlowFast_Flash 3 "Fast_Flash" 2 "Slow_Flash" 1 "On" 0 "Off" ;
VAL_TABLE_ AwdStat_D_RqDsply 31 "Rear_Diff_Lock_Not_Avail" 30 "_4wd_Lock_Required" 29 "Cfg_Perf_Redc_See_Manual" 28 "To_Engage_4x4_Release_Aped" 27 "To_Engage_4x4_Slow_To_3MPH" 26 "Shift_To_Neutral" 25 "Lkr_Mode_Unavail_TMS" 24 " _4x4_Mode_Unavail_TMS" 23 "Out_of_4Low_Crawl" 22 "AWD_PTU_Oil_Changed" 21 "Change_AWD_PTU_Oil" 20 "Neutral_Tow_Disabled" 19 "Neutral_Tow_Enabled" 18 "AWD_OFF" 17 "_4x4_Off_Road_Speed" 16 "_4x4_Extreme_Off_Road_Mode" 15 "_4x4_Exiting_Off_Road" 14 "_4x4_Off_Road_Mode" 10 "_4x4_Locked_Temporarily" 9 "Shift_In_Progress" 13 "Blocked_Shift_Assist" 12 "_4x4_Auto_Restored" 11 "_4x4_Disabled_Temporarily" 7 "Out_of_4Low__Neutral" 6 "Out_of_4Low__Brake" 5 "Out_of_4Low__Speed" 4 "Into_4Low__Clutch" 3 "Into_4Low__Neutral" 2 "Into_4Low__Brake" 1 "Into_4Low__Speed" 0 "Normal__No_Message" 8 "Out_of_4Low__Clutch" ;
VAL_TABLE_ AngleReached 1 "RequestedAngleNotReached" 0 "RequestedAngleCanBeReached" ;
VAL_TABLE_ WhlDir 3 "Faulty" 2 "NoDataExists" 1 "Backward" 0 "Forward" ;
VAL_TABLE_ VehVLimStat_D_Actl 7 "Undefined_3" 6 "Undefined_2" 5 "Undefined_1" 4 "ASL_Fault_Condition" 3 "Active_and_Limiting" 2 "Active_but_Not_Limiting" 1 "Standby" 0 "Off" ;
VAL_TABLE_ Unknown_Fault_1FE_1FF 511 "Fault" 510 "Unknown" ;
VAL_TABLE_ Fault_NoFault 1 "Fault" 0 "No_Fault" ;
VAL_TABLE_ TrnIpcDsplyMde_D_Actl 7 "Manual_3" 6 "Manual_2" 5 "Manual_1_Low" 4 "Sport" 3 "Drive" 2 "Neutral" 1 "Reverse" 0 "Park" ;
VAL_TABLE_ TrnIpcDsplyMde_D_Stat 3 "Reserved_Blank_No_Display" 2 "Flash" 1 "On" 0 "Blank_No_Display" ;
VAL_TABLE_ TrnIpcDsplyGear_D_Actl 15 "No_Gear_Selected" 14 "_14th_Gear" 13 "_13th_Gear" 12 "_12th_Gear" 11 "_11th_Gear" 10 "_10th_Gear" 9 "_9th_Gear" 8 "_8th_Gear" 7 "_7th_Gear" 6 "_6th_Gear" 5 "_5th_Gear" 4 "_4th_Gear" 3 "_3rd_Gear" 2 "_2nd_Gear" 1 "_1st_Gear" 0 "Neutral" ;
VAL_TABLE_ TerrMde_D_Actl 7 "Fail_Safe_Default" 6 "Dynamic_Mode" 5 "Rock_Crawl_Mode" 4 "Mud_Ruts_Mode" 3 "Sand_Mode" 2 "Undefined" 1 "Low_Mu_Mode" 0 "Special_Operating_Mode_Off" ;
VAL_TABLE_ TerrMdeChng_D_Rdy 7 "Fault" 6 "Undefined_2" 5 "Undefined_1" 4 "ModeUnavailDrInputRqd" 3 "SpOpModes_NotSupported" 2 "ModeUnavailDynamicCond" 1 "Module_In_Initialization" 0 "Mode_Change_Available" ;
VAL_TABLE_ Unknown_Fault_FFFE_FFFF 65535 "Fault" 65534 "Unknown" ;
VAL_TABLE_ Invalid_FFFFFF 16777215 "Invalid" ;
VAL_TABLE_ AutoParkSpdExitCond 1 "SpeedLimitExceededEAROn" 0 "ExternalSigContentOKforEAC" ;
VAL_TABLE_ EngOilLvlDsply_D_Rq 15 "EngOil_LevelSys_CheckFault" 14 "Reserved_2" 13 "Reserved_1" 12 "Conditions_Unsuitable" 11 "Dipstick_Below_Minimum" 10 "Dipstick_Above_Maximum" 9 "Dipstick_Minimum" 8 "Dipstick_12_5_MinMaxRange" 7 "Dipstick_25_MinMaxRange" 6 "Dipstick_37_5_MinMaxRange" 5 "Dipstick_50_MinMaxRange" 4 "Dipstick_62_5_MinMaxRange" 3 "Dipstick_75_MinMaxRange" 2 "Dipstick_87_5_MinMaxRange" 1 "Dipstick_Maximum_Displayed" 0 "No_Message" ;
VAL_TABLE_ HdcMde_D_Actl 7 "Fault" 6 "Temporarily_Unavailable" 5 "NotEnabled_WrongGearSel" 4 "NotEnabled_SpdLimitExceed" 3 "Active_Braking" 2 "Not_Active_Braking" 1 "Off" 0 "Undefined" ;
VAL_TABLE_ GearLvrPos_D_Actl 15 "Fault" 14 "Unknown_Position" 13 "Undefined_Treat_as__Fault" 12 "Undefined_Treat_as_Fault" 11 "sixth" 10 "fifth" 9 "fourth" 8 "third" 7 "second" 6 "first" 5 "Low" 4 "Sport_DriveSport" 3 "Drive" 2 "Neutral" 1 "Reverse" 0 "Park" ;
VAL_TABLE_ FcwMsgTxt_D_Rq 7 "Undefined_3" 6 "Undefined_2" 5 "Low_Visibility" 4 "Unavailable_DueTo_LowSpeed" 3 "Available" 2 "Unavailable" 1 "Off" 0 "No_Text" ;
VAL_TABLE_ FcwSens_B_Actl 3 "FCW_Sensitivity_3" 2 "FCW_Sensitivity_2" 1 "FCW_Sensitivity_1" 0 "Not_Used" ;
VAL_TABLE_ EngTurboMde_D_Actl 3 "Fault" 2 "One_Turbo_Active" 1 "Two_Turbos_Active" 0 "Initializing" ;
VAL_TABLE_ EngPullUpPullDown 15 "Undefined_7" 14 "Undefined_6" 13 "Undefined_5" 12 "Undefined_4" 8 "Force_Pull_Down" 7 "Force_Pull_Up" 6 "PullDown_Inhibit_PullUp" 5 "Inhibit_Change" 4 "Inhibit_Pull_Up" 3 "Pull_Down" 2 "Inhibit_Pull_Down" 1 "Pull_Up" 0 "No_Request" 11 "Undefined_3" 10 "Undefined_2" 9 "Undefined_1" ;
VAL_TABLE_ EngMde_D_Rq 8 "VSC_Sets_Speed_Type_3" 7 "VSC_Sets_Speed_Type_2" 6 "VSC_Sets_Torque_Type_2" 5 "Dependability_Shutdown" 4 "Dependability_Follow" 3 "Start" 2 "VSC_Sets_Torque_Type_1" 1 "VSC_Sets_Speed_Type_1" 0 "Off" 15 "Undefined_7" 14 "Undefined_6" 13 "Undefined_5" 12 "Undefined_4" 11 "Undefined_3" 10 "Undefined_2" 9 "Undefined_1" ;
VAL_TABLE_ DrvHdcMsg_D_Rq 7 "Undefined" 6 "Speed_too_High" 5 "Temporarily_Unavailable" 4 "System_Fault" 3 "Select_Gear" 2 "Off" 1 "On" 0 "No_Message" ;
VAL_TABLE_ CmbbBrkPrchg_B_Rq 3 "Undefined" 2 "Level_2_PreCharge_Request" 1 "Level_1_PreCharge_Request" 0 "No_PreCharge_Request" ;
VAL_TABLE_ CmbbBaSens_D_Rq 3 "Level_3" 2 "Level_2" 1 "Level_1" 0 "Normal" ;
VAL_TABLE_ CcStat_D_Actl 7 "Undefined_2" 6 "Undefined_1" 5 "Active" 4 "Active_Que_Assist" 3 "Standby" 2 "Standby_Denied" 1 "Denied" 0 "Off" ;
VAL_TABLE_ BpedDrvAppl_D_Actl 3 "_Not_Allowed" 2 "Driver_Braking" 1 "Driver_Not_Braking" 0 "Not_Allowed" ;
VAL_TABLE_ AslIconDsply_D_Rq 3 "On_Passive_Overridden" 2 "On_Active" 1 "On_Passive" 0 "Off" ;
VAL_TABLE_ Unknown_Fault_3E_3F 63 "Fault" 62 "Unknown" ;
VAL_TABLE_ AccWarn_D_Dsply 3 "BrakeReleaseWarn_In_StopMd" 2 "Brake_Capacity_Warning" 1 "Cancel_Warning" 0 "No_Warning" ;
VAL_TABLE_ AccTrgDist2_D_Dsply 15 "DIST_ACTIVE_13_Farthest" 14 "DIST_ACTIVE_12" 13 "DIST_ACTIVE_11" 12 "DIST_ACTIVE_10" 11 "DIST_ACTIVE_9" 10 "DIST_ACTIVE_8" 9 "DIST_ACTIVE_7" 8 "DIST_ACTIVE_6" 7 "DIST_ACTIVE_5" 6 "DIST_ACTIVE_4" 5 "DIST_ACTIVE_3" 4 "DIST_ACTIVE_2" 3 "DIST_ACTIVE_1_Closest" 2 "DIST_ACTIVE_No_Target" 1 "DIST_STANDBY" 0 "DIST_OFF" ;
VAL_TABLE_ AccTGap_D_Dsply 7 "Undefined_2" 6 "Undefined_1" 5 "Time_Gap_5" 4 "Time_Gap_4" 3 "Time_Gap_3" 2 "Time_Gap_2" 1 "Time_Gap_1" 0 "Not_Used" ;
VAL_TABLE_ AccEngStat_D_Actl 7 "Undefined_2" 6 "Undefined_1" 5 "ACCSoonCancel_due_Low_Spd" 4 "Shift_Down_Recommendation" 3 "Shift_Up_Recommendation" 2 "ACCNotAllowedToBeActivated" 1 "ACCStandby_due_Auto_Cancel" 0 "Normal_Operation" ;
VAL_TABLE_ NotPressed_Pressed 1 "Pressed" 0 "Not_Pressed" ;
VAL_TABLE_ TrnGear_D_RqDrv 31 "Fault" 30 "NotUsed_25" 29 "NotUsed_24" 28 "NotUsed_23" 27 "NotUsed_22" 26 "Return_to_Park" 25 "NotUsed_20" 24 "NotUsed_19" 23 "NotUsed_18" 22 "NotUsed_17" 21 "Return_To_Park" 20 "NotUsed_15" 19 "NotUsed_14" 18 "NotUsed_13" 17 "NotUsed_12" 16 "Manual" 15 "Not_Used11" 14 "Not_Used10" 13 "NotUsed_9" 12 "NotUsed_8" 11 "NotUsed_7" 10 "NotUsed_6" 9 "NotUsed_5" 8 "Drive" 7 "NotUsed_4" 6 "NotUsed_3" 5 "NotUsed_2" 4 "Neutral" 3 "NotUsed_1" 2 "Reverse" 1 "Park" 0 "No_Gear" ;
VAL_TABLE_ Open_Close 1 "Close" 0 "Open" ;
VAL_TABLE_ OpenCloseRetainUndef 3 "Undefined" 2 "Retain" 1 "Close" 0 "Open" ;
VAL_TABLE_ DasWarn 3 "Undefined" 2 "Warning_Level_2" 1 "Warning_Level_1" 0 "No_Warning" ;
VAL_TABLE_ DasAlert 5 "Alertness_Level_5" 4 "Alertness_Level_4" 3 "Alertness_Level_3" 2 "Alertness_Level_2" 1 "Alertness_Level_1" 0 "Undefined" ;
VAL_TABLE_ DasStat 3 "Available" 2 "Unavailable_Other" 1 "Feedback_due_to_Speed" 0 "Off" ;
VAL_TABLE_ No_Crank_Req 1 "Crank_Request" 0 "No_Crank_Request" ;
VAL_TABLE_ DrvSlipCtlMde_D_Rq 3 "App_Specific_Off_Mode_3" 2 "App_Specific_Off_Mode_2" 1 "App_Specific_Off_Mode_1" 0 "Default_Mode" ;
VAL_TABLE_ AwdOffRoadMode 3 "Invalid" 2 "Extreme_Off_Road" 1 "Off_Road" 0 "Normal_Mode" ;
VAL_TABLE_ NotQuiet_Quiet 1 "Quiet" 0 "Not_Quiet" ;
VAL_TABLE_ Normal_AdaptiveCruise 1 "Adaptive_Cruise" 0 "Normal_Cruise" ;
VAL_TABLE_ Remote_Device_Feedback 7 "Unused3" 6 "Unused2" 5 "Unused1" 4 "Shutdown" 3 "Running" 2 "Starting" 1 "Acknowledge" 0 "Null" ;
VAL_TABLE_ TrnManShif_D_IndDrv 7 "Undefined_3" 6 "Undefined_2" 5 "Shift_to_Neutral" 4 "Downshift_Recommendation" 3 "Upshift_Warning" 2 "Upshift_Performance" 1 "Upshift_Fuel_Economy" 0 "No_Indication" ;
VAL_TABLE_ Unlock_Lock 1 "Locked" 0 "Unlock" ;
VAL_TABLE_ DieslPrtc_D_RqDsply 7 "Unused_2" 6 "Unused_1" 5 "DPF_SOOT_Level3_Blocked" 4 "DPFSootLvl2_SevereOverload" 3 "DPFRegen_ExhFilterComplete" 2 "DPFRegen_CleanExhFilter" 1 "DPF_Soot_Level1_Overloaded" 0 "DPF_OK_Normal_Operation" ;
VAL_TABLE_ PE_BackupSlot_Status 3 "No_Valid_FOB_In_Slot" 2 "MyKey_FOB_In_Slot" 1 "Standard_FOB_In_Slot" 0 "Null" ;
VAL_TABLE_ Unknown_Fault_FFE_FFF 4095 "Fault" 4094 "Unknown" ;
VAL_TABLE_ Unknown_Fault_1FFE_1FFF 8191 "Fault" 8190 "Unknown" ;
VAL_TABLE_ TrnCnvtClu_D_Actl 3 "Transition_or_Micro_Slip" 2 "Lock_Up_Fixed" 1 "Lock_Up_Slip" 0 "No_Lock_Up" ;
VAL_TABLE_ InhibitNoinhibit 1 "Inhibit" 0 "No_Inibit" ;
VAL_TABLE_ DisableEnable 1 "Enable" 0 "Disable" ;
VAL_TABLE_ Unknown_Fault_7FFE_7FFF 32767 "Fault" 32766 "Unknown" ;
VAL_TABLE_ Side_Detect_Sn_State 3 "Second_Warning_Audio" 2 "System_Failure" 1 "Blocked" 0 "Clear" ;
VAL_TABLE_ Litval_values 255 "Invalid" 254 "Unknown" 5 "Day" 4 "Twilight_4" 3 "Twilight_3" 2 "Twilight_2" 1 "Twilight_1" 0 "Night" ;
VAL_TABLE_ Dimming_Lvl 255 "Invalid" 254 "Unknown" 18 "Day_6" 17 "Day_5" 16 "Day_4" 15 "Day_3" 14 "Day_2" 13 "Day_1" 12 "Night_12" 11 "Night_11" 10 "Night_10" 9 "Night_9" 8 "Night_8" 7 "Night_7" 6 "Night_6" 5 "Night_5" 4 "Night_4" 3 "Night_3" 2 "Night_2" 1 "Night_1" 0 "Off" ;
VAL_TABLE_ EngStrtStop_B_SrcChtLo 1 "Eng_StartStop_for_CHT_Low" 0 "Not_Requested" ;
VAL_TABLE_ EngStrtStop_B_SrcChtHi 1 "Eng_StartStop_for_CHT_Hi" 0 "Not_Requested" ;
VAL_TABLE_ EngDiag_D_RqHtrn 7 "NotUsed4" 6 "NotUsed3" 5 "NotUsed2" 4 "NoUsed1" 3 "Eng_Diag_Cstdn" 2 "Eng_Diag_Run" 1 "Eng_Diag_Crank" 0 "Eng_Diag_Normal" ;
VAL_TABLE_ NotOperating 1 "Operating" 0 "Not_Operating" ;
VAL_TABLE_ CamraStat 3 "FrtCam_TempUnavailOther" 2 "FrtCam_TempUnavailVisibile" 1 "Front_Camera_Service_Reqd" 0 "Front_Camera_OK" ;
VAL_TABLE_ EngPtoMde_D_Actl 7 "Undefined" 6 "Split_Shaft_Stationary" 5 "Not_Used_2" 4 "PTO_Mobile" 3 "Not_Used_1" 2 "PTO_Stationary" 1 "BCP" 0 "Off" ;
VAL_TABLE_ ManRgen_D_Rq 3 "NotUsed2" 2 "NotUsed1" 1 "CustInitManExhFilterClean" 0 "No_Customer_Request" ;
VAL_TABLE_ Remote_Start_Status 3 "Invalid" 2 "Unknown" 1 "Remote" 0 "Null" ;
VAL_TABLE_ Enabled_Active_Disabled 3 "Unused" 2 "Disabled" 1 "Active" 0 "Enabled_Inactive" ;
VAL_TABLE_ Lock_Subld 15 "Unused7" 14 "Unused6" 13 "Unused5" 12 "Unused4" 11 "Unused3" 10 "Unused2" 9 "Unused1" 8 "Customer_8" 7 "Customer_7" 6 "Customer_6" 5 "Customer_5" 4 "Customer_4" 3 "Customer_3" 2 "Customer_2" 1 "Customer_1" 0 "Null" ;
VAL_TABLE_ Brake_Fluid 3 "Invalid" 2 "Unknown" 1 "Low" 0 "OK" ;
VAL_TABLE_ Unknown_Invalid_FE_FF 255 "Invalid" 254 "Unknown" ;
VAL_TABLE_ Invalid_FF 255 "Invalid" ;
VAL_TABLE_ NotLow_Low 1 "Low" 0 "Not_Low" ;
VAL_TABLE_ Disabled_Enabled_Status 2 "Status" 3 "NotUsed" 1 "Enabled" 0 "Disabled" ;
VAL_TABLE_ Key_In_Ignition_Status 1 "In" 0 "Out" ;
VAL_TABLE_ Ignition_Status 0 "Unknown" 1 "Off" 15 "Invalid" 8 "Start" 4 "Run" 2 "Accessory" ;
VAL_TABLE_ Disabled_Enabled_Faulted 3 "Faulted" 2 "Unused" 1 "Enabled" 0 "Disabled" ;
VAL_TABLE_ Disabled_Enabled_NoSupport 2 "Unused" 3 "Not_Supported" 1 "Enabled" 0 "Disabled" ;
VAL_TABLE_ Unknown_Fault_FE_FF 255 "Fault" 254 "Unknown" ;
VAL_TABLE_ Null_Unlock 1 "Unlock" 0 "Null" ;
VAL_TABLE_ Null_Active 1 "Active" 0 "Null" ;
VAL_TABLE_ HsaStat_D_Actl 7 "Faulty" 6 "FaultyWithDriverIndication" 5 "SlowRelease" 4 "FastRelease" 3 "ActiveBrakePedalReleased" 2 "ActiveBrakePedalPressed" 1 "FindingGradient" 0 "Inactive" ;
VAL_TABLE_ Off_Auto_Manual 3 "Undefined" 2 "Manual" 1 "Automatic" 0 "Off" ;
VAL_TABLE_ HsaStat_D_Dsply 7 "NotUsed3" 6 "NotUsed2" 5 "NotUsed1" 4 "NotAvailable" 3 "SlowReleaseWithChime" 2 "SlowReleaseWithoutChime" 1 "Active" 0 "Inactive" ;
VAL_TABLE_ EngMsgTxt_D_Rq 3 "Undefined_2" 2 "Undefined_1" 1 "Power_Reduced_to_LowerTemp" 0 "No_Message" ;
VAL_TABLE_ PassRstrnInd_Req 3 "ABOnNotIllum_OffNotIllum" 2 "AirbagOnNot_Illum_OffIllum" 1 "AirbagOn_Illum_OffNotIllum" 0 "AirbagOn_Illum_Off_Illum" ;
VAL_TABLE_ RearDiffLckMsg_D_Rq 7 "Locker_Disabled" 6 "Locker_Enabled" 5 "Locker_Accel_Pedal" 4 "Speed4" 3 "Speed3" 2 "Spee2" 1 "Speed1" 0 "Normal__No_Message " ;
VAL_TABLE_ GPS_dimension 2 "_3D" 1 "_2D" 0 "No_Fix" ;
VAL_TABLE_ GPS_Compass_dirctn 7 "NorthWest" 6 "West" 5 "SouthWest" 4 "South" 3 "SouthEast" 2 "East" 1 "NorthEast" 0 "North" ;
VAL_TABLE_ GPS_Actual_Infer 1 "Inferred_Position" 0 "Actual_Postition" ;
VAL_TABLE_ DrvHdcWarnInfo_D_Rq 3 "Undefined" 2 "Lamp_On_Continuously" 1 "Lamp_Flashing" 0 "Lamp_Off_Continuously" ;
VAL_TABLE_ DieslPrtcRgen_D_Actl 3 "Undefined" 2 "Regen_Level_2" 1 "Regen_Level_1" 0 "No_regen" ;
VAL_TABLE_ Off_On 1 "On" 0 "Off" ;
VAL_TABLE_ CcMde_D_Actl 7 "TapDownWaiting" 6 "TapUpWaiting" 5 "Resuming_Low" 4 "Resuming_High" 3 "Decelerating" 2 "Accelerating" 1 "Keeping_Speed" 0 "Not_Active" ;
VAL_TABLE_ InactiveActive 1 "Active" 0 "Inactive" ;
VAL_TABLE_ ManRgenTxt_D_RqDsply 7 "NotUsed3" 6 "NotUsed2" 5 "NotUsed1" 4 "Cleaning_Aborted_Stopped" 3 "Cleaning_Completed" 2 "Cleaning_In_Progress" 1 "Cleaning_Allowed" 0 "Cleaning_Not_Allowed" ;
VAL_TABLE_ Fault_FFFF 65535 "Fault" ;
VAL_TABLE_ Fault_7F 127 "Fault" ;
VAL_TABLE_ EngOilLvlWarn_D_Rq 7 "Undefined_3" 6 "Undefined_2" 5 "Engine_Oil_Monitor_Fault" 3 "Engine_Oil_High" 2 "Engine_Oil_Critical_Low" 1 "Engine_Oil_Low" 0 "No_Message" 4 "Engine_Oil_Critical_High" ;
VAL_TABLE_ UreaQltySys_D_RqDsply 7 "Undefined" 6 "ZZ_Overrides" 5 "EngineIdled" 4 "Engine_Idle_Upon_Refuel" 3 "SPEED_LIMITED_to_YY_mph" 2 "YY_MPH_MAX_UPON_Restart" 1 "CONTAMINATED_ExhFluid" 0 "NoQualityProblem" ;
VAL_TABLE_ Unknown_Invalid_1E_1F 31 "Invalid" 30 "Unknown" ;
VAL_TABLE_ Unknown_Invalid_3FFE_3FFF 16383 "Invalid" 16382 "Unknown" ;
VAL_TABLE_ NoYes 1 "Yes" 0 "No" ;
VAL_TABLE_ AwdRnge_D_Actl 7 "Unknown" 6 "High_Range_2wd" 5 "High_Range_Auto" 4 "High_Range_Locked" 3 "Neutral" 2 "Low_Range_2wd" 1 "Low_Range_Auto" 0 "Low_Range_Locked" ;
VAL_TABLE_ AwdLck_D_Stat 9 "Undefined" 8 "Under_External_Torque_Ctrl" 7 "Torque_Limited_by_Cmd" 6 "Fully_Locked_by_Cmd" 5 "Disabled" 4 "Warning" 3 "Fault" 2 "Inactive" 1 "Completely_Opened_by_Cmd" 0 "OK" ;
VAL_TABLE_ Unknown_Fault_3FE_3FF 1023 "Fault" 1022 "Unknown" ;
VAL_TABLE_ LockSwStat 3 "Invalid" 2 "Unlock" 1 "Lock" 0 "Null" ;
VAL_TABLE_ Null_Override 1 "Override" 0 "Null" ;
VAL_TABLE_ Off_On_Flash 3 "Not_Used" 2 "Flash" 1 "On" 0 "Off" ;
VAL_TABLE_ immoTargetStatCoding 7 "Unused4" 6 "Unused3" 5 "Unused2" 4 "ENABLED_LIMITEDMOTIVE_STAR" 3 "DISABLED_RESET   " 2 "ENABLED_NONMOTIVE_START" 1 "ENABLED_MOTIVE_START" 0 "DISABLED" ;
VAL_TABLE_ BeltBuckle 3 "Unknown" 2 "Unbelted" 1 "Belted" 0 "Faulty" ;
VAL_TABLE_ RILReqCoding 3 "Not_Used" 2 "Plant_Mode" 1 "On" 0 "Off" ;
VAL_TABLE_ Running_Board 3 "Unused" 2 "Manually_Deployed" 1 "All_Enabled" 0 "All_Disabled" ;
VAL_TABLE_ HudFlashRate 3 "Unused" 2 "Flash_4Hz_50Prct_DutyCycle" 1 "On" 0 "Off" ;
VAL_TABLE_ Turn_Seq 3 "Seq" 2 "On" 1 "Off" 0 "Null" ;
VAL_TABLE_ immoTargetCmdCoding 7 "Unused4" 6 "Unused3" 5 "Unused2" 4 "Unused1" 3 "TARGET1_IDBLOCK2" 2 "TARGET1_IDBLOCK1" 1 "CHALLENGE" 0 "IDLE" ;
VAL_TABLE_ immoSubTargetCmdCoding 7 "Unused3" 6 "Unused2" 5 "ECHO_TARGET1_IDBLOCK2" 4 "Unused1" 3 "RQST_TARGET1_IDBLOCK2" 2 "RQST_TARGET1_IDBLOCK1" 1 "RESPONSE" 0 "IDLE" ;
VAL_TABLE_ immoCtrlCmd2Coding 0 "IDLE" 1 "MOTIVE_START_RQST" 2 "NONMOTIVE_START_RQST" 3 "RQST_TARGET2_IDBLOCK1" 4 "RQST_TARGET2_IDBLOCK2" 5 "LIMITEDMOTIVE_START_RQST" 6 "ECHO_TARGET2_IDBLOCK2" 7 "SHUTDOWN" ;
VAL_TABLE_ immoCtrlCmdCoding 0 "IDLE" 1 "MOTIVE_START_RQST" 2 "NONMOTIVE_START_RQST" 3 "RQST_TARGET1_IDBLOCK1" 4 "RQST_TARGET1_IDBLOCK2" 5 "LIMITEDMOTIVE_START_RQST" 6 "ECHO_TARGET1_IDBLOCK2" 7 "SHUTDOWN" ;
VAL_TABLE_ Rvc_Zoom 7 "Unknown" 6 "Invalid" 5 "Zoom_Level_V" 4 "Zoom_Level_IV" 3 "Zoom_Level_III" 2 "Zoom_Level_II" 1 "Zoom_Level_I" 0 "Off" ;
VAL_TABLE_ NotPark 1 "Park" 0 "Not_Park" ;
VAL_TABLE_ Electric_EOH 1 "Electric_Over_Hydraulic" 0 "Electric" ;
VAL_TABLE_ PersOptIn 1 "OPTED_IN" 0 "NOT_OPTED_IN" ;
VAL_TABLE_ PersonalSetUp 3 "Non_Moveable_Person" 2 "Moveable_Person" 1 "Vehicle" 0 "Factory" ;
VAL_TABLE_ Full_Limited 1 "Limited" 0 "Full" ;
VAL_TABLE_ NoConflict_Conflict 1 "Conflict" 0 "No_Conflict" ;
VAL_TABLE_ Assoc_Confirm 0 "None" 7 "Associate" 6 "Keycode_Rejected" 5 "Keycode_Accepted" 4 "In_Progress" 3 "Erase" 2 "Duplicate" 1 "Disassociate" ;
VAL_TABLE_ Pers1_4 7 "Unused_3" 6 "Unused_2" 5 "Unused_1" 4 "Vehicle" 3 "PERS_4" 2 "PERS_3" 1 "PERS_2" 0 "PERS_1" ;
VAL_TABLE_ Null_Query 7 "Unused_2" 6 "Unused_1" 5 "Copy" 4 "Restore" 3 "Upload" 2 "Set" 1 "Query" 0 "Null" ;
VAL_TABLE_ EngExhBrkMde_D_Actl 6 "ExhBrkDisable_NoError" 5 "ExhBrkActive_AUTO" 4 "ExhBrkActive_ON" 3 "ExhBrkRequest_AUTO" 2 "ExhBrkRequest_ON" 1 "ExhBrkNoRequest_OFF" 0 "ExhBrkUnavailable_Error" ;
VAL_TABLE_ UreaLvlTxt_D_RqDsply 15 "NotUsed_4" 14 "NotUsed_3" 13 "NotUsed_2" 12 "NotUsed_1" 11 "System_Error" 10 "Engine_Idled_See_Manual" 9 "Engine_Idled_Upon_Refuel" 8 "Speed_Limited_To_XX_mph" 7 "XXmph_Max_Upon_Restart" 6 "Speed_Limited_To_YY_mph" 5 "YYmph_Max_Upon_Restart" 4 "SpdLimtd_YYmph_In_XXmiles" 3 "ExFlRange_XXMiles_ScndWarn" 2 "Exh_Fluid_Range_XX_Miles" 1 "Exh_Fluid_Under_Half_Full" 0 "Exh_Fluid_Over_Half_Full" ;
VAL_TABLE_ RearDiffFalt_D_Stat 3 "Diff_Failed_Closed" 2 "Diff_Failed_Open" 1 "Fault_Non_Specific" 0 "No_Fault" ;
VAL_TABLE_ CCOverridden 1 "Cruise_Overridden" 0 "Cruise_Req_Not_Overridden" ;
VAL_TABLE_ Ign_Key_Device_Type 15 "Invalid" 14 "Unknown" 3 "Key_Not_Prgrm_Read_Failure" 2 "Key_In_Ign_My_Key" 1 "Key_In_Ign_Standard_Key" 0 "Key_Read_In_Progress" ;
VAL_TABLE_ Off_No_Eff_Unknown_Invalid 3 "Invalid" 2 "Unknown" 1 "No_Effect" 0 "Off" ;
VAL_TABLE_ Null_Out 1 "Out" 0 "Null" ;
VAL_TABLE_ FUEL_SENSORS 1 "Dual_Sensors" 0 "Single_Sensor" ;

BO_ 1660 DEV_IPMB_Resp_31: 8 IPMA_ADAS
 SG_ DEV_IPMB_Sig_Resp_31 : 0|64@1+ (1,0) [0|65534] "" Vector__XXX

BO_ 1659 DEV_IPMB_Resp_28: 8 IPMA_ADAS
 SG_ DEV_IPMB_Sig_Resp_28 : 0|64@1+ (1,0) [0|65534] "" Vector__XXX

BO_ 1658 DEV_IPMB_Resp_27: 8 IPMA_ADAS
 SG_ DEV_IPMB_Sig_Resp_27 : 0|64@1+ (1,0) [0|65534] "" Vector__XXX

BO_ 1657 DEV_IPMB_Resp_26: 8 IPMA_ADAS
 SG_ DEV_IPMB_Sig_Resp_26 : 0|64@1+ (1,0) [0|65534] "" Vector__XXX

BO_ 1656 DEV_IPMB_Resp_25: 8 IPMA_ADAS
 SG_ DEV_IPMB_Sig_Resp_25 : 0|64@1+ (1,0) [0|65534] "" Vector__XXX

BO_ 1655 DEV_IPMB_Resp_24: 8 IPMA_ADAS
 SG_ DEV_IPMB_Sig_Resp_24 : 0|64@1+ (1,0) [0|65534] "" Vector__XXX

BO_ 1654 DEV_IPMB_Resp_23: 8 IPMA_ADAS
 SG_ DEV_IPMB_Sig_Resp_23 : 0|64@1+ (1,0) [0|65534] "" Vector__XXX

BO_ 1653 DEV_IPMB_Resp_22: 8 IPMA_ADAS
 SG_ DEV_IPMB_Sig_Resp_22 : 0|64@1+ (1,0) [0|65534] "" Vector__XXX

BO_ 1652 DEV_IPMB_Resp_21: 8 IPMA_ADAS
 SG_ DEV_IPMB_Sig_Resp_21 : 0|64@1+ (1,0) [0|65534] "" Vector__XXX

BO_ 1651 DEV_IPMB_Resp_20: 8 IPMA_ADAS
 SG_ DEV_IPMB_Sig_Resp_20 : 0|64@1+ (1,0) [0|65534] "" Vector__XXX

BO_ 1577 DEV_IPMB_Resp_19: 8 IPMA_ADAS
 SG_ DEV_IPMB_Sig_Resp_19 : 0|64@1+ (1,0) [0|65534] "" Vector__XXX

BO_ 1576 DEV_IPMB_Resp_18: 8 IPMA_ADAS
 SG_ DEV_IPMB_Sig_Resp_18 : 0|64@1+ (1,0) [0|65534] "" Vector__XXX

BO_ 1575 DEV_IPMB_Resp_17: 8 IPMA_ADAS
 SG_ DEV_IPMB_Sig_Resp_17 : 0|64@1+ (1,0) [0|65534] "" Vector__XXX

BO_ 1574 DEV_IPMB_Resp_15: 8 IPMA_ADAS
 SG_ DEV_IPMB_Sig_Resp_15 : 0|64@1+ (1,0) [0|65534] "" Vector__XXX

BO_ 1573 DEV_IPMB_Resp_14: 8 IPMA_ADAS
 SG_ DEV_IPMB_Sig_Resp_14 : 0|64@1+ (1,0) [0|65534] "" Vector__XXX

BO_ 1572 DEV_IPMB_Resp_13: 8 IPMA_ADAS
 SG_ DEV_IPMB_Sig_Resp_13 : 0|64@1+ (1,0) [0|65534] "" Vector__XXX

BO_ 1571 DEV_IPMB_Resp_12: 8 IPMA_ADAS
 SG_ DEV_IPMB_Sig_Resp_12 : 0|64@1+ (1,0) [0|65534] "" Vector__XXX

BO_ 1570 DEV_IPMB_Resp_11: 8 IPMA_ADAS
 SG_ DEV_IPMB_Sig_Resp_11 : 0|64@1+ (1,0) [0|65534] "" Vector__XXX

BO_ 1569 DEV_IPMB_Resp_10: 8 IPMA_ADAS
 SG_ DEV_IPMB_Sig_Resp_10 : 0|64@1+ (1,0) [0|65534] "" Vector__XXX

BO_ 1568 DEV_IPMB_Resp_09: 8 IPMA_ADAS
 SG_ DEV_IPMB_Sig_Resp_09 : 0|64@1+ (1,0) [0|65534] "" Vector__XXX

BO_ 1567 DEV_IPMB_Resp_08: 8 IPMA_ADAS
 SG_ DEV_IPMB_Sig_Resp_08 : 0|64@1+ (1,0) [0|65534] "" Vector__XXX

BO_ 1566 DEV_IPMB_Resp_07: 8 IPMA_ADAS
 SG_ DEV_IPMB_Sig_Resp_07 : 0|64@1+ (1,0) [0|65534] "" Vector__XXX

BO_ 1543 DEV_IPMB_Resp_06: 8 IPMA_ADAS
 SG_ DEV_IPMB_Sig_Resp_06 : 0|64@1+ (1,0) [0|65534] "" Vector__XXX

BO_ 1542 DEV_IPMB_Resp_05: 8 IPMA_ADAS
 SG_ DEV_IPMB_Sig_Resp_05 : 0|64@1+ (1,0) [0|65534] "" Vector__XXX

BO_ 1541 DEV_IPMB_Resp_04: 8 IPMA_ADAS
 SG_ DEV_IPMB_Sig_Resp_04 : 0|64@1+ (1,0) [0|1.84467440737096E+019] "" Vector__XXX

BO_ 1540 DEV_IPMB_Resp_03: 8 IPMA_ADAS
 SG_ DEV_IPMB_Sig_Resp_03 : 0|64@1+ (1,0) [0|65534] "" Vector__XXX

BO_ 1539 DEV_IPMB_Resp_02: 8 IPMA_ADAS
 SG_ DEV_IPMB_Sig_Resp_02 : 0|64@1+ (1,0) [0|65534] "" Vector__XXX

BO_ 1538 DEV_IPMB_Resp_01: 8 IPMA_ADAS
 SG_ DEV_IPMB_Sig_Resp_01 : 0|64@1+ (1,0) [0|65534] "" Vector__XXX

BO_ 1822 TesterPhysicalResGWM_FD1: 64 GWM
 SG_ TesterPhysicalResGWM_F1 : 7|64@0+ (1,0) [0|1.84467E+019] "unitless"  TSTR

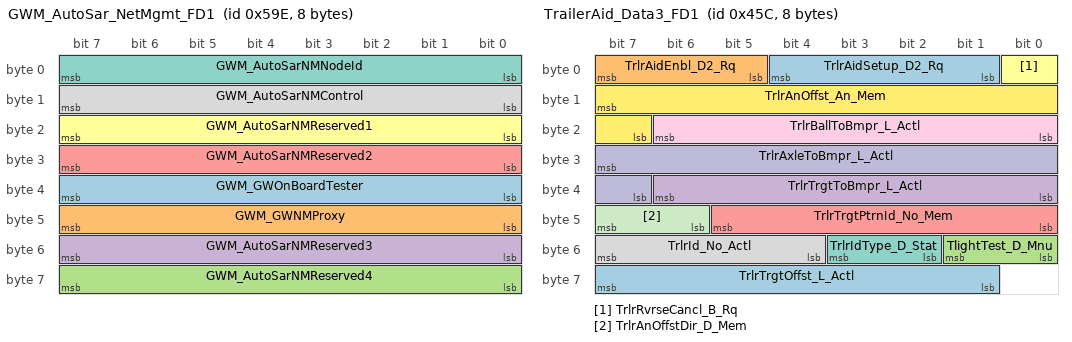
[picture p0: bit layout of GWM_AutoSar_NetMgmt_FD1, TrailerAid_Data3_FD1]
BO_ 1438 GWM_AutoSar_NetMgmt_FD1: 8 GWM
 SG_ GWM_GWOnBoardTester : 39|8@0+ (1,0) [0|255] "unitless"  CHCM,SOBDMC_HPCM_FD1,SIMA_DLCS,CMR_DSMC,ABS_ESC,AWD_DLCM,ECM,ECM_Diesel,ECM_HEV,ECM_HEVDSL,PCM,PCM_HEV,PSCM,TCCM,TCM,TCM_DSL
 SG_ GWM_GWNMProxy : 47|8@0+ (1,0) [0|255] "unitless"  SIMA_DLCS,CHCM,SOBDMC_HPCM_FD1,CMR_DSMC,ABS_ESC,AWD_DLCM,ECM,ECM_Diesel,ECM_HEV,ECM_HEVDSL,PCM,PCM_HEV,PSCM,TCCM,TCM,TCM_DSL
 SG_ GWM_AutoSarNMReserved4 : 63|8@0+ (1,0) [0|255] "unitless"  SIMA_DLCS,CHCM,SOBDMC_HPCM_FD1,CMR_DSMC,ABS_ESC,AWD_DLCM,ECM,ECM_Diesel,ECM_HEV,ECM_HEVDSL,PCM,PCM_HEV,PSCM,TCCM,TCM,TCM_DSL
 SG_ GWM_AutoSarNMReserved3 : 55|8@0+ (1,0) [0|255] "unitless"  SIMA_DLCS,CHCM,SOBDMC_HPCM_FD1,CMR_DSMC,ABS_ESC,AWD_DLCM,ECM,ECM_Diesel,ECM_HEV,ECM_HEVDSL,PCM,PCM_HEV,PSCM,TCCM,TCM,TCM_DSL
 SG_ GWM_AutoSarNMReserved2 : 31|8@0+ (1,0) [0|255] "unitless"  SIMA_DLCS,CHCM,SOBDMC_HPCM_FD1,CMR_DSMC,ABS_ESC,AWD_DLCM,ECM,ECM_Diesel,ECM_HEV,ECM_HEVDSL,PCM,PCM_HEV,PSCM,TCCM,TCM,TCM_DSL
 SG_ GWM_AutoSarNMReserved1 : 23|8@0+ (1,0) [0|255] "unitless"  SIMA_DLCS,CHCM,SOBDMC_HPCM_FD1,CMR_DSMC,ABS_ESC,AWD_DLCM,ECM,ECM_Diesel,ECM_HEV,ECM_HEVDSL,PCM,PCM_HEV,PSCM,TCCM,TCM,TCM_DSL
 SG_ GWM_AutoSarNMNodeId : 7|8@0+ (1,0) [0|255] "unitless"  SIMA_DLCS,CHCM,SOBDMC_HPCM_FD1,CMR_DSMC,ABS_ESC,AWD_DLCM,ECM,ECM_Diesel,ECM_HEV,ECM_HEVDSL,PCM,PCM_HEV,PSCM,TCCM,TCM,TCM_DSL
 SG_ GWM_AutoSarNMControl : 15|8@0+ (1,0) [0|255] "unitless"  SIMA_DLCS,SOBDMC_HPCM_FD1,CMR_DSMC,ABS_ESC,AWD_DLCM,ECM,ECM_Diesel,ECM_HEV,ECM_HEVDSL,PCM,PCM_HEV,PSCM,TCCM,TCM,TCM_DSL

BO_ 1116 TrailerAid_Data3_FD1: 8 GWM
 SG_ TrlrAidSetup_D2_Rq : 4|4@0+ (1,0) [0|15] "SED"  IPMA_ADAS,PSCM
 SG_ TrlrAidEnbl_D2_Rq : 7|3@0+ (1,0) [0|7] "SED"  PSCM,IPMA_ADAS
 SG_ TlightTest_D_Mnu : 49|2@0+ (1,0) [0|3] "SED"  GENERIC
 SG_ TrlrTrgtToBmpr_L_Actl : 38|7@0+ (0.0127,0) [0|1.6129] "meter"  IPMA_ADAS,PSCM
 SG_ TrlrTrgtPtrnId_No_Mem : 45|6@0+ (1,0) [0|63] "unitless"  IPMA_ADAS
 SG_ TrlrRvrseCancl_B_Rq : 0|1@0+ (1,0) [0|1] "SED"  IPMA_ADAS,PSCM
 SG_ TrlrIdType_D_Stat : 51|2@0+ (1,0) [0|3] "SED"  IPMA_ADAS,PSCM
 SG_ TrlrId_No_Actl : 55|4@0+ (1,0) [0|15] "unitless"  IPMA_ADAS,PSCM
 SG_ TrlrBallToBmpr_L_Actl : 22|7@0+ (0.0127,0) [0|1.6129] "meter"  IPMA_ADAS,PSCM
 SG_ TrlrAxleToBmpr_L_Actl : 31|9@0+ (0.0254,0) [0|12.9794] "meter"  IPMA_ADAS,PSCM
 SG_ TrlrAnOffstDir_D_Mem : 47|2@0+ (1,0) [0|3] "SED"  IPMA_ADAS,PSCM
 SG_ TrlrAnOffst_An_Mem : 15|9@0+ (0.1,0) [0|51.1] "degrees"  IPMA_ADAS,PSCM
 SG_ TrlrTrgtOffst_L_Actl : 63|7@0+ (0.0127,0) [0|1.6129] "meter"  PSCM,IPMA_ADAS

BO_ 1844 TesterPhysicalReqHCM: 64 TSTR
 SG_ TesterPhysicalReqHCM : 7|64@0+ (1,0) [0|1.84467E+019] "unitless"  HCM

BO_ 954 Body_Info_10_FD1: 8 GWM
 SG_ VehWlcmFrwlMde_D_Stat : 29|3@0+ (1,0) [0|7] "SED"  ABS_ESC,HCM,SIMA_DLCS
 SG_ GenericSwtch3_No_Actl : 15|3@0+ (1,0) [0|7] "unitless"  HCM,GENERIC
 SG_ GenericSwtch2_No_Actl : 4|3@0+ (1,0) [0|7] "unitless"  PCM,PCM_HEV,TCM_DSL,HCM
 SG_ GenericSwtch1_No_Actl : 7|3@0+ (1,0) [0|7] "unitless"  HCM,GENERIC
 SG_ PudSptLghtRight_D_Rq : 17|2@0+ (1,0) [0|3] "SED"  GENERIC
 SG_ PudSptLghtLeft_D_Rq : 19|2@0+ (1,0) [0|3] "SED"  GENERIC
 SG_ ExtLghtRight_D_Stat : 21|2@0+ (1,0) [0|3] "SED"  GENERIC
 SG_ ExtLghtRear_D_Stat : 23|2@0+ (1,0) [0|3] "SED"  GENERIC
 SG_ ExtLghtLeft_D_Stat : 9|2@0+ (1,0) [0|3] "SED"  GENERIC
 SG_ ExtLghtFront_D_Stat : 11|2@0+ (1,0) [0|3] "SED"  GENERIC
 SG_ TlghtTestLght_D_Stat : 44|3@0+ (1,0) [0|7] "SED"  GENERIC
 SG_ LghtAmbDrvMde_B_Stat : 34|1@0+ (1,0) [0|1] "SED"  GENERIC
 SG_ KeylessIdl_B_Stat : 41|1@0+ (1,0) [0|1] "SED"  GENERIC
 SG_ PwRnngBoardPoll_D_Stat : 36|2@0+ (1,0) [0|3] "SED"  GENERIC
 SG_ PoliceDmngLvl_D_Stat : 39|3@0+ (1,0) [0|7] "SED"  GENERIC
 SG_ TrlrHitchLamp_D_Stat : 25|1@0+ (1,0) [0|1] "SED"  GENERIC
 SG_ LicPlateLght_B_Stat : 26|1@0+ (1,0) [0|1] "SED"  GENERIC
 SG_ TrukBedLght_B_Stat : 24|1@0+ (1,0) [0|1] "SED"  GENERIC
 SG_ VehWlcmFrwl_D_Stat : 31|2@0+ (1,0) [0|3] "SED"  HCM,SIMA_DLCS
 SG_ TlghtTestPrecnd_D_Stat : 47|3@0+ (1,0) [0|7] "SED"  GENERIC
 SG_ TlghtTest_D_Stat : 33|2@0+ (1,0) [0|3] "SED"  GENERIC
 SG_ ExtLghtAlrt_B_Rq : 12|1@0+ (1,0) [0|1] "SED"  GENERIC
 SG_ ExtLght_D_Falt : 1|2@0+ (1,0) [0|3] "SED"  GENERIC

BO_ 1852 TesterPhysicalResHCM: 64 HCM
 SG_ TesterPhysicalResHCM : 7|64@0+ (1,0) [0|1.84467E+019] "unitless"  TSTR

BO_ 989 Personality_HCM_Data: 8 HCM
 SG_ FeatNoHcm_No_Actl : 23|16@0+ (1,0) [0|65535] "Number"  GWM
 SG_ FeatConfigHcmActl : 7|16@0+ (1,0) [0|65535] "Undefined"  GWM

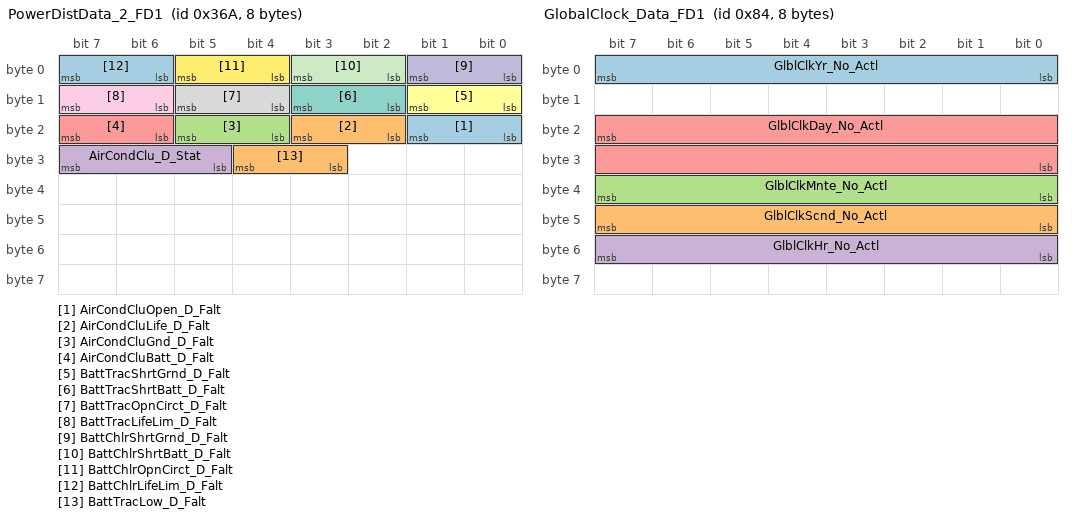
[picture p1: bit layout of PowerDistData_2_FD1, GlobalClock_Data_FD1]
BO_ 874 PowerDistData_2_FD1: 8 GWM
 SG_ AirCondCluOpen_D_Falt : 17|2@0+ (1,0) [0|3] "SED"  ECM_Diesel,ECM_HEVDSL,PCM
 SG_ AirCondCluLife_D_Falt : 19|2@0+ (1,0) [0|3] "SED"  ECM_Diesel,ECM_HEVDSL,PCM
 SG_ AirCondCluGnd_D_Falt : 21|2@0+ (1,0) [0|3] "SED"  ECM_Diesel,ECM_HEVDSL,PCM
 SG_ AirCondClu_D_Stat : 31|3@0+ (1,0) [0|7] "SED"  ECM_Diesel,ECM_HEVDSL,PCM
 SG_ AirCondCluBatt_D_Falt : 23|2@0+ (1,0) [0|3] "SED"  ECM_Diesel,ECM_HEVDSL,PCM
 SG_ BattTracShrtGrnd_D_Falt : 9|2@0+ (1,0) [0|3] "SED"  SOBDMC_HPCM_FD1,GENERIC
 SG_ BattTracShrtBatt_D_Falt : 11|2@0+ (1,0) [0|3] "SED"  SOBDMC_HPCM_FD1,GENERIC
 SG_ BattTracOpnCirct_D_Falt : 13|2@0+ (1,0) [0|3] "SED"  SOBDMC_HPCM_FD1,GENERIC
 SG_ BattTracLifeLim_D_Falt : 15|2@0+ (1,0) [0|3] "SED"  SOBDMC_HPCM_FD1,GENERIC
 SG_ BattChlrShrtGrnd_D_Falt : 1|2@0+ (1,0) [0|3] "SED"  SOBDMC_HPCM_FD1,GENERIC
 SG_ BattChlrShrtBatt_D_Falt : 3|2@0+ (1,0) [0|3] "SED"  SOBDMC_HPCM_FD1,GENERIC
 SG_ BattChlrOpnCirct_D_Falt : 5|2@0+ (1,0) [0|3] "SED"  SOBDMC_HPCM_FD1,GENERIC
 SG_ BattChlrLifeLim_D_Falt : 7|2@0+ (1,0) [0|3] "SED"  SOBDMC_HPCM_FD1,GENERIC
 SG_ BattTracLow_D_Falt : 28|2@0+ (1,0) [0|3] "SED"  SOBDMC_HPCM_FD1

BO_ 551 APIM_Request_Signals_1_FD1: 8 GWM
 SG_ Rba_D_Rq : 31|2@0+ (1,0) [0|3] "SED"  IPMA_ADAS
 SG_ EmPrflNo_D_Rq : 61|3@0+ (1,0) [0|7] "SED"  GENERIC
 SG_ EmPrflButtnAssoc_D_Rq : 33|2@0+ (1,0) [0|3] "SED"  GENERIC
 SG_ EmPrflKeyAssoc_D_Rq : 46|3@0+ (1,0) [0|7] "SED"  GENERIC
 SG_ Em_D_Stat : 63|2@0+ (1,0) [0|3] "SED"  GENERIC
 SG_ ChrgOvrdExitScrn_D_Rq : 58|2@0+ (1,0) [0|3] "SED"  GENERIC
 SG_ PrcondEdit_D_RqMnu : 15|3@0+ (1,0) [0|7] "SED"  SOBDMC_HPCM_FD1
 SG_ ChrgToPcEdit_Pc_RqMnu : 23|7@0+ (1,0) [0|125] "percent"  SOBDMC_HPCM_FD1
 SG_ EcoIdl_D_Rq : 7|2@0+ (1,0) [0|3] "SED"  PCM_HEV,SOBDMC_HPCM_FD1
 SG_ PmCabnLvl_D_Stat : 36|3@0+ (1,0) [0|7] "SED"  GENERIC
 SG_ PmCabn_D_Stat : 38|2@0+ (1,0) [0|3] "SED"  GENERIC
 SG_ PwRnngBoardSwtch_D_Rq : 27|2@0+ (1,0) [0|3] "SED"  GENERIC
 SG_ PwRnngBoardMde_D_Rq : 29|2@0+ (1,0) [0|3] "SED"  GENERIC
 SG_ PwRnngBoardT_D_Rq : 25|2@0+ (1,0) [0|3] "SED"  GENERIC
 SG_ OneTEditActv_B_RqMnu : 40|1@0+ (1,0) [0|1] "SED"  SOBDMC_HPCM_FD1
 SG_ GoTElementEdit_No_RqMnu : 12|4@0+ (1,0) [0|15] "unitless"  SOBDMC_HPCM_FD1
 SG_ Cntr_Plg_Mode_Cmd : 39|1@0+ (1,0) [0|1] "SED"  GENERIC
 SG_ BattTracLoThres_D_Rq : 43|3@0+ (1,0) [0|7] "SED"  SOBDMC_HPCM_FD1
 SG_ ChrgCrdLckEnbl_B_Stat : 47|1@0+ (1,0) [0|1] "SED"  GENERIC
 SG_ Btt_L_Actl2 : 55|7@0+ (0.1,0) [0|12.5] "meter"  IPMA_ADAS

BO_ 132 GlobalClock_Data_FD1: 8 GWM
 SG_ GlblClkYr_No_Actl : 7|8@0+ (1,2000) [2000|2255] "year"  SOBDMC_HPCM_FD1,IPMA_ADAS,CMR_DSMC
 SG_ GlblClkScnd_No_Actl : 47|8@0+ (1,0) [0|255] "second"  SOBDMC_HPCM_FD1,IPMA_ADAS,CMR_DSMC
 SG_ GlblClkMnte_No_Actl : 39|8@0+ (1,0) [0|255] "minute"  SOBDMC_HPCM_FD1,IPMA_ADAS,CMR_DSMC
 SG_ GlblClkHr_No_Actl : 55|8@0+ (1,0) [0|255] "hour"  SOBDMC_HPCM_FD1,IPMA_ADAS,CMR_DSMC
 SG_ GlblClkDay_No_Actl : 23|16@0+ (1,0) [0|65535] "julian day"  SOBDMC_HPCM_FD1,IPMA_ADAS,CMR_DSMC

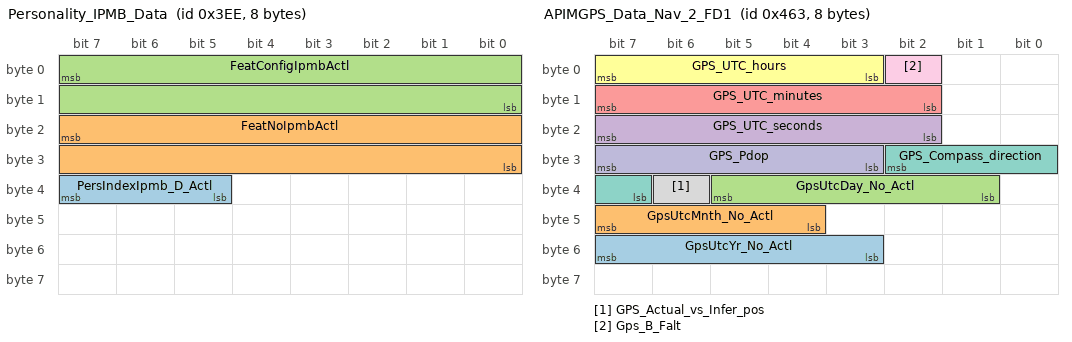
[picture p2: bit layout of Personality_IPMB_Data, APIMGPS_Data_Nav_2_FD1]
BO_ 1006 Personality_IPMB_Data: 8 IPMA_ADAS
 SG_ PersIndexIpmb_D_Actl : 39|3@0+ (1,0) [0|7] "SED"  GWM
 SG_ FeatNoIpmbActl : 23|16@0+ (1,0) [0|65535] "Number"  GWM
 SG_ FeatConfigIpmbActl : 7|16@0+ (1,0) [0|65535] "Undefined"  GWM

BO_ 1123 APIMGPS_Data_Nav_2_FD1: 8 GWM
 SG_ GpsUtcYr_No_Actl : 55|5@0+ (1,2010) [2010|2040] "Year"  SOBDMC_HPCM_FD1,IPMA_ADAS
 SG_ GpsUtcMnth_No_Actl : 47|4@0+ (1,1) [1|15] "Month"  SOBDMC_HPCM_FD1,IPMA_ADAS
 SG_ GpsUtcDay_No_Actl : 37|5@0+ (1,1) [1|32] "Day"  SOBDMC_HPCM_FD1,IPMA_ADAS
 SG_ GPS_UTC_seconds : 23|6@0+ (1,0) [0|59] "seconds"  SOBDMC_HPCM_FD1,IPMA_ADAS
 SG_ GPS_UTC_minutes : 15|6@0+ (1,0) [0|59] "Minutes"  SOBDMC_HPCM_FD1,IPMA_ADAS
 SG_ GPS_UTC_hours : 7|5@0+ (1,0) [0|23] "Hours"  SOBDMC_HPCM_FD1,IPMA_ADAS
 SG_ GPS_Compass_direction : 26|4@0+ (1,0) [0|15] "SED"  SOBDMC_HPCM_FD1,IPMA_ADAS
 SG_ GPS_Actual_vs_Infer_pos : 38|1@0+ (1,0) [0|1] "SED"  SOBDMC_HPCM_FD1,IPMA_ADAS
 SG_ Gps_B_Falt : 2|1@0+ (1,0) [0|1] "SED"  SOBDMC_HPCM_FD1,IPMA_ADAS
 SG_ GPS_Pdop : 31|5@0+ (0.2,0) [0|5.8] "unitless"  IPMA_ADAS,SOBDMC_HPCM_FD1

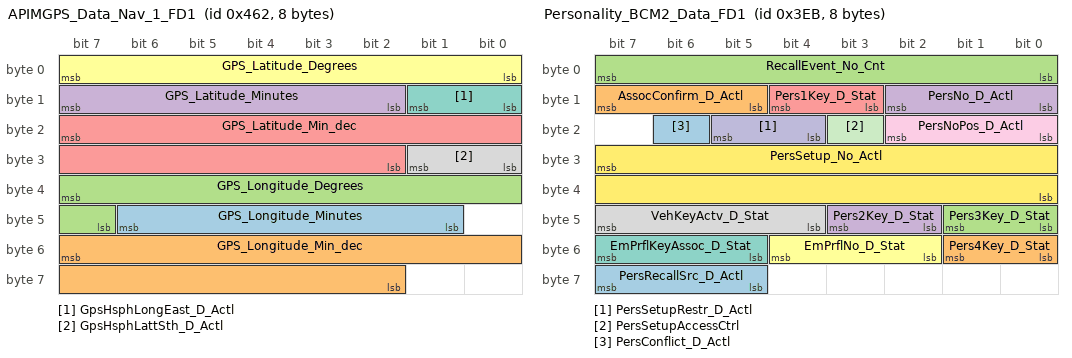
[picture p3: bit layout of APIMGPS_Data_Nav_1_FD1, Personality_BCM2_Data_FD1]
BO_ 1122 APIMGPS_Data_Nav_1_FD1: 8 GWM
 SG_ GPS_Longitude_Minutes : 46|6@0+ (1,0) [0|61] "Minutes"  SOBDMC_HPCM_FD1,IPMA_ADAS
 SG_ GPS_Longitude_Min_dec : 55|14@0+ (0.0001,0) [0|1.6381] "Minutes"  SOBDMC_HPCM_FD1,IPMA_ADAS
 SG_ GPS_Longitude_Degrees : 39|9@0+ (1,-179) [-179|330] "Degrees"  SOBDMC_HPCM_FD1,IPMA_ADAS
 SG_ GPS_Latitude_Minutes : 15|6@0+ (1,0) [0|61] "Minutes"  SOBDMC_HPCM_FD1,IPMA_ADAS
 SG_ GPS_Latitude_Min_dec : 23|14@0+ (0.0001,0) [0|1.6381] "Minutes"  SOBDMC_HPCM_FD1,IPMA_ADAS
 SG_ GPS_Latitude_Degrees : 7|8@0+ (1,-89) [-89|164] "Degrees"  SOBDMC_HPCM_FD1,IPMA_ADAS
 SG_ GpsHsphLongEast_D_Actl : 9|2@0+ (1,0) [0|3] "SED"  SOBDMC_HPCM_FD1,IPMA_ADAS
 SG_ GpsHsphLattSth_D_Actl : 25|2@0+ (1,0) [0|3] "SED"  SOBDMC_HPCM_FD1,IPMA_ADAS

BO_ 1003 Personality_BCM2_Data_FD1: 8 GWM
 SG_ PersRecallSrc_D_Actl : 63|3@0+ (1,0) [0|7] "SED"  GENERIC
 SG_ Pers4Key_D_Stat : 49|2@0+ (1,0) [0|3] "SED"  GENERIC
 SG_ Pers3Key_D_Stat : 41|2@0+ (1,0) [0|3] "SED"  GENERIC
 SG_ Pers2Key_D_Stat : 43|2@0+ (1,0) [0|3] "SED"  GENERIC
 SG_ Pers1Key_D_Stat : 12|2@0+ (1,0) [0|3] "SED"  GENERIC
 SG_ EmPrflNo_D_Stat : 52|3@0+ (1,0) [0|7] "SED"  GENERIC
 SG_ EmPrflKeyAssoc_D_Stat : 55|3@0+ (1,0) [0|7] "SED"  GENERIC
 SG_ VehKeyActv_D_Stat : 47|4@0+ (1,0) [0|15] "SED"  SOBDMC_HPCM_FD1,HCM,GENERIC
 SG_ PersNoPos_D_Actl : 18|3@0+ (1,0) [0|7] "SED"  HCM,VDM,GENERIC
 SG_ PersSetupRestr_D_Actl : 21|2@0+ (1,0) [0|3] "SED"  SOBDMC_HPCM_FD1,HCM,VDM,GENERIC
 SG_ PersSetupAccessCtrl : 19|1@0+ (1,0) [0|1] "SED"  SOBDMC_HPCM_FD1,HCM,VDM,GENERIC
 SG_ PersSetup_No_Actl : 31|16@0+ (1,0) [0|65535] "Number"  SOBDMC_HPCM_FD1,HCM,VDM,GENERIC
 SG_ PersConflict_D_Actl : 22|1@0+ (1,0) [0|1] "SED"  HCM,GENERIC
 SG_ AssocConfirm_D_Actl : 15|3@0+ (1,0) [0|7] "SED"  HCM,GENERIC
 SG_ RecallEvent_No_Cnt : 7|8@0+ (1,0) [0|255] "Counts"  HCM,VDM,IPMA_ADAS
 SG_ PersNo_D_Actl : 10|3@0+ (1,0) [0|7] "SED"  SOBDMC_HPCM_FD1,HCM,VDM,IPMA_ADAS,ABS_ESC

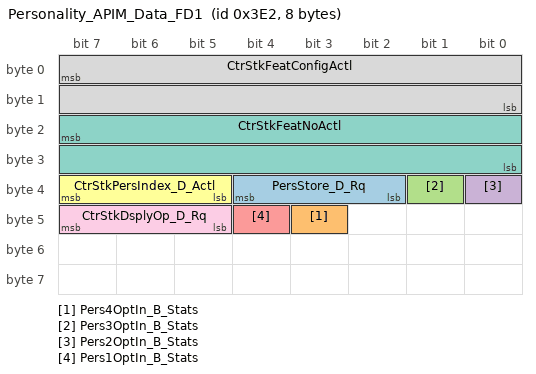
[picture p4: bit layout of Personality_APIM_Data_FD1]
BO_ 994 Personality_APIM_Data_FD1: 8 GWM
 SG_ PersStore_D_Rq : 36|3@0+ (1,0) [0|7] "SED"  GENERIC
 SG_ Pers4OptIn_B_Stats : 43|1@0+ (1,0) [0|1] "SED"  GENERIC
 SG_ Pers3OptIn_B_Stats : 33|1@0+ (1,0) [0|1] "SED"  GENERIC
 SG_ Pers2OptIn_B_Stats : 32|1@0+ (1,0) [0|1] "SED"  GENERIC
 SG_ Pers1OptIn_B_Stats : 44|1@0+ (1,0) [0|1] "SED"  GENERIC
 SG_ CtrStkPersIndex_D_Actl : 39|3@0+ (1,0) [0|7] "SED"  ABS_ESC,SOBDMC_HPCM_FD1,HCM,VDM,IPMA_ADAS
 SG_ CtrStkFeatNoActl : 23|16@0+ (1,0) [0|65535] "Undefined"  PCM,ABS_ESC,SOBDMC_HPCM_FD1,HCM,VDM,IPMA_ADAS
 SG_ CtrStkFeatConfigActl : 7|16@0+ (1,0) [0|65535] "Undefined"  PCM,ABS_ESC,SOBDMC_HPCM_FD1,HCM,VDM,IPMA_ADAS
 SG_ CtrStkDsplyOp_D_Rq : 47|3@0+ (1,0) [0|7] "SED"  PCM,ABS_ESC,SOBDMC_HPCM_FD1,HCM,VDM,IPMA_ADAS

CM_ "New CAN FD network (Flexible Data Rate)";
CM_ BU_ TCM "Transmission Control Module";
CM_ BU_ HCM "Headlamp Ctrl. Mod.A (HS_CAN), Adaptive Headlamps";
CM_ BU_ IPMA_ADAS "Assist Driving Alert System";
CM_ BU_ PSCM "Power Steering Control Module";
CM_ BU_ ABS_ESC "Anti-lock Brake / Traction Control Module";
CM_ BU_ TCCM "Transfer Case Control Module, 4x4 Control Module";
CM_ BU_ TCM_DSL "Transmission Control Module";
CM_ BU_ PCM_HEV "PCM HEV";
CM_ BU_ PCM "Powertrain Control Module";
CM_ BU_ ECM_HEVDSL "HEV Diesel ";
CM_ BU_ ECM_HEV "HEV ECM";
CM_ BU_ ECM_Diesel "Diesel";
CM_ BU_ ECM "Gas FD";
CM_ BU_ SIMA_DLCS "Switch Input Module A - Driveline Chassis Switch";
CM_ BU_ BCMD_IPDB "IPDB Interior Power Distribtuion Box";
CM_ BU_ VDM "Vehicle Dynamics Control Module";
CM_ BU_ CMR_DSMC "Driver Status Monitor Camera";
CM_ BU_ CHCM "Chassis Control Module Stabilizer bar disconnect module ";
CM_ BU_ GWM "Gateway Module CGEA1.3(Star Architecture)";
CM_ BU_ AWD_DLCM "Differential Lock Control module";
CM_ BU_ GENERIC "holding pattern ECU for developmental messages";
CM_ BU_ TSTR "Diagnostic Tester";
CM_ SG_ 954 GenericSwtch2_No_Actl "U625 Police Wig Wag feature";
CM_ BO_ 1123 "HS3 APIM Sync Gen3 Tx 0x463.  FrameGateway to 0x466 on HS1, HS2, HS3 and MS1.";
CM_ BO_ 1122 "HS3 APIM Sync Gen3 Tx 0x462.  FrameGateway to 0x465 on HS1, HS2, HS3 and MS1.";
BA_DEF_ BO_  "VFrameFormat" ENUM  "StandardCAN","ExtendedCAN","reserved","reserved","reserved","reserved","reserved","reserved","reserved","reserved","reserved","reserved","reserved","reserved","StandardCAN_FD","ExtendedCAN_FD";
BA_DEF_ BO_  "DiagConnection" INT 0 256;
BA_DEF_  "BusType" STRING ;
BA_DEF_ BO_  "FrameRouting" STRING ;
BA_DEF_ BO_  "FrameGatewayNetwork" STRING ;
BA_DEF_ BO_  "NetworkInitialization" ENUM  "No","Yes";
BA_DEF_ BO_  "FrameGatewayId" HEX 0 1407;
BA_DEF_ BO_  "EventRateOfChange" INT 10 10000;
BA_DEF_ BO_  "GenMsgStartDelayTime" INT 0 10000;
BA_DEF_ BO_  "GenMsgNrOfRepetition" INT 0 100;
BA_DEF_ BO_  "GenMsgDelayTime" INT 0 1000;
BA_DEF_ BO_  "GenMsgCycleTime" INT 0 100000;
BA_DEF_ BO_  "GenMsgSendType" ENUM  "FixedPeriodic","Event","EnabledPeriodic","NotUsed","NotUsed","EventPeriodic","NotUsed","NotUsed","NoMsgSendType";
BA_DEF_ SG_  "U_U55X_MY2022_Tx" ENUM  "No","Yes";
BA_DEF_ SG_  "U_CD542_MY2021_Tx" ENUM  "No","Yes";
BA_DEF_ SG_  "ECGUsedTxSignal" ENUM  "No","Yes";
BA_DEF_ SG_  "U_T6_MCA_MY2020_Tx" ENUM  "No","Yes";
BA_DEF_ SG_  "U_P702_MY2021_Tx" ENUM  "No","Yes";
BA_DEF_ SG_  "U_CX727_MY2021_Tx" ENUM  "No","Yes";
BA_DEF_ SG_  "U_U55X_MY2022_Rx" ENUM  "No","Yes";
BA_DEF_ SG_  "U_CD542_MY2021_Rx" ENUM  "No","Yes";
BA_DEF_ SG_  "ECGUsedRxSignal" ENUM  "No","Yes";
BA_DEF_ SG_  "U_T6_MCA_MY2020_Rx" ENUM  "No","Yes";
BA_DEF_ SG_  "U_P702_MY2021_Rx" ENUM  "No","Yes";
BA_DEF_ SG_  "U_CX727_MY2021_Rx" ENUM  "No","Yes";
BA_DEF_ SG_  "GenSigStartValue" HEX 0 268435455;
BA_DEF_ SG_  "MetaData" ENUM  "No","Yes";
BA_DEF_ SG_  "ContentDependant" ENUM  "No","Yes";
BA_DEF_ SG_  "GenSigStartValueInteger" INT 0 1000000000;
BA_DEF_ SG_  "UsedOnPgmDBC" ENUM  "No","Yes";
BA_DEF_ SG_  "WakeupSignal" ENUM  "No","Yes";
BA_DEF_ SG_  "GenSigInactiveValue" INT 0 100000;
BA_DEF_ SG_  "GenSigSendType" ENUM  "Cyclic","OnWrite","vector_leerstring","OnChange","vector_leerstring","IfActive","vector_leerstring","NoSigSendType";
BA_DEF_ BO_  "OvtpPushApplication" ENUM  "FALSE","TRUE";
BA_DEF_ BO_  "SCP_FreshnessValueLength" INT 0 512;
BA_DEF_ BO_  "SCP_FreshnessValueTxLength" INT 0 512;
BA_DEF_ BO_  "SCP_AuthInfoTxLength" INT 0 512;
BA_DEF_ BO_  "ProgBWConditional" STRING ;
BA_DEF_ BO_  "NmAsrMessage" ENUM  "No","Yes";
BA_DEF_ BO_  "TpApplType" STRING ;
BA_DEF_ BO_  "DiagState" ENUM  "No","Yes";
BA_DEF_ BO_  "TpTxIndex" INT 0 536870911;
BA_DEF_ BO_  "DiagRequest" ENUM  "No","Yes";
BA_DEF_ BO_  "DiagResponse" ENUM  "No","Yes";
BA_DEF_ BO_  "GenMsgILSupport" ENUM  "No","Yes";
BA_DEF_ BU_  "OvtpOperationMode" ENUM  "SERVER","CLIENT";
BA_DEF_ BU_  "OvtpEcuAddress" INT 0 1022;
BA_DEF_ BU_  "ILUsed" ENUM  "No","Yes";
BA_DEF_ BU_  "Terminator" ENUM  "No","Yes";
BA_DEF_ BU_  "NodeWakeUpTime" INT 0 10000;
BA_DEF_ BU_  "NodeStartUpTime" INT 0 10000;
BA_DEF_ BU_  "NmAsrNodeIdentifier" HEX 128 255;
BA_DEF_ BU_  "NmAsrNode" ENUM  "No","Yes";
BA_DEF_ BU_  "PowerType" ENUM  "Switched","Latched","Sleep","vector_leerstring","vector_leerstring";
BA_DEF_ BU_  "DiagNode" ENUM  "GGDS","GDS","NONE";
BA_DEF_ BU_  "EOL_SB_Flash" ENUM  "GGDS","GDS","NONE","vector_leerstring";
BA_DEF_ BU_  "NmStationAddress" INT 0 255;
BA_DEF_ BU_  "NosPackage" ENUM  "None","I3_1","I3_2","1.0.1","RP","EuCD","Volcano","I3_3","FNOS_Autosar";
BA_DEF_ BU_  "PackageID" STRING ;
BA_DEF_ BU_  "GatewayECU" ENUM  "No","Yes";
BA_DEF_  "NetworkSpeed" ENUM  "500kBits/s","125kBit/s";
BA_DEF_  "VersionNumber" INT 0 10000;
BA_DEF_  "StarNetworkGwType" ENUM  "0=NotDefined","1=HS1","2=HS2","3=HS3","4=HS4","5=HS5","6=MS1","7=HS6","8=HS7","9=MS2","10=FD1","11=FD2","12=FD3","13=FD4","14=FD5","15=FD6","16=FD7","17=FD8";
BA_DEF_  "CMDB_Version" STRING ;
BA_DEF_  "NmType" STRING ;
BA_DEF_  "NmAsrMessageCount" INT 128 128;
BA_DEF_  "NmAsrBaseAddress" HEX 1408 1408;
BA_DEF_  "DBName" STRING ;
BA_DEF_  "VersionDay" INT 1 31;
BA_DEF_  "Manufacturer" STRING ;
BA_DEF_  "VersionMonth" INT 1 12;
BA_DEF_  "VersionYear" INT 2000 3000;
BA_DEF_  "NmBaseAddress" HEX 1280 1280;
BA_DEF_  "NmMessageCount" INT 0 128;
BA_DEF_ BU_  "NodeLayerModules" STRING ;
BA_DEF_DEF_  "VFrameFormat" "ExtendedCAN_FD";
BA_DEF_DEF_  "DiagConnection" 0;
BA_DEF_DEF_  "BusType" "";
BA_DEF_DEF_  "FrameRouting" "";
BA_DEF_DEF_  "FrameGatewayNetwork" "NONE";
BA_DEF_DEF_  "NetworkInitialization" "Yes";
BA_DEF_DEF_  "FrameGatewayId" 0;
BA_DEF_DEF_  "EventRateOfChange" 10000;
BA_DEF_DEF_  "GenMsgStartDelayTime" 0;
BA_DEF_DEF_  "GenMsgNrOfRepetition" 1;
BA_DEF_DEF_  "GenMsgDelayTime" 20;
BA_DEF_DEF_  "GenMsgCycleTime" 0;
BA_DEF_DEF_  "GenMsgSendType" "NoMsgSendType";
BA_DEF_DEF_  "U_U55X_MY2022_Tx" "No";
BA_DEF_DEF_  "U_CD542_MY2021_Tx" "No";
BA_DEF_DEF_  "ECGUsedTxSignal" "No";
BA_DEF_DEF_  "U_T6_MCA_MY2020_Tx" "No";
BA_DEF_DEF_  "U_P702_MY2021_Tx" "No";
BA_DEF_DEF_  "U_CX727_MY2021_Tx" "No";
BA_DEF_DEF_  "U_U55X_MY2022_Rx" "No";
BA_DEF_DEF_  "U_CD542_MY2021_Rx" "No";
BA_DEF_DEF_  "ECGUsedRxSignal" "No";
BA_DEF_DEF_  "U_T6_MCA_MY2020_Rx" "No";
BA_DEF_DEF_  "U_P702_MY2021_Rx" "No";
BA_DEF_DEF_  "U_CX727_MY2021_Rx" "No";
BA_DEF_DEF_  "GenSigStartValue" 0;
BA_DEF_DEF_  "MetaData" "No";
BA_DEF_DEF_  "ContentDependant" "No";
BA_DEF_DEF_  "GenSigStartValueInteger" 0;
BA_DEF_DEF_  "UsedOnPgmDBC" "Yes";
BA_DEF_DEF_  "WakeupSignal" "No";
BA_DEF_DEF_  "GenSigInactiveValue" 0;
BA_DEF_DEF_  "GenSigSendType" "NoSigSendType";
BA_DEF_DEF_  "OvtpPushApplication" "FALSE";
BA_DEF_DEF_  "SCP_FreshnessValueLength" 64;
BA_DEF_DEF_  "SCP_FreshnessValueTxLength" 11;
BA_DEF_DEF_  "SCP_AuthInfoTxLength" 53;
BA_DEF_DEF_  "ProgBWConditional" "NONE";
BA_DEF_DEF_  "NmAsrMessage" "No";
BA_DEF_DEF_  "TpApplType" "";
BA_DEF_DEF_  "DiagState" "No";
BA_DEF_DEF_  "TpTxIndex" 0;
BA_DEF_DEF_  "DiagRequest" "No";
BA_DEF_DEF_  "DiagResponse" "No";
BA_DEF_DEF_  "GenMsgILSupport" "Yes";
BA_DEF_DEF_  "OvtpOperationMode" "SERVER";
BA_DEF_DEF_  "OvtpEcuAddress" 0;
BA_DEF_DEF_  "ILUsed" "Yes";
BA_DEF_DEF_  "Terminator" "No";
BA_DEF_DEF_  "NodeWakeUpTime" 10;
BA_DEF_DEF_  "NodeStartUpTime" 250;
BA_DEF_DEF_  "NmAsrNodeIdentifier" 128;
BA_DEF_DEF_  "NmAsrNode" "No";
BA_DEF_DEF_  "PowerType" "Switched";
BA_DEF_DEF_  "DiagNode" "GGDS";
BA_DEF_DEF_  "EOL_SB_Flash" "GGDS";
BA_DEF_DEF_  "NmStationAddress" 0;
BA_DEF_DEF_  "NosPackage" "I3_3";
BA_DEF_DEF_  "PackageID" "08.05.00.00.71.xx.xx.rr.00.00";
BA_DEF_DEF_  "GatewayECU" "No";
BA_DEF_DEF_  "NetworkSpeed" "500kBits/s";
BA_DEF_DEF_  "VersionNumber" 1;
BA_DEF_DEF_  "StarNetworkGwType" "0=NotDefined";
BA_DEF_DEF_  "CMDB_Version" "v11.01";
BA_DEF_DEF_  "NmType" "Ford-OSEK";
BA_DEF_DEF_  "NmAsrMessageCount" 128;
BA_DEF_DEF_  "NmAsrBaseAddress" 1408;
BA_DEF_DEF_  "DBName" "";
BA_DEF_DEF_  "VersionDay" 1;
BA_DEF_DEF_  "Manufacturer" "Ford";
BA_DEF_DEF_  "VersionMonth" 1;
BA_DEF_DEF_  "VersionYear" 2011;
BA_DEF_DEF_  "NmBaseAddress" 1280;
BA_DEF_DEF_  "NmMessageCount" 128;
BA_DEF_DEF_  "NodeLayerModules" "";
BA_ "VersionNumber" 7;
BA_ "StarNetworkGwType" 10;
BA_ "CMDB_Version" "FNV2_v19.07";
BA_ "VersionDay" 17;
BA_ "VersionMonth" 7;
BA_ "VersionYear" 2019;
BA_ "BusType" "CAN FD";
BA_ "DBName" "FD1_CAN";
BA_ "NosPackage" BU_ TCM 4;
BA_ "OvtpEcuAddress" BU_ TCM 24;
BA_ "NodeWakeUpTime" BU_ TCM 150;
BA_ "NodeStartUpTime" BU_ TCM 1000;
BA_ "NmAsrNodeIdentifier" BU_ TCM 160;
BA_ "NmAsrNode" BU_ TCM 1;
BA_ "PowerType" BU_ TCM 2;
BA_ "NmStationAddress" BU_ TCM 32;
BA_ "NodeLayerModules" BU_ TCM "CANoeILNLVector.dll";
BA_ "OvtpEcuAddress" BU_ HCM 113;
BA_ "NmStationAddress" BU_ HCM 55;
BA_ "NodeLayerModules" BU_ HCM "CANoeILNLVector.dll";
BA_ "OvtpEcuAddress" BU_ IPMA_ADAS 33;
BA_ "NodeStartUpTime" BU_ IPMA_ADAS 300;
BA_ "NmStationAddress" BU_ IPMA_ADAS 28;
BA_ "NodeLayerModules" BU_ IPMA_ADAS "CANoeILNLVector.dll";
BA_ "OvtpEcuAddress" BU_ PSCM 48;
BA_ "Terminator" BU_ PSCM 1;
BA_ "NmAsrNodeIdentifier" BU_ PSCM 181;
BA_ "NmAsrNode" BU_ PSCM 1;
BA_ "PowerType" BU_ PSCM 1;
BA_ "NmStationAddress" BU_ PSCM 53;
BA_ "NodeLayerModules" BU_ PSCM "CANoeILNLVector.dll";
BA_ "OvtpEcuAddress" BU_ ABS_ESC 40;
BA_ "NodeWakeUpTime" BU_ ABS_ESC 300;
BA_ "NodeStartUpTime" BU_ ABS_ESC 1000;
BA_ "NmAsrNodeIdentifier" BU_ ABS_ESC 150;
BA_ "NmAsrNode" BU_ ABS_ESC 1;
BA_ "PowerType" BU_ ABS_ESC 2;
BA_ "NmStationAddress" BU_ ABS_ESC 22;
BA_ "NodeLayerModules" BU_ ABS_ESC "CANoeILNLVector.dll";
BA_ "OvtpEcuAddress" BU_ TCCM 25;
BA_ "NodeWakeUpTime" BU_ TCCM 25;
BA_ "NodeStartUpTime" BU_ TCCM 1000;
BA_ "NmAsrNodeIdentifier" BU_ TCCM 161;
BA_ "NmAsrNode" BU_ TCCM 1;
BA_ "NmStationAddress" BU_ TCCM 33;
BA_ "NodeLayerModules" BU_ TCCM "CANoeILNLVector.dll";
BA_ "NosPackage" BU_ TCM_DSL 4;
BA_ "OvtpEcuAddress" BU_ TCM_DSL 24;
BA_ "NodeWakeUpTime" BU_ TCM_DSL 250;
BA_ "NmAsrNodeIdentifier" BU_ TCM_DSL 160;
BA_ "NmAsrNode" BU_ TCM_DSL 1;
BA_ "PowerType" BU_ TCM_DSL 1;
BA_ "NmStationAddress" BU_ TCM_DSL 32;
BA_ "NodeLayerModules" BU_ TCM_DSL "CANoeILNLVector.dll";
BA_ "OvtpEcuAddress" BU_ PCM_HEV 16;
BA_ "Terminator" BU_ PCM_HEV 1;
BA_ "NodeStartUpTime" BU_ PCM_HEV 350;
BA_ "NmAsrNodeIdentifier" BU_ PCM_HEV 149;
BA_ "NmAsrNode" BU_ PCM_HEV 1;
BA_ "PowerType" BU_ PCM_HEV 1;
BA_ "NmStationAddress" BU_ PCM_HEV 21;
BA_ "NodeLayerModules" BU_ PCM_HEV "CANoeILNLVector.dll";
BA_ "OvtpEcuAddress" BU_ PCM 16;
BA_ "Terminator" BU_ PCM 1;
BA_ "NodeStartUpTime" BU_ PCM 350;
BA_ "NmAsrNodeIdentifier" BU_ PCM 149;
BA_ "NmAsrNode" BU_ PCM 1;
BA_ "PowerType" BU_ PCM 1;
BA_ "NmStationAddress" BU_ PCM 21;
BA_ "NodeLayerModules" BU_ PCM "CANoeILNLVector.dll";
BA_ "OvtpEcuAddress" BU_ ECM_HEVDSL 16;
BA_ "Terminator" BU_ ECM_HEVDSL 1;
BA_ "NmAsrNodeIdentifier" BU_ ECM_HEVDSL 149;
BA_ "NmAsrNode" BU_ ECM_HEVDSL 1;
BA_ "PowerType" BU_ ECM_HEVDSL 1;
BA_ "NmStationAddress" BU_ ECM_HEVDSL 21;
BA_ "NodeLayerModules" BU_ ECM_HEVDSL "CANoeILNLVector.dll";
BA_ "OvtpEcuAddress" BU_ ECM_HEV 16;
BA_ "Terminator" BU_ ECM_HEV 1;
BA_ "NodeStartUpTime" BU_ ECM_HEV 350;
BA_ "NmAsrNodeIdentifier" BU_ ECM_HEV 149;
BA_ "NmAsrNode" BU_ ECM_HEV 1;
BA_ "PowerType" BU_ ECM_HEV 1;
BA_ "NmStationAddress" BU_ ECM_HEV 21;
BA_ "NodeLayerModules" BU_ ECM_HEV "CANoeILNLVector.dll";
BA_ "OvtpEcuAddress" BU_ ECM_Diesel 16;
BA_ "Terminator" BU_ ECM_Diesel 1;
BA_ "NmAsrNodeIdentifier" BU_ ECM_Diesel 149;
BA_ "NmAsrNode" BU_ ECM_Diesel 1;
BA_ "PowerType" BU_ ECM_Diesel 1;
BA_ "NmStationAddress" BU_ ECM_Diesel 21;
BA_ "NodeLayerModules" BU_ ECM_Diesel "CANoeILNLVector.dll";
BA_ "OvtpEcuAddress" BU_ ECM 16;
BA_ "Terminator" BU_ ECM 1;
BA_ "NodeStartUpTime" BU_ ECM 350;
BA_ "NmAsrNodeIdentifier" BU_ ECM 149;
BA_ "NmAsrNode" BU_ ECM 1;
BA_ "PowerType" BU_ ECM 1;
BA_ "NmStationAddress" BU_ ECM 21;
BA_ "NodeLayerModules" BU_ ECM "CANoeILNLVector.dll";
BA_ "OvtpEcuAddress" BU_ SIMA_DLCS 67;
BA_ "NmAsrNodeIdentifier" BU_ SIMA_DLCS 247;
BA_ "NmAsrNode" BU_ SIMA_DLCS 1;
BA_ "PowerType" BU_ SIMA_DLCS 2;
BA_ "NmStationAddress" BU_ SIMA_DLCS 247;
BA_ "NodeLayerModules" BU_ SIMA_DLCS "CANoeILNLVector.dll";
BA_ "OvtpEcuAddress" BU_ BCMD_IPDB 85;
BA_ "NmAsrNodeIdentifier" BU_ BCMD_IPDB 175;
BA_ "NmAsrNode" BU_ BCMD_IPDB 1;
BA_ "PowerType" BU_ BCMD_IPDB 2;
BA_ "NmStationAddress" BU_ BCMD_IPDB 47;
BA_ "NodeLayerModules" BU_ BCMD_IPDB "CANoeILNLVector.dll";
BA_ "OvtpEcuAddress" BU_ VDM 32;
BA_ "NmAsrNodeIdentifier" BU_ VDM 176;
BA_ "NmAsrNode" BU_ VDM 1;
BA_ "PowerType" BU_ VDM 2;
BA_ "NmStationAddress" BU_ VDM 48;
BA_ "NodeLayerModules" BU_ VDM "CANoeILNLVector.dll";
BA_ "OvtpEcuAddress" BU_ CMR_DSMC 187;
BA_ "NmAsrNodeIdentifier" BU_ CMR_DSMC 223;
BA_ "NmAsrNode" BU_ CMR_DSMC 1;
BA_ "PowerType" BU_ CMR_DSMC 2;
BA_ "NmStationAddress" BU_ CMR_DSMC 95;
BA_ "NodeLayerModules" BU_ CMR_DSMC "CANoeILNLVector.dll";
BA_ "OvtpEcuAddress" BU_ SOBDMC_HPCM_FD1 17;
BA_ "NmAsrNodeIdentifier" BU_ SOBDMC_HPCM_FD1 165;
BA_ "PowerType" BU_ SOBDMC_HPCM_FD1 1;
BA_ "NmStationAddress" BU_ SOBDMC_HPCM_FD1 37;
BA_ "NodeLayerModules" BU_ SOBDMC_HPCM_FD1 "CANoeILNLVector.dll";
BA_ "OvtpEcuAddress" BU_ CHCM 46;
BA_ "NmAsrNodeIdentifier" BU_ CHCM 243;
BA_ "NmAsrNode" BU_ CHCM 1;
BA_ "PowerType" BU_ CHCM 1;
BA_ "NmStationAddress" BU_ CHCM 115;
BA_ "NodeLayerModules" BU_ CHCM "CANoeILNLVector.dll";
BA_ "NosPackage" BU_ GWM 4;
BA_ "GatewayECU" BU_ GWM 1;
BA_ "OvtpOperationMode" BU_ GWM 1;
BA_ "OvtpEcuAddress" BU_ GWM 216;
BA_ "Terminator" BU_ GWM 1;
BA_ "NodeStartUpTime" BU_ GWM 100;
BA_ "NmAsrNodeIdentifier" BU_ GWM 158;
BA_ "NmAsrNode" BU_ GWM 1;
BA_ "PowerType" BU_ GWM 2;
BA_ "NmStationAddress" BU_ GWM 30;
BA_ "NodeLayerModules" BU_ GWM "CANoeILNLVector.dll";
BA_ "NodeLayerModules" BU_ _delete "CANoeILNLVector.dll";
BA_ "OvtpEcuAddress" BU_ AWD_DLCM 30;
BA_ "NmAsrNodeIdentifier" BU_ AWD_DLCM 240;
BA_ "NmAsrNode" BU_ AWD_DLCM 1;
BA_ "PowerType" BU_ AWD_DLCM 1;
BA_ "NmStationAddress" BU_ AWD_DLCM 112;
BA_ "NodeLayerModules" BU_ AWD_DLCM "CANoeILNLVector.dll";
BA_ "NodeLayerModules" BU_ GENERIC "CANoeILNLVector.dll";
BA_ "NodeLayerModules" BU_ TSTR "CANoeILNLVector.dll";
BA_ "GenMsgCycleTime" BO_ 1660 20;
BA_ "GenMsgSendType" BO_ 1660 0;
BA_ "VFrameFormat" BO_ 1660 14;
BA_ "GenMsgCycleTime" BO_ 1659 20;
BA_ "GenMsgSendType" BO_ 1659 0;
BA_ "VFrameFormat" BO_ 1659 14;
BA_ "GenMsgCycleTime" BO_ 1658 20;
BA_ "GenMsgSendType" BO_ 1658 0;
BA_ "VFrameFormat" BO_ 1658 14;
BA_ "GenMsgCycleTime" BO_ 1657 20;
BA_ "GenMsgSendType" BO_ 1657 0;
BA_ "VFrameFormat" BO_ 1657 14;
BA_ "GenMsgCycleTime" BO_ 1656 20;
BA_ "GenMsgSendType" BO_ 1656 0;
BA_ "VFrameFormat" BO_ 1656 14;
BA_ "GenMsgCycleTime" BO_ 1655 20;
BA_ "GenMsgSendType" BO_ 1655 0;
BA_ "VFrameFormat" BO_ 1655 14;
BA_ "GenMsgCycleTime" BO_ 1654 20;
BA_ "GenMsgSendType" BO_ 1654 0;
BA_ "VFrameFormat" BO_ 1654 14;
BA_ "GenMsgCycleTime" BO_ 1653 20;
BA_ "GenMsgSendType" BO_ 1653 0;
BA_ "VFrameFormat" BO_ 1653 14;
BA_ "GenMsgCycleTime" BO_ 1652 20;
BA_ "GenMsgSendType" BO_ 1652 0;
BA_ "VFrameFormat" BO_ 1652 14;
BA_ "GenMsgCycleTime" BO_ 1651 20;
BA_ "GenMsgSendType" BO_ 1651 0;
BA_ "VFrameFormat" BO_ 1651 14;
BA_ "GenMsgCycleTime" BO_ 1577 20;
BA_ "GenMsgSendType" BO_ 1577 0;
BA_ "VFrameFormat" BO_ 1577 14;
BA_ "GenMsgCycleTime" BO_ 1576 20;
BA_ "GenMsgSendType" BO_ 1576 0;
BA_ "VFrameFormat" BO_ 1576 14;
BA_ "GenMsgCycleTime" BO_ 1575 20;
BA_ "GenMsgSendType" BO_ 1575 0;
BA_ "VFrameFormat" BO_ 1575 14;
BA_ "GenMsgCycleTime" BO_ 1574 20;
BA_ "GenMsgSendType" BO_ 1574 0;
BA_ "VFrameFormat" BO_ 1574 14;
BA_ "GenMsgCycleTime" BO_ 1573 20;
BA_ "GenMsgSendType" BO_ 1573 0;
BA_ "VFrameFormat" BO_ 1573 14;
BA_ "GenMsgCycleTime" BO_ 1572 20;
BA_ "GenMsgSendType" BO_ 1572 0;
BA_ "VFrameFormat" BO_ 1572 14;
BA_ "GenMsgCycleTime" BO_ 1571 20;
BA_ "GenMsgSendType" BO_ 1571 0;
BA_ "VFrameFormat" BO_ 1571 14;
BA_ "GenMsgCycleTime" BO_ 1570 20;
BA_ "GenMsgSendType" BO_ 1570 0;
BA_ "VFrameFormat" BO_ 1570 14;
BA_ "GenMsgCycleTime" BO_ 1569 20;
BA_ "GenMsgSendType" BO_ 1569 0;
BA_ "VFrameFormat" BO_ 1569 14;
BA_ "GenMsgCycleTime" BO_ 1568 20;
BA_ "GenMsgSendType" BO_ 1568 0;
BA_ "VFrameFormat" BO_ 1568 14;
BA_ "GenMsgCycleTime" BO_ 1567 20;
BA_ "GenMsgSendType" BO_ 1567 0;
BA_ "VFrameFormat" BO_ 1567 14;
BA_ "GenMsgCycleTime" BO_ 1566 20;
BA_ "GenMsgSendType" BO_ 1566 0;
BA_ "VFrameFormat" BO_ 1566 14;
BA_ "GenMsgCycleTime" BO_ 1543 20;
BA_ "GenMsgSendType" BO_ 1543 0;
BA_ "VFrameFormat" BO_ 1543 14;
BA_ "GenMsgCycleTime" BO_ 1542 20;
BA_ "GenMsgSendType" BO_ 1542 0;
BA_ "VFrameFormat" BO_ 1542 14;
BA_ "GenMsgCycleTime" BO_ 1541 20;
BA_ "GenMsgSendType" BO_ 1541 0;
BA_ "VFrameFormat" BO_ 1541 14;
BA_ "GenMsgCycleTime" BO_ 1540 20;
BA_ "GenMsgSendType" BO_ 1540 0;
BA_ "VFrameFormat" BO_ 1540 14;
BA_ "GenMsgCycleTime" BO_ 1539 20;
BA_ "GenMsgSendType" BO_ 1539 0;
BA_ "VFrameFormat" BO_ 1539 14;
BA_ "GenMsgCycleTime" BO_ 1538 20;
BA_ "GenMsgSendType" BO_ 1538 0;
BA_ "VFrameFormat" BO_ 1538 14;
BA_ "NetworkInitialization" BO_ 1822 0;
BA_ "GenMsgDelayTime" BO_ 1822 0;
BA_ "GenMsgSendType" BO_ 1822 1;
BA_ "DiagResponse" BO_ 1822 1;
BA_ "GenMsgILSupport" BO_ 1822 0;
BA_ "VFrameFormat" BO_ 1822 14;
BA_ "NetworkInitialization" BO_ 1438 0;
BA_ "GenMsgCycleTime" BO_ 1438 1000;
BA_ "GenMsgSendType" BO_ 1438 0;
BA_ "NmAsrMessage" BO_ 1438 1;
BA_ "GenMsgILSupport" BO_ 1438 0;
BA_ "VFrameFormat" BO_ 1438 14;
BA_ "GenMsgSendType" BO_ 1116 5;
BA_ "GenMsgCycleTime" BO_ 1116 1000;
BA_ "FrameRouting" BO_ 1116 "*";
BA_ "FrameGatewayNetwork" BO_ 1116 "HS3_CAN";
BA_ "FrameGatewayId" BO_ 1116 1116;
BA_ "VFrameFormat" BO_ 1116 14;
BA_ "NetworkInitialization" BO_ 1844 0;
BA_ "GenMsgDelayTime" BO_ 1844 0;
BA_ "GenMsgSendType" BO_ 1844 1;
BA_ "DiagRequest" BO_ 1844 1;
BA_ "GenMsgILSupport" BO_ 1844 0;
BA_ "VFrameFormat" BO_ 1844 14;
BA_ "FrameRouting" BO_ 954 "HS1_CAN,0x3BA;";
BA_ "FrameGatewayNetwork" BO_ 954 "HS1_CAN";
BA_ "FrameGatewayId" BO_ 954 954;
BA_ "VFrameFormat" BO_ 954 14;
BA_ "NetworkInitialization" BO_ 1852 0;
BA_ "GenMsgDelayTime" BO_ 1852 0;
BA_ "GenMsgSendType" BO_ 1852 1;
BA_ "DiagResponse" BO_ 1852 1;
BA_ "GenMsgILSupport" BO_ 1852 0;
BA_ "VFrameFormat" BO_ 1852 14;
BA_ "GenMsgCycleTime" BO_ 989 1000;
BA_ "GenMsgSendType" BO_ 989 5;
BA_ "VFrameFormat" BO_ 989 14;
BA_ "FrameRouting" BO_ 874 "HS1_CAN,0x36A;";
BA_ "FrameGatewayNetwork" BO_ 874 "HS1_CAN";
BA_ "FrameGatewayId" BO_ 874 874;
BA_ "VFrameFormat" BO_ 874 14;
BA_ "GenMsgSendType" BO_ 551 5;
BA_ "GenMsgCycleTime" BO_ 551 1000;
BA_ "FrameRouting" BO_ 551 "*";
BA_ "FrameGatewayNetwork" BO_ 551 "HS3_CAN";
BA_ "FrameGatewayId" BO_ 551 551;
BA_ "VFrameFormat" BO_ 551 14;
BA_ "FrameRouting" BO_ 132 "*";
BA_ "FrameGatewayNetwork" BO_ 132 "HS1_CAN";
BA_ "FrameGatewayId" BO_ 132 132;
BA_ "VFrameFormat" BO_ 132 14;
BA_ "GenMsgCycleTime" BO_ 1006 1000;
BA_ "GenMsgSendType" BO_ 1006 5;
BA_ "VFrameFormat" BO_ 1006 14;
BA_ "FrameRouting" BO_ 1123 "*";
BA_ "FrameGatewayNetwork" BO_ 1123 "HS3_CAN";
BA_ "FrameGatewayId" BO_ 1123 1123;
BA_ "GenMsgCycleTime" BO_ 1123 500;
BA_ "GenMsgSendType" BO_ 1123 0;
BA_ "VFrameFormat" BO_ 1123 14;
BA_ "FrameRouting" BO_ 1122 "*";
BA_ "FrameGatewayNetwork" BO_ 1122 "HS3_CAN";
BA_ "FrameGatewayId" BO_ 1122 1122;
BA_ "GenMsgCycleTime" BO_ 1122 500;
BA_ "GenMsgSendType" BO_ 1122 0;
BA_ "VFrameFormat" BO_ 1122 14;
BA_ "GenMsgSendType" BO_ 1003 5;
BA_ "GenMsgCycleTime" BO_ 1003 1000;
BA_ "FrameRouting" BO_ 1003 "*";
BA_ "FrameGatewayNetwork" BO_ 1003 "HS1_CAN";
BA_ "FrameGatewayId" BO_ 1003 1003;
BA_ "VFrameFormat" BO_ 1003 14;
BA_ "GenMsgSendType" BO_ 994 5;
BA_ "GenMsgCycleTime" BO_ 994 1000;
BA_ "FrameRouting" BO_ 994 "*";
BA_ "FrameGatewayNetwork" BO_ 994 "HS3_CAN";
BA_ "FrameGatewayId" BO_ 994 994;
BA_ "VFrameFormat" BO_ 994 14;
BA_ "ECGUsedTxSignal" SG_ 1822 TesterPhysicalResGWM_F1 1;
BA_ "GenSigSendType" SG_ 1822 TesterPhysicalResGWM_F1 3;
BA_ "ECGUsedTxSignal" SG_ 1438 GWM_GWOnBoardTester 1;
BA_ "U_U55X_MY2022_Rx" SG_ 1438 GWM_GWOnBoardTester 1;
BA_ "U_CD542_MY2021_Rx" SG_ 1438 GWM_GWOnBoardTester 1;
BA_ "U_P702_MY2021_Rx" SG_ 1438 GWM_GWOnBoardTester 1;
BA_ "U_T6_MCA_MY2020_Rx" SG_ 1438 GWM_GWOnBoardTester 1;
BA_ "GenSigStartValue" SG_ 1438 GWM_GWOnBoardTester 255;
BA_ "ContentDependant" SG_ 1438 GWM_GWOnBoardTester 1;
BA_ "GenSigStartValueInteger" SG_ 1438 GWM_GWOnBoardTester 255;
BA_ "ECGUsedTxSignal" SG_ 1438 GWM_GWNMProxy 1;
BA_ "U_U55X_MY2022_Rx" SG_ 1438 GWM_GWNMProxy 1;
BA_ "U_CD542_MY2021_Rx" SG_ 1438 GWM_GWNMProxy 1;
BA_ "U_P702_MY2021_Rx" SG_ 1438 GWM_GWNMProxy 1;
BA_ "U_T6_MCA_MY2020_Rx" SG_ 1438 GWM_GWNMProxy 1;
BA_ "GenSigStartValue" SG_ 1438 GWM_GWNMProxy 255;
BA_ "ContentDependant" SG_ 1438 GWM_GWNMProxy 1;
BA_ "GenSigStartValueInteger" SG_ 1438 GWM_GWNMProxy 255;
BA_ "ECGUsedTxSignal" SG_ 1438 GWM_AutoSarNMReserved4 1;
BA_ "U_U55X_MY2022_Rx" SG_ 1438 GWM_AutoSarNMReserved4 1;
BA_ "U_CD542_MY2021_Rx" SG_ 1438 GWM_AutoSarNMReserved4 1;
BA_ "U_P702_MY2021_Rx" SG_ 1438 GWM_AutoSarNMReserved4 1;
BA_ "U_T6_MCA_MY2020_Rx" SG_ 1438 GWM_AutoSarNMReserved4 1;
BA_ "GenSigStartValue" SG_ 1438 GWM_AutoSarNMReserved4 255;
BA_ "ContentDependant" SG_ 1438 GWM_AutoSarNMReserved4 1;
BA_ "GenSigStartValueInteger" SG_ 1438 GWM_AutoSarNMReserved4 255;
BA_ "ECGUsedTxSignal" SG_ 1438 GWM_AutoSarNMReserved3 1;
BA_ "U_U55X_MY2022_Rx" SG_ 1438 GWM_AutoSarNMReserved3 1;
BA_ "U_CD542_MY2021_Rx" SG_ 1438 GWM_AutoSarNMReserved3 1;
BA_ "U_P702_MY2021_Rx" SG_ 1438 GWM_AutoSarNMReserved3 1;
BA_ "U_T6_MCA_MY2020_Rx" SG_ 1438 GWM_AutoSarNMReserved3 1;
BA_ "GenSigStartValue" SG_ 1438 GWM_AutoSarNMReserved3 255;
BA_ "ContentDependant" SG_ 1438 GWM_AutoSarNMReserved3 1;
BA_ "GenSigStartValueInteger" SG_ 1438 GWM_AutoSarNMReserved3 255;
BA_ "ECGUsedTxSignal" SG_ 1438 GWM_AutoSarNMReserved2 1;
BA_ "U_U55X_MY2022_Rx" SG_ 1438 GWM_AutoSarNMReserved2 1;
BA_ "U_CD542_MY2021_Rx" SG_ 1438 GWM_AutoSarNMReserved2 1;
BA_ "U_P702_MY2021_Rx" SG_ 1438 GWM_AutoSarNMReserved2 1;
BA_ "U_T6_MCA_MY2020_Rx" SG_ 1438 GWM_AutoSarNMReserved2 1;
BA_ "GenSigStartValue" SG_ 1438 GWM_AutoSarNMReserved2 255;
BA_ "ContentDependant" SG_ 1438 GWM_AutoSarNMReserved2 1;
BA_ "GenSigStartValueInteger" SG_ 1438 GWM_AutoSarNMReserved2 255;
BA_ "ECGUsedTxSignal" SG_ 1438 GWM_AutoSarNMReserved1 1;
BA_ "U_U55X_MY2022_Rx" SG_ 1438 GWM_AutoSarNMReserved1 1;
BA_ "U_CD542_MY2021_Rx" SG_ 1438 GWM_AutoSarNMReserved1 1;
BA_ "U_P702_MY2021_Rx" SG_ 1438 GWM_AutoSarNMReserved1 1;
BA_ "U_T6_MCA_MY2020_Rx" SG_ 1438 GWM_AutoSarNMReserved1 1;
BA_ "GenSigStartValue" SG_ 1438 GWM_AutoSarNMReserved1 255;
BA_ "ContentDependant" SG_ 1438 GWM_AutoSarNMReserved1 1;
BA_ "GenSigStartValueInteger" SG_ 1438 GWM_AutoSarNMReserved1 255;
BA_ "ECGUsedTxSignal" SG_ 1438 GWM_AutoSarNMNodeId 1;
BA_ "U_U55X_MY2022_Rx" SG_ 1438 GWM_AutoSarNMNodeId 1;
BA_ "U_CD542_MY2021_Rx" SG_ 1438 GWM_AutoSarNMNodeId 1;
BA_ "U_P702_MY2021_Rx" SG_ 1438 GWM_AutoSarNMNodeId 1;
BA_ "U_T6_MCA_MY2020_Rx" SG_ 1438 GWM_AutoSarNMNodeId 1;
BA_ "GenSigStartValue" SG_ 1438 GWM_AutoSarNMNodeId 158;
BA_ "ContentDependant" SG_ 1438 GWM_AutoSarNMNodeId 1;
BA_ "GenSigStartValueInteger" SG_ 1438 GWM_AutoSarNMNodeId 158;
BA_ "ECGUsedTxSignal" SG_ 1438 GWM_AutoSarNMControl 1;
BA_ "U_U55X_MY2022_Rx" SG_ 1438 GWM_AutoSarNMControl 1;
BA_ "U_CD542_MY2021_Rx" SG_ 1438 GWM_AutoSarNMControl 1;
BA_ "U_P702_MY2021_Rx" SG_ 1438 GWM_AutoSarNMControl 1;
BA_ "U_T6_MCA_MY2020_Rx" SG_ 1438 GWM_AutoSarNMControl 1;
BA_ "ContentDependant" SG_ 1438 GWM_AutoSarNMControl 1;
BA_ "U_CD542_MY2021_Rx" SG_ 1116 TrlrAidSetup_D2_Rq 1;
BA_ "U_T6_MCA_MY2020_Rx" SG_ 1116 TrlrAidSetup_D2_Rq 1;
BA_ "U_P702_MY2021_Rx" SG_ 1116 TrlrAidSetup_D2_Rq 1;
BA_ "U_P702_MY2021_Rx" SG_ 1116 TrlrAidEnbl_D2_Rq 1;
BA_ "U_CD542_MY2021_Rx" SG_ 1116 TrlrAidEnbl_D2_Rq 1;
BA_ "U_T6_MCA_MY2020_Rx" SG_ 1116 TrlrAidEnbl_D2_Rq 1;
BA_ "U_CD542_MY2021_Rx" SG_ 1116 TrlrTrgtToBmpr_L_Actl 1;
BA_ "U_T6_MCA_MY2020_Rx" SG_ 1116 TrlrTrgtToBmpr_L_Actl 1;
BA_ "U_CD542_MY2021_Rx" SG_ 1116 TrlrTrgtPtrnId_No_Mem 1;
BA_ "U_T6_MCA_MY2020_Rx" SG_ 1116 TrlrTrgtPtrnId_No_Mem 1;
BA_ "U_CD542_MY2021_Rx" SG_ 1116 TrlrRvrseCancl_B_Rq 1;
BA_ "U_T6_MCA_MY2020_Rx" SG_ 1116 TrlrRvrseCancl_B_Rq 1;
BA_ "U_CD542_MY2021_Rx" SG_ 1116 TrlrIdType_D_Stat 1;
BA_ "U_T6_MCA_MY2020_Rx" SG_ 1116 TrlrIdType_D_Stat 1;
BA_ "U_CD542_MY2021_Rx" SG_ 1116 TrlrId_No_Actl 1;
BA_ "U_T6_MCA_MY2020_Rx" SG_ 1116 TrlrId_No_Actl 1;
BA_ "U_CD542_MY2021_Rx" SG_ 1116 TrlrBallToBmpr_L_Actl 1;
BA_ "U_T6_MCA_MY2020_Rx" SG_ 1116 TrlrBallToBmpr_L_Actl 1;
BA_ "U_CD542_MY2021_Rx" SG_ 1116 TrlrAxleToBmpr_L_Actl 1;
BA_ "U_T6_MCA_MY2020_Rx" SG_ 1116 TrlrAxleToBmpr_L_Actl 1;
BA_ "U_CD542_MY2021_Rx" SG_ 1116 TrlrAnOffstDir_D_Mem 1;
BA_ "U_T6_MCA_MY2020_Rx" SG_ 1116 TrlrAnOffstDir_D_Mem 1;
BA_ "U_CD542_MY2021_Rx" SG_ 1116 TrlrAnOffst_An_Mem 1;
BA_ "U_T6_MCA_MY2020_Rx" SG_ 1116 TrlrAnOffst_An_Mem 1;
BA_ "U_CD542_MY2021_Rx" SG_ 1116 TrlrTrgtOffst_L_Actl 1;
BA_ "U_T6_MCA_MY2020_Rx" SG_ 1116 TrlrTrgtOffst_L_Actl 1;
BA_ "U_P702_MY2021_Rx" SG_ 1844 TesterPhysicalReqHCM 1;
BA_ "U_CX727_MY2021_Rx" SG_ 1844 TesterPhysicalReqHCM 1;
BA_ "GenSigSendType" SG_ 1844 TesterPhysicalReqHCM 3;
BA_ "U_T6_MCA_MY2020_Rx" SG_ 954 VehWlcmFrwlMde_D_Stat 1;
BA_ "WakeupSignal" SG_ 954 VehWlcmFrwlMde_D_Stat 1;
BA_ "U_P702_MY2021_Rx" SG_ 954 GenericSwtch3_No_Actl 1;
BA_ "U_CX727_MY2021_Rx" SG_ 954 GenericSwtch3_No_Actl 1;
BA_ "U_P702_MY2021_Rx" SG_ 954 GenericSwtch2_No_Actl 1;
BA_ "U_CX727_MY2021_Rx" SG_ 954 GenericSwtch2_No_Actl 1;
BA_ "ContentDependant" SG_ 954 GenericSwtch2_No_Actl 1;
BA_ "U_P702_MY2021_Rx" SG_ 954 GenericSwtch1_No_Actl 1;
BA_ "U_CX727_MY2021_Rx" SG_ 954 GenericSwtch1_No_Actl 1;
BA_ "WakeupSignal" SG_ 954 PudSptLghtRight_D_Rq 1;
BA_ "WakeupSignal" SG_ 954 PudSptLghtLeft_D_Rq 1;
BA_ "WakeupSignal" SG_ 954 ExtLghtRight_D_Stat 1;
BA_ "WakeupSignal" SG_ 954 ExtLghtRear_D_Stat 1;
BA_ "WakeupSignal" SG_ 954 ExtLghtLeft_D_Stat 1;
BA_ "WakeupSignal" SG_ 954 ExtLghtFront_D_Stat 1;
BA_ "WakeupSignal" SG_ 954 LghtAmbDrvMde_B_Stat 1;
BA_ "WakeupSignal" SG_ 954 PwRnngBoardPoll_D_Stat 1;
BA_ "WakeupSignal" SG_ 954 TrlrHitchLamp_D_Stat 1;
BA_ "WakeupSignal" SG_ 954 TrukBedLght_B_Stat 1;
BA_ "U_T6_MCA_MY2020_Rx" SG_ 954 VehWlcmFrwl_D_Stat 1;
BA_ "WakeupSignal" SG_ 954 VehWlcmFrwl_D_Stat 1;
BA_ "WakeupSignal" SG_ 954 ExtLghtAlrt_B_Rq 1;
BA_ "WakeupSignal" SG_ 954 ExtLght_D_Falt 1;
BA_ "U_P702_MY2021_Tx" SG_ 1852 TesterPhysicalResHCM 1;
BA_ "U_CX727_MY2021_Tx" SG_ 1852 TesterPhysicalResHCM 1;
BA_ "GenSigSendType" SG_ 1852 TesterPhysicalResHCM 3;
BA_ "U_P702_MY2021_Tx" SG_ 989 FeatNoHcm_No_Actl 1;
BA_ "U_CX727_MY2021_Tx" SG_ 989 FeatNoHcm_No_Actl 1;
BA_ "GenSigSendType" SG_ 989 FeatNoHcm_No_Actl 3;
BA_ "U_P702_MY2021_Tx" SG_ 989 FeatConfigHcmActl 1;
BA_ "U_CX727_MY2021_Tx" SG_ 989 FeatConfigHcmActl 1;
BA_ "GenSigSendType" SG_ 989 FeatConfigHcmActl 3;
BA_ "U_T6_MCA_MY2020_Rx" SG_ 874 AirCondCluOpen_D_Falt 1;
BA_ "U_T6_MCA_MY2020_Rx" SG_ 874 AirCondCluLife_D_Falt 1;
BA_ "U_T6_MCA_MY2020_Rx" SG_ 874 AirCondCluGnd_D_Falt 1;
BA_ "U_T6_MCA_MY2020_Rx" SG_ 874 AirCondClu_D_Stat 1;
BA_ "U_T6_MCA_MY2020_Rx" SG_ 874 AirCondCluBatt_D_Falt 1;
BA_ "U_CD542_MY2021_Rx" SG_ 874 BattTracShrtGrnd_D_Falt 1;
BA_ "U_P702_MY2021_Rx" SG_ 874 BattTracShrtGrnd_D_Falt 1;
BA_ "U_CX727_MY2021_Rx" SG_ 874 BattTracShrtGrnd_D_Falt 1;
BA_ "U_CD542_MY2021_Rx" SG_ 874 BattTracShrtBatt_D_Falt 1;
BA_ "U_P702_MY2021_Rx" SG_ 874 BattTracShrtBatt_D_Falt 1;
BA_ "U_CX727_MY2021_Rx" SG_ 874 BattTracShrtBatt_D_Falt 1;
BA_ "U_CD542_MY2021_Rx" SG_ 874 BattTracOpnCirct_D_Falt 1;
BA_ "U_P702_MY2021_Rx" SG_ 874 BattTracOpnCirct_D_Falt 1;
BA_ "U_CX727_MY2021_Rx" SG_ 874 BattTracOpnCirct_D_Falt 1;
BA_ "U_CD542_MY2021_Rx" SG_ 874 BattTracLifeLim_D_Falt 1;
BA_ "U_CX727_MY2021_Rx" SG_ 874 BattTracLifeLim_D_Falt 1;
BA_ "U_CD542_MY2021_Rx" SG_ 874 BattChlrShrtGrnd_D_Falt 1;
BA_ "U_P702_MY2021_Rx" SG_ 874 BattChlrShrtGrnd_D_Falt 1;
BA_ "U_CX727_MY2021_Rx" SG_ 874 BattChlrShrtGrnd_D_Falt 1;
BA_ "U_CD542_MY2021_Rx" SG_ 874 BattChlrShrtBatt_D_Falt 1;
BA_ "U_P702_MY2021_Rx" SG_ 874 BattChlrShrtBatt_D_Falt 1;
BA_ "U_CX727_MY2021_Rx" SG_ 874 BattChlrShrtBatt_D_Falt 1;
BA_ "U_CD542_MY2021_Rx" SG_ 874 BattChlrOpnCirct_D_Falt 1;
BA_ "U_P702_MY2021_Rx" SG_ 874 BattChlrOpnCirct_D_Falt 1;
BA_ "U_CX727_MY2021_Rx" SG_ 874 BattChlrOpnCirct_D_Falt 1;
BA_ "U_CD542_MY2021_Rx" SG_ 874 BattChlrLifeLim_D_Falt 1;
BA_ "U_CX727_MY2021_Rx" SG_ 874 BattTracLow_D_Falt 1;
BA_ "U_CD542_MY2021_Rx" SG_ 551 Rba_D_Rq 1;
BA_ "U_T6_MCA_MY2020_Rx" SG_ 551 Rba_D_Rq 1;
BA_ "WakeupSignal" SG_ 551 Em_D_Stat 1;
BA_ "GenSigStartValue" SG_ 551 ChrgToPcEdit_Pc_RqMnu 126;
BA_ "WakeupSignal" SG_ 551 Cntr_Plg_Mode_Cmd 1;
BA_ "GenSigStartValue" SG_ 551 Btt_L_Actl2 30;
BA_ "GenSigStartValueInteger" SG_ 551 Btt_L_Actl2 126;
BA_ "U_T6_MCA_MY2020_Rx" SG_ 132 GlblClkYr_No_Actl 1;
BA_ "U_CD542_MY2021_Rx" SG_ 132 GlblClkYr_No_Actl 1;
BA_ "U_P702_MY2021_Rx" SG_ 132 GlblClkYr_No_Actl 1;
BA_ "U_CX727_MY2021_Rx" SG_ 132 GlblClkYr_No_Actl 1;
BA_ "U_T6_MCA_MY2020_Rx" SG_ 132 GlblClkScnd_No_Actl 1;
BA_ "U_CD542_MY2021_Rx" SG_ 132 GlblClkScnd_No_Actl 1;
BA_ "U_P702_MY2021_Rx" SG_ 132 GlblClkScnd_No_Actl 1;
BA_ "U_CX727_MY2021_Rx" SG_ 132 GlblClkScnd_No_Actl 1;
BA_ "U_T6_MCA_MY2020_Rx" SG_ 132 GlblClkMnte_No_Actl 1;
BA_ "U_CD542_MY2021_Rx" SG_ 132 GlblClkMnte_No_Actl 1;
BA_ "U_P702_MY2021_Rx" SG_ 132 GlblClkMnte_No_Actl 1;
BA_ "U_CX727_MY2021_Rx" SG_ 132 GlblClkMnte_No_Actl 1;
BA_ "U_T6_MCA_MY2020_Rx" SG_ 132 GlblClkHr_No_Actl 1;
BA_ "U_CD542_MY2021_Rx" SG_ 132 GlblClkHr_No_Actl 1;
BA_ "U_P702_MY2021_Rx" SG_ 132 GlblClkHr_No_Actl 1;
BA_ "U_CX727_MY2021_Rx" SG_ 132 GlblClkHr_No_Actl 1;
BA_ "U_T6_MCA_MY2020_Rx" SG_ 132 GlblClkDay_No_Actl 1;
BA_ "U_CD542_MY2021_Rx" SG_ 132 GlblClkDay_No_Actl 1;
BA_ "U_P702_MY2021_Rx" SG_ 132 GlblClkDay_No_Actl 1;
BA_ "U_CX727_MY2021_Rx" SG_ 132 GlblClkDay_No_Actl 1;
BA_ "U_CD542_MY2021_Tx" SG_ 1006 PersIndexIpmb_D_Actl 1;
BA_ "U_T6_MCA_MY2020_Tx" SG_ 1006 PersIndexIpmb_D_Actl 1;
BA_ "GenSigSendType" SG_ 1006 PersIndexIpmb_D_Actl 3;
BA_ "GenSigStartValue" SG_ 1006 PersIndexIpmb_D_Actl 4;
BA_ "GenSigStartValueInteger" SG_ 1006 PersIndexIpmb_D_Actl 4;
BA_ "U_CD542_MY2021_Tx" SG_ 1006 FeatNoIpmbActl 1;
BA_ "U_T6_MCA_MY2020_Tx" SG_ 1006 FeatNoIpmbActl 1;
BA_ "GenSigSendType" SG_ 1006 FeatNoIpmbActl 3;
BA_ "U_CD542_MY2021_Tx" SG_ 1006 FeatConfigIpmbActl 1;
BA_ "U_T6_MCA_MY2020_Tx" SG_ 1006 FeatConfigIpmbActl 1;
BA_ "GenSigSendType" SG_ 1006 FeatConfigIpmbActl 3;
BA_ "U_CD542_MY2021_Rx" SG_ 1123 GpsUtcYr_No_Actl 1;
BA_ "U_T6_MCA_MY2020_Rx" SG_ 1123 GpsUtcYr_No_Actl 1;
BA_ "U_CD542_MY2021_Rx" SG_ 1123 GpsUtcMnth_No_Actl 1;
BA_ "U_T6_MCA_MY2020_Rx" SG_ 1123 GpsUtcMnth_No_Actl 1;
BA_ "GenSigStartValue" SG_ 1123 GpsUtcMnth_No_Actl 1;
BA_ "GenSigStartValueInteger" SG_ 1123 GpsUtcMnth_No_Actl 1;
BA_ "U_CD542_MY2021_Rx" SG_ 1123 GpsUtcDay_No_Actl 1;
BA_ "U_T6_MCA_MY2020_Rx" SG_ 1123 GpsUtcDay_No_Actl 1;
BA_ "GenSigStartValue" SG_ 1123 GpsUtcDay_No_Actl 1;
BA_ "GenSigStartValueInteger" SG_ 1123 GpsUtcDay_No_Actl 1;
BA_ "U_T6_MCA_MY2020_Rx" SG_ 1123 GPS_UTC_seconds 1;
BA_ "U_CD542_MY2021_Rx" SG_ 1123 GPS_UTC_seconds 1;
BA_ "U_P702_MY2021_Rx" SG_ 1123 GPS_UTC_seconds 1;
BA_ "U_CX727_MY2021_Rx" SG_ 1123 GPS_UTC_seconds 1;
BA_ "U_CD542_MY2021_Rx" SG_ 1123 GPS_UTC_minutes 1;
BA_ "U_T6_MCA_MY2020_Rx" SG_ 1123 GPS_UTC_minutes 1;
BA_ "U_CD542_MY2021_Rx" SG_ 1123 GPS_UTC_hours 1;
BA_ "U_T6_MCA_MY2020_Rx" SG_ 1123 GPS_UTC_hours 1;
BA_ "U_CD542_MY2021_Rx" SG_ 1123 GPS_Compass_direction 1;
BA_ "U_T6_MCA_MY2020_Rx" SG_ 1123 GPS_Compass_direction 1;
BA_ "U_T6_MCA_MY2020_Rx" SG_ 1123 GPS_Actual_vs_Infer_pos 1;
BA_ "U_CD542_MY2021_Rx" SG_ 1123 GPS_Actual_vs_Infer_pos 1;
BA_ "U_P702_MY2021_Rx" SG_ 1123 GPS_Actual_vs_Infer_pos 1;
BA_ "U_CX727_MY2021_Rx" SG_ 1123 GPS_Actual_vs_Infer_pos 1;
BA_ "U_T6_MCA_MY2020_Rx" SG_ 1123 Gps_B_Falt 1;
BA_ "U_CD542_MY2021_Rx" SG_ 1123 Gps_B_Falt 1;
BA_ "U_P702_MY2021_Rx" SG_ 1123 Gps_B_Falt 1;
BA_ "U_CX727_MY2021_Rx" SG_ 1123 Gps_B_Falt 1;
BA_ "U_T6_MCA_MY2020_Rx" SG_ 1123 GPS_Pdop 1;
BA_ "U_T6_MCA_MY2020_Rx" SG_ 1122 GPS_Longitude_Minutes 1;
BA_ "U_CD542_MY2021_Rx" SG_ 1122 GPS_Longitude_Minutes 1;
BA_ "U_P702_MY2021_Rx" SG_ 1122 GPS_Longitude_Minutes 1;
BA_ "U_CX727_MY2021_Rx" SG_ 1122 GPS_Longitude_Minutes 1;
BA_ "U_T6_MCA_MY2020_Rx" SG_ 1122 GPS_Longitude_Min_dec 1;
BA_ "U_CD542_MY2021_Rx" SG_ 1122 GPS_Longitude_Min_dec 1;
BA_ "U_P702_MY2021_Rx" SG_ 1122 GPS_Longitude_Min_dec 1;
BA_ "U_CX727_MY2021_Rx" SG_ 1122 GPS_Longitude_Min_dec 1;
BA_ "U_T6_MCA_MY2020_Rx" SG_ 1122 GPS_Longitude_Degrees 1;
BA_ "U_CD542_MY2021_Rx" SG_ 1122 GPS_Longitude_Degrees 1;
BA_ "U_P702_MY2021_Rx" SG_ 1122 GPS_Longitude_Degrees 1;
BA_ "U_CX727_MY2021_Rx" SG_ 1122 GPS_Longitude_Degrees 1;
BA_ "GenSigStartValueInteger" SG_ 1122 GPS_Longitude_Degrees 179;
BA_ "U_T6_MCA_MY2020_Rx" SG_ 1122 GPS_Latitude_Minutes 1;
BA_ "U_CD542_MY2021_Rx" SG_ 1122 GPS_Latitude_Minutes 1;
BA_ "U_P702_MY2021_Rx" SG_ 1122 GPS_Latitude_Minutes 1;
BA_ "U_CX727_MY2021_Rx" SG_ 1122 GPS_Latitude_Minutes 1;
BA_ "U_T6_MCA_MY2020_Rx" SG_ 1122 GPS_Latitude_Min_dec 1;
BA_ "U_CD542_MY2021_Rx" SG_ 1122 GPS_Latitude_Min_dec 1;
BA_ "U_P702_MY2021_Rx" SG_ 1122 GPS_Latitude_Min_dec 1;
BA_ "U_CX727_MY2021_Rx" SG_ 1122 GPS_Latitude_Min_dec 1;
BA_ "U_T6_MCA_MY2020_Rx" SG_ 1122 GPS_Latitude_Degrees 1;
BA_ "U_CD542_MY2021_Rx" SG_ 1122 GPS_Latitude_Degrees 1;
BA_ "U_P702_MY2021_Rx" SG_ 1122 GPS_Latitude_Degrees 1;
BA_ "U_CX727_MY2021_Rx" SG_ 1122 GPS_Latitude_Degrees 1;
BA_ "U_P702_MY2021_Rx" SG_ 1122 GpsHsphLongEast_D_Actl 1;
BA_ "U_CX727_MY2021_Rx" SG_ 1122 GpsHsphLongEast_D_Actl 1;
BA_ "U_CD542_MY2021_Rx" SG_ 1122 GpsHsphLongEast_D_Actl 1;
BA_ "U_T6_MCA_MY2020_Rx" SG_ 1122 GpsHsphLongEast_D_Actl 1;
BA_ "U_P702_MY2021_Rx" SG_ 1122 GpsHsphLattSth_D_Actl 1;
BA_ "U_CX727_MY2021_Rx" SG_ 1122 GpsHsphLattSth_D_Actl 1;
BA_ "U_CD542_MY2021_Rx" SG_ 1122 GpsHsphLattSth_D_Actl 1;
BA_ "U_T6_MCA_MY2020_Rx" SG_ 1122 GpsHsphLattSth_D_Actl 1;
BA_ "U_CD542_MY2021_Rx" SG_ 1003 VehKeyActv_D_Stat 1;
BA_ "U_CX727_MY2021_Rx" SG_ 1003 VehKeyActv_D_Stat 1;
BA_ "GenSigStartValue" SG_ 1003 PersNoPos_D_Actl 4;
BA_ "GenSigStartValueInteger" SG_ 1003 PersNoPos_D_Actl 4;
BA_ "U_CD542_MY2021_Rx" SG_ 1003 PersSetupRestr_D_Actl 1;
BA_ "U_CX727_MY2021_Rx" SG_ 1003 PersSetupRestr_D_Actl 1;
BA_ "U_CD542_MY2021_Rx" SG_ 1003 PersSetupAccessCtrl 1;
BA_ "U_CX727_MY2021_Rx" SG_ 1003 PersSetupAccessCtrl 1;
BA_ "U_CD542_MY2021_Rx" SG_ 1003 PersSetup_No_Actl 1;
BA_ "U_CX727_MY2021_Rx" SG_ 1003 PersSetup_No_Actl 1;
BA_ "GenSigStartValue" SG_ 1003 PersConflict_D_Actl 1;
BA_ "GenSigStartValueInteger" SG_ 1003 PersConflict_D_Actl 1;
BA_ "U_CD542_MY2021_Rx" SG_ 1003 RecallEvent_No_Cnt 1;
BA_ "U_T6_MCA_MY2020_Rx" SG_ 1003 RecallEvent_No_Cnt 1;
BA_ "MetaData" SG_ 1003 RecallEvent_No_Cnt 1;
BA_ "U_T6_MCA_MY2020_Rx" SG_ 1003 PersNo_D_Actl 1;
BA_ "U_CD542_MY2021_Rx" SG_ 1003 PersNo_D_Actl 1;
BA_ "U_CX727_MY2021_Rx" SG_ 1003 PersNo_D_Actl 1;
BA_ "GenSigStartValue" SG_ 1003 PersNo_D_Actl 4;
BA_ "GenSigStartValueInteger" SG_ 1003 PersNo_D_Actl 4;
BA_ "WakeupSignal" SG_ 994 Pers4OptIn_B_Stats 1;
BA_ "WakeupSignal" SG_ 994 Pers3OptIn_B_Stats 1;
BA_ "WakeupSignal" SG_ 994 Pers2OptIn_B_Stats 1;
BA_ "WakeupSignal" SG_ 994 Pers1OptIn_B_Stats 1;
BA_ "U_T6_MCA_MY2020_Rx" SG_ 994 CtrStkPersIndex_D_Actl 1;
BA_ "U_CD542_MY2021_Rx" SG_ 994 CtrStkPersIndex_D_Actl 1;
BA_ "U_CX727_MY2021_Rx" SG_ 994 CtrStkPersIndex_D_Actl 1;
BA_ "GenSigStartValue" SG_ 994 CtrStkPersIndex_D_Actl 4;
BA_ "GenSigStartValueInteger" SG_ 994 CtrStkPersIndex_D_Actl 4;
BA_ "U_T6_MCA_MY2020_Rx" SG_ 994 CtrStkFeatNoActl 1;
BA_ "U_CD542_MY2021_Rx" SG_ 994 CtrStkFeatNoActl 1;
BA_ "U_CX727_MY2021_Rx" SG_ 994 CtrStkFeatNoActl 1;
BA_ "U_T6_MCA_MY2020_Rx" SG_ 994 CtrStkFeatConfigActl 1;
BA_ "U_CD542_MY2021_Rx" SG_ 994 CtrStkFeatConfigActl 1;
BA_ "U_CX727_MY2021_Rx" SG_ 994 CtrStkFeatConfigActl 1;
BA_ "U_T6_MCA_MY2020_Rx" SG_ 994 CtrStkDsplyOp_D_Rq 1;
BA_ "U_CD542_MY2021_Rx" SG_ 994 CtrStkDsplyOp_D_Rq 1;
BA_ "U_CX727_MY2021_Rx" SG_ 994 CtrStkDsplyOp_D_Rq 1;
VAL_ 1116 TrlrAidSetup_D2_Rq 15 "NotUsed_9" 14 "NotUsed_8" 13 "NotUsed_7" 12 "NotUsed_6" 11 "NotUsed_5" 10 "NotUsed_4" 9 "NotUsed_3" 8 "NotUsed_2" 7 "NotUsed_1" 6 "CompleteSetup" 5 "ReturnToSetup" 4 "StickerNotCircled" 3 "ConfirmSetup" 2 "EndSetup" 1 "BeginSetup" 0 "Inactive" ;
VAL_ 1116 TrlrAidEnbl_D2_Rq 7 "NotUsed_4" 6 "NotUsed_3" 5 "NotUsed_2" 4 "NotUsed_1" 3 "Deactivate" 2 "ActivateTrg" 1 "ActivateTba" 0 "Inactive" ;
VAL_ 1116 TlightTest_D_Mnu 3 "TestEndAcknowledge" 2 "StartTest" 1 "StopTest" 0 "Null" ;
VAL_ 1116 TrlrRvrseCancl_B_Rq 1 "Cancel" 0 "Null" ;
VAL_ 1116 TrlrIdType_D_Stat 3 "Gooseneck" 2 "FifthWheel" 1 "Conventional" 0 "Null" ;
VAL_ 1116 TrlrAnOffstDir_D_Mem 3 "NotUSed" 2 "Right" 1 "Left_or_Center" 0 "Null" ;
VAL_ 954 VehWlcmFrwlMde_D_Stat 7 "IlluminatedExit" 6 "CourtesyLightingDelayExt" 5 "CourtesyLightingExtended" 4 "CourtesyLightingDelayAll" 3 "CourtesyLightingAll" 2 "IlluminatedEntry" 1 "Approach" 0 "Null" ;
VAL_ 954 PudSptLghtRight_D_Rq 3 "NotUsed" 2 "On" 1 "Off" 0 "Null" ;
VAL_ 954 PudSptLghtLeft_D_Rq 3 "NotUsed" 2 "On" 1 "Off" 0 "Null" ;
VAL_ 954 ExtLghtRight_D_Stat 3 "NotUsed" 2 "On" 1 "Off" 0 "Null" ;
VAL_ 954 ExtLghtRear_D_Stat 3 "NotUsed" 2 "On" 1 "Off" 0 "Null" ;
VAL_ 954 ExtLghtLeft_D_Stat 3 "NotUsed" 2 "On" 1 "Off" 0 "Null" ;
VAL_ 954 ExtLghtFront_D_Stat 3 "NotUsed" 2 "On" 1 "Off" 0 "Null" ;
VAL_ 954 TlghtTestLght_D_Stat 7 "Error" 6 "AllOff" 5 "TestingReverseLights" 4 "TestingBrakeLights" 3 "TestingLeftTurnSignal" 2 "TestingRightTurnSignal" 1 "ParkingLightsIlluminated" 0 "Null" ;
VAL_ 954 LghtAmbDrvMde_B_Stat 1 "Automatic" 0 "Manual" ;
VAL_ 954 KeylessIdl_B_Stat 1 "Pressed" 0 "Not_Pressed" ;
VAL_ 954 PwRnngBoardPoll_D_Stat 3 "NotUsed" 2 "PkPresent" 1 "PkNotPresent" 0 "NotPolling" ;
VAL_ 954 PoliceDmngLvl_D_Stat 7 "NotUsed" 6 "Off_Night" 5 "Off_Day" 4 "Low1Night" 3 "Low1Day" 2 "Inactive" 1 "Decommissioned" 0 "Null" ;
VAL_ 954 TrlrHitchLamp_D_Stat 1 "On" 0 "Off" ;
VAL_ 954 LicPlateLght_B_Stat 1 "On" 0 "Off" ;
VAL_ 954 TrukBedLght_B_Stat 1 "On" 0 "Off" ;
VAL_ 954 VehWlcmFrwl_D_Stat 3 "RunStart" 2 "Farewell" 1 "Welcome" 0 "Null" ;
VAL_ 954 TlghtTestPrecnd_D_Stat 7 "Error" 6 "NotStationary" 5 "InteractionPresent" 4 "PreconditionsPassed" 3 "BattSocLessThan75Percent" 2 "TailLightsOn" 1 "IgnitionNotOn" 0 "Null" ;
VAL_ 954 TlghtTest_D_Stat 3 "InProgress" 2 "Ended" 1 "Completed" 0 "Null" ;
VAL_ 954 ExtLghtAlrt_B_Rq 1 "Yes" 0 "No" ;
VAL_ 954 ExtLght_D_Falt 3 "Error" 2 "NoStationary" 1 "StartEngine" 0 "Null" ;
VAL_ 874 AirCondCluOpen_D_Falt 3 "NotUsed" 2 "Pass" 1 "Fail" 0 "Not_Diagnose_Yet" ;
VAL_ 874 AirCondCluLife_D_Falt 3 "NotUsed" 2 "Pass" 1 "Fail" 0 "Not_Diagnose_Yet" ;
VAL_ 874 AirCondCluGnd_D_Falt 3 "NotUsed" 2 "Pass" 1 "Fail" 0 "Not_Diagnose_Yet" ;
VAL_ 874 AirCondClu_D_Stat 7 "NotUsed" 6 "FetLifeLimitReached" 5 "FetOpenCircuit" 4 "FetOutputShortToPower" 3 "FetOutputShortToGround" 2 "FetNotControlled" 1 "OnPowerToLoad" 0 "OffNoPowerToLoad" ;
VAL_ 874 AirCondCluBatt_D_Falt 3 "NotUsed" 2 "Pass" 1 "Fail" 0 "Not_Diagnose_Yet" ;
VAL_ 874 BattTracShrtGrnd_D_Falt 3 "NotUsed" 2 "Pass" 1 "Fail" 0 "Not_Diagnose_Yet" ;
VAL_ 874 BattTracShrtBatt_D_Falt 3 "NotUsed" 2 "Pass" 1 "Fail" 0 "Not_Diagnose_Yet" ;
VAL_ 874 BattTracOpnCirct_D_Falt 3 "NotUsed" 2 "Pass" 1 "Fail" 0 "Not_Diagnose_Yet" ;
VAL_ 874 BattTracLifeLim_D_Falt 3 "NotUsed" 2 "Pass" 1 "Fail" 0 "Not_Diagnose_Yet" ;
VAL_ 874 BattChlrShrtGrnd_D_Falt 3 "NotUsed" 2 "Pass" 1 "Fail" 0 "Not_Diagnose_Yet" ;
VAL_ 874 BattChlrShrtBatt_D_Falt 3 "NotUsed" 2 "Pass" 1 "Fail" 0 "Not_Diagnose_Yet" ;
VAL_ 874 BattChlrOpnCirct_D_Falt 3 "NotUsed" 2 "Pass" 1 "Fail" 0 "Not_Diagnose_Yet" ;
VAL_ 874 BattChlrLifeLim_D_Falt 3 "NotUsed" 2 "Pass" 1 "Fail" 0 "Not_Diagnose_Yet" ;
VAL_ 874 BattTracLow_D_Falt 3 "NotUsed" 2 "Pass" 1 "Fail" 0 "Not_Diagnose_Yet" ;
VAL_ 551 Rba_D_Rq 3 "NotUsed" 2 "On" 1 "Off" 0 "Null" ;
VAL_ 551 EmPrflNo_D_Rq 7 "NotUsed_3" 6 "NotUsed_2" 5 "NotUsed_1" 4 "Pers4" 3 "Pers3" 2 "Pers2" 1 "Pers1" 0 "Null" ;
VAL_ 551 EmPrflButtnAssoc_D_Rq 3 "NotUsed" 2 "ExitButtonAssociation" 1 "EnterButtonAssociation" 0 "Null" ;
VAL_ 551 EmPrflKeyAssoc_D_Rq 7 "NotUsed_3" 6 "DisassociatePhone" 5 "EnterPhoneAssociation" 4 "OverwriteKey" 3 "DisassociateKey" 2 "ExitKeyAssociation" 1 "EnterKeyAssociation" 0 "Null" ;
VAL_ 551 Em_D_Stat 3 "NotSupported" 2 "ProfilesOff" 1 "ProfilesOn" 0 "Null" ;
VAL_ 551 ChrgOvrdExitScrn_D_Rq 3 "NotUsed_1" 2 "Request_override" 1 "Do_not_request_override" 0 "Inactive" ;
VAL_ 551 PrcondEdit_D_RqMnu 7 "NotUsed_3" 6 "NotUsed_2" 5 "NotUsed_1" 4 "High" 3 "Medium" 2 "Low" 1 "Off" 0 "Null" ;
VAL_ 551 ChrgToPcEdit_Pc_RqMnu 127 "Faulty" 126 "NoDataExists" ;
VAL_ 551 EcoIdl_D_Rq 3 "NotUsed" 2 "Enabled" 1 "Disabled" 0 "Null" ;
VAL_ 551 PmCabnLvl_D_Stat 7 "NotUsed_1" 6 "Level_6_Worst" 5 "Level_5" 4 "Level_4" 3 "Level_3" 2 "Level_2" 1 "Level_1_Best" 0 "NotKnown" ;
VAL_ 551 PmCabn_D_Stat 3 "FilteringComplete" 2 "FilteringOn" 1 "FilteringOff" 0 "NotKnown" ;
VAL_ 551 PwRnngBoardSwtch_D_Rq 3 "NotUsed" 2 "DeployUnlocked" 1 "AlwaysActive" 0 "Inactive" ;
VAL_ 551 PwRnngBoardMde_D_Rq 0 "Inactive" 1 "Off" 2 "Out" 3 "Auto" ;
VAL_ 551 PwRnngBoardT_D_Rq 3 "NotUsed" 2 "Timer2" 1 "Timer1" 0 "Inactive" ;
VAL_ 551 OneTEditActv_B_RqMnu 1 "Yes" 0 "No" ;
VAL_ 551 Cntr_Plg_Mode_Cmd 1 "Enable" 0 "Disable" ;
VAL_ 551 BattTracLoThres_D_Rq 7 "NotUsed" 6 "Thres80km_50mi" 5 "Thres50km_31mi" 4 "Thres30km_18mi" 3 "Thres50mi_80km" 2 "Thres30mi_48km" 1 "Thres20mi_32km" 0 "Null" ;
VAL_ 551 ChrgCrdLckEnbl_B_Stat 1 "Enable" 0 "Disable" ;
VAL_ 551 Btt_L_Actl2 127 "Faulty" 126 "NoDataExists" ;
VAL_ 1006 PersIndexIpmb_D_Actl 7 "Unused_3" 6 "Unused_2" 5 "Unused_1" 4 "Vehicle" 3 "PERS_4" 2 "PERS_3" 1 "PERS_2" 0 "PERS_1" ;
VAL_ 1123 GpsUtcYr_No_Actl 31 "Fault" ;
VAL_ 1123 GpsUtcMnth_No_Actl 15 "Fault" ;
VAL_ 1123 GPS_UTC_seconds 63 "Fault" 62 "Unknown" ;
VAL_ 1123 GPS_UTC_minutes 63 "Fault" 62 "Unknown" ;
VAL_ 1123 GPS_UTC_hours 31 "Invalid" 30 "Unknown" ;
VAL_ 1123 GPS_Compass_direction 7 "NorthWest" 6 "West" 5 "SouthWest" 4 "South" 3 "SouthEast" 2 "East" 1 "NorthEast" 0 "North" ;
VAL_ 1123 GPS_Actual_vs_Infer_pos 1 "Inferred_Position" 0 "Actual_Postition" ;
VAL_ 1123 Gps_B_Falt 1 "Yes" 0 "No" ;
VAL_ 1123 GPS_Pdop 31 "Invalid" 30 "Unknown" ;
VAL_ 1122 GPS_Longitude_Minutes 63 "Fault" 62 "Unknown" ;
VAL_ 1122 GPS_Longitude_Min_dec 16383 "Invalid" 16382 "Unknown" ;
VAL_ 1122 GPS_Longitude_Degrees 511 "Fault" 510 "Unknown" ;
VAL_ 1122 GPS_Latitude_Minutes 63 "Fault" 62 "Unknown" ;
VAL_ 1122 GPS_Latitude_Min_dec 16383 "Invalid" 16382 "Unknown" ;
VAL_ 1122 GPS_Latitude_Degrees 255 "Invalid" 254 "Unknown" ;
VAL_ 1122 GpsHsphLongEast_D_Actl 0 "Invalid" 1 "Eastern" 2 "Western" 3 "Fault" ;
VAL_ 1122 GpsHsphLattSth_D_Actl 3 "Fault" 2 "Northern" 1 "Southern" 0 "Invalid" ;
VAL_ 1003 PersRecallSrc_D_Actl 7 "NotUsed_3" 6 "NotUsed_2" 5 "NotUsed_1" 4 "MemorySwitch" 3 "RemoteStart" 2 "KeyFob" 1 "CenterStack" 0 "Null" ;
VAL_ 1003 Pers4Key_D_Stat 3 "NotUsed_1" 2 "KeyUnAssociated" 1 "KeyAssociated" 0 "Null" ;
VAL_ 1003 Pers3Key_D_Stat 3 "NotUsed_1" 2 "KeyUnAssociated" 1 "KeyAssociated" 0 "Null" ;
VAL_ 1003 Pers2Key_D_Stat 3 "NotUsed_1" 2 "KeyUnAssociated" 1 "KeyAssociated" 0 "Null" ;
VAL_ 1003 Pers1Key_D_Stat 3 "NotUsed_1" 2 "KeyUnAssociated" 1 "KeyAssociated" 0 "Null" ;
VAL_ 1003 EmPrflNo_D_Stat 7 "NotUsed_3" 6 "NotUsed_2" 5 "NotUsed_1" 4 "Pers4" 3 "Pers3" 2 "Pers2" 1 "Pers1" 0 "Null" ;
VAL_ 1003 EmPrflKeyAssoc_D_Stat 7 "WrongDevice" 6 "KeyAssociateFailed" 5 "KeyAssociateSuccess" 4 "KeyAlreadyInUse" 3 "KeyDisassociated" 2 "KeyAssociationExited" 1 "KeyAssociationEntered" 0 "Null" ;
VAL_ 1003 VehKeyActv_D_Stat 15 "NotUsed7" 14 "NotUsed6" 13 "NotUsed5" 12 "NotUsed4" 11 "NotUsed3" 10 "NotUsed2" 9 "NotUsed1" 8 "Key8Active" 7 "Key7Active" 6 "Key6Active" 5 "Key5Active" 4 "Key4Active" 3 "Key3Active" 2 "Key2Active" 1 "Key1Active" 0 "NoKeyActive" ;
VAL_ 1003 PersNoPos_D_Actl 7 "Unused_3" 6 "Unused_2" 5 "Unused_1" 4 "Vehicle" 3 "PERS_4" 2 "PERS_3" 1 "PERS_2" 0 "PERS_1" ;
VAL_ 1003 PersSetupRestr_D_Actl 3 "Non_Moveable_Person" 2 "Moveable_Person" 1 "Vehicle" 0 "Factory" ;
VAL_ 1003 PersSetupAccessCtrl 1 "Limited" 0 "Full" ;
VAL_ 1003 PersConflict_D_Actl 1 "Conflict" 0 "No_Conflict" ;
VAL_ 1003 AssocConfirm_D_Actl 0 "None" 7 "Associate" 6 "Keycode_Rejected" 5 "Keycode_Accepted" 4 "In_Progress" 3 "Erase" 2 "Duplicate" 1 "Disassociate" ;
VAL_ 1003 PersNo_D_Actl 7 "Unused_3" 6 "Unused_2" 5 "NotDetermined" 4 "Vehicle" 3 "PERS_4" 2 "PERS_3" 1 "PERS_2" 0 "PERS_1" ;
VAL_ 994 PersStore_D_Rq 7 "Unused_2" 6 "Unused_1" 5 "Vehicle" 4 "PERS_4" 3 "PERS_3" 2 "PERS_2" 1 "PERS_1" 0 "Null" ;
VAL_ 994 Pers4OptIn_B_Stats 1 "OPTED_IN" 0 "NOT_OPTED_IN" ;
VAL_ 994 Pers3OptIn_B_Stats 1 "OPTED_IN" 0 "NOT_OPTED_IN" ;
VAL_ 994 Pers2OptIn_B_Stats 1 "OPTED_IN" 0 "NOT_OPTED_IN" ;
VAL_ 994 Pers1OptIn_B_Stats 1 "OPTED_IN" 0 "NOT_OPTED_IN" ;
VAL_ 994 CtrStkPersIndex_D_Actl 7 "Unused_3" 6 "Unused_2" 5 "Unused_1" 4 "Vehicle" 3 "PERS_4" 2 "PERS_3" 1 "PERS_2" 0 "PERS_1" ;
VAL_ 994 CtrStkDsplyOp_D_Rq 7 "Unused_2" 6 "Unused_1" 5 "Copy" 4 "Restore" 3 "Upload" 2 "Set" 1 "Query" 0 "Null" ;
